VERSION "dbc-export 1 2026.26.6.5"

NS_ :

BS_:

BU_: APP APS BMS CC CMP CMPD CP DAS DI DIF DIR EPBL EPBR EVSE FC GTW HCML HCMR HVP ICR PCS PCS2 PLG PM PMF PMR PTC SCCM SCM SCS SDCR TAS UMC V2G VC VCBATT VCBATT0 VCBATT1 VCBATT2 VCFRONT VCFRONT1 VCFRONT2 VCLEFT VCRIGHT VCSEAT2L VCSEAT2R VCSEC

BO_ 914 BMS_packConfig: 8 BMS
 SG_ BMS_packConfigMultiplexer M : 0|8@1+ (1,0) [0|255] "" Vector__XXX
 SG_ BMS_reservedConfig_0 m0 : 8|6@1+ (1,0) [0|63] "" Vector__XXX
 SG_ BMS_moduleType m1 : 8|3@1+ (1,0) [0|7] "" Vector__XXX
 SG_ BMS_thermalPackType m1 : 11|4@1+ (1,0) [0|15] "" Vector__XXX
 SG_ BMS_packMass m1 : 16|8@1+ (1,300) [342|540] "kg" Vector__XXX
 SG_ BMS_platformMaxBusVoltage m1 : 24|10@1+ (1,300) [300|1300] "V" Vector__XXX
 SG_ BMS_standbySupplyContinuousPower m1 : 36|2@1+ (1,0) [0|3] "" Vector__XXX
 SG_ BMS_beginningOfLifePackEnergy m1 : 40|10@1+ (0.1,0) [0|102.2] "KWh" Vector__XXX

BO_ 1810 BMS_packTemperatureMeasurements: 8 BMS
 SG_ BMS_packTemperatureMultiplexer M : 0|8@1+ (1,0) [0|255] "" Vector__XXX
 SG_ BMS_packTemperatureCounter : 14|2@1+ (1,0) [0|3] "" Vector__XXX
 SG_ BMS_packTemperatureStatus1 m0 : 8|2@1+ (1,0) [0|3] "" Vector__XXX
 SG_ BMS_packTemperatureStatus2 m0 : 10|2@1+ (1,0) [0|3] "" Vector__XXX
 SG_ BMS_packTemperatureStatus3 m0 : 12|2@1+ (1,0) [0|3] "" Vector__XXX
 SG_ BMS_packTemperature1 m0 : 16|16@1- (0.01,0) [-327.68|327.67] "C" Vector__XXX
 SG_ BMS_packTemperature2 m0 : 32|16@1- (0.01,0) [-327.68|327.67] "C" Vector__XXX
 SG_ BMS_packTemperature3 m0 : 48|16@1- (0.01,0) [-327.68|327.67] "C" Vector__XXX
 SG_ BMS_packTemperatureStatus4 m1 : 8|2@1+ (1,0) [0|3] "" Vector__XXX
 SG_ BMS_packTemperatureStatus5 m1 : 10|2@1+ (1,0) [0|3] "" Vector__XXX
 SG_ BMS_packTemperatureStatus6 m1 : 12|2@1+ (1,0) [0|3] "" Vector__XXX
 SG_ BMS_packTemperature4 m1 : 16|16@1- (0.01,0) [-327.68|327.67] "C" Vector__XXX
 SG_ BMS_packTemperature5 m1 : 32|16@1- (0.01,0) [-327.68|327.67] "C" Vector__XXX
 SG_ BMS_packTemperature6 m1 : 48|16@1- (0.01,0) [-327.68|327.67] "C" Vector__XXX
 SG_ BMS_packTemperatureStatus7 m2 : 8|2@1+ (1,0) [0|3] "" Vector__XXX
 SG_ BMS_packTemperatureStatus8 m2 : 10|2@1+ (1,0) [0|3] "" Vector__XXX
 SG_ BMS_packTemperatureStatus9 m2 : 12|2@1+ (1,0) [0|3] "" Vector__XXX
 SG_ BMS_packTemperature7 m2 : 16|16@1- (0.01,0) [-327.68|327.67] "C" Vector__XXX
 SG_ BMS_packTemperature8 m2 : 32|16@1- (0.01,0) [-327.68|327.67] "C" Vector__XXX
 SG_ BMS_packTemperature9 m2 : 48|16@1- (0.01,0) [-327.68|327.67] "C" Vector__XXX
 SG_ BMS_packTemperatureStatus10 m3 : 8|2@1+ (1,0) [0|3] "" Vector__XXX
 SG_ BMS_packTemperatureStatus11 m3 : 10|2@1+ (1,0) [0|3] "" Vector__XXX
 SG_ BMS_packTemperatureStatus12 m3 : 12|2@1+ (1,0) [0|3] "" Vector__XXX
 SG_ BMS_packTemperature10 m3 : 16|16@1- (0.01,0) [-327.68|327.67] "C" Vector__XXX
 SG_ BMS_packTemperature11 m3 : 32|16@1- (0.01,0) [-327.68|327.67] "C" Vector__XXX
 SG_ BMS_packTemperature12 m3 : 48|16@1- (0.01,0) [-327.68|327.67] "C" Vector__XXX
 SG_ BMS_packTemperatureStatus13 m4 : 8|2@1+ (1,0) [0|3] "" Vector__XXX
 SG_ BMS_packTemperatureStatus14 m4 : 10|2@1+ (1,0) [0|3] "" Vector__XXX
 SG_ BMS_packTemperatureStatus15 m4 : 12|2@1+ (1,0) [0|3] "" Vector__XXX
 SG_ BMS_packTemperature13 m4 : 16|16@1- (0.01,0) [-327.68|327.67] "C" Vector__XXX
 SG_ BMS_packTemperature14 m4 : 32|16@1- (0.01,0) [-327.68|327.67] "C" Vector__XXX
 SG_ BMS_packTemperature15 m4 : 48|16@1- (0.01,0) [-327.68|327.67] "C" Vector__XXX
 SG_ BMS_packTemperatureStatus16 m5 : 8|2@1+ (1,0) [0|3] "" Vector__XXX
 SG_ BMS_packTemperatureStatus17 m5 : 10|2@1+ (1,0) [0|3] "" Vector__XXX
 SG_ BMS_packTemperatureStatus18 m5 : 12|2@1+ (1,0) [0|3] "" Vector__XXX
 SG_ BMS_packTemperature16 m5 : 16|16@1- (0.01,0) [-327.68|327.67] "C" Vector__XXX
 SG_ BMS_packTemperature17 m5 : 32|16@1- (0.01,0) [-327.68|327.67] "C" Vector__XXX
 SG_ BMS_packTemperature18 m5 : 48|16@1- (0.01,0) [-327.68|327.67] "C" Vector__XXX

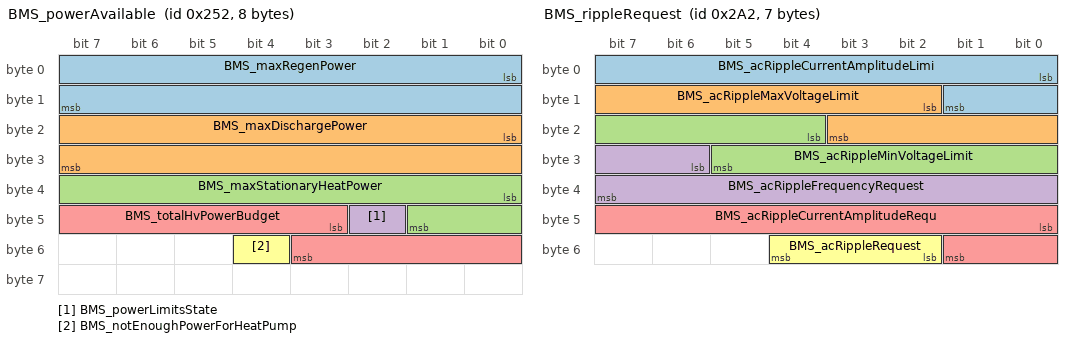
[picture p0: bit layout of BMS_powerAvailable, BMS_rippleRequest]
BO_ 594 BMS_powerAvailable: 8 BMS
 SG_ BMS_maxRegenPower : 0|16@1+ (0.01,0) [0|655.35] "kW" Vector__XXX
 SG_ BMS_maxDischargePower : 16|16@1+ (0.013,0) [0|850] "kW" Vector__XXX
 SG_ BMS_maxStationaryHeatPower : 32|10@1+ (0.01,0) [0|10.23] "kW" Vector__XXX
 SG_ BMS_powerLimitsState : 42|1@1+ (1,0) [0|1] "" Vector__XXX
 SG_ BMS_totalHvPowerBudget : 43|9@1+ (0.1,0) [0|51.1] "kW" Vector__XXX
 SG_ BMS_notEnoughPowerForHeatPump : 52|1@1+ (1,0) [0|1] "" Vector__XXX

BO_ 674 BMS_rippleRequest: 7 BMS
 SG_ BMS_acRippleCurrentAmplitudeLimi : 0|10@1+ (1,0) [0|1023] "A" Vector__XXX
 SG_ BMS_acRippleMaxVoltageLimit : 10|10@1+ (1,0) [0|1023] "V" Vector__XXX
 SG_ BMS_acRippleMinVoltageLimit : 20|10@1+ (1,0) [0|1023] "V" Vector__XXX
 SG_ BMS_acRippleFrequencyRequest : 30|10@1+ (1,0) [0|1022] "Hz" Vector__XXX
 SG_ BMS_acRippleCurrentAmplitudeRequ : 40|10@1+ (1,0) [0|1023] "A" Vector__XXX
 SG_ BMS_acRippleRequest : 50|3@1+ (1,0) [0|7] "" Vector__XXX

BO_ 1834 BMS_serialNumber: 8 BMS
 SG_ BMS_serialNumberMultiplexer M : 0|2@1+ (1,0) [0|2] "" Vector__XXX
 SG_ BMS_packSerialNumberByte01 m0 : 8|8@1+ (1,0) [0|255] "" Vector__XXX
 SG_ BMS_packSerialNumberByte02 m0 : 16|8@1+ (1,0) [0|255] "" Vector__XXX
 SG_ BMS_packSerialNumberByte03 m0 : 24|8@1+ (1,0) [0|255] "" Vector__XXX
 SG_ BMS_packSerialNumberByte04 m0 : 32|8@1+ (1,0) [0|255] "" Vector__XXX
 SG_ BMS_packSerialNumberByte05 m0 : 40|8@1+ (1,0) [0|255] "" Vector__XXX
 SG_ BMS_packSerialNumberByte06 m0 : 48|8@1+ (1,0) [0|255] "" Vector__XXX
 SG_ BMS_packSerialNumberByte07 m0 : 56|8@1+ (1,0) [0|255] "" Vector__XXX
 SG_ BMS_packSerialNumberByte08 m1 : 8|8@1+ (1,0) [0|255] "" Vector__XXX
 SG_ BMS_packSerialNumberByte09 m1 : 16|8@1+ (1,0) [0|255] "" Vector__XXX
 SG_ BMS_packSerialNumberByte10 m1 : 24|8@1+ (1,0) [0|255] "" Vector__XXX
 SG_ BMS_packSerialNumberByte11 m1 : 32|8@1+ (1,0) [0|255] "" Vector__XXX
 SG_ BMS_packSerialNumberByte12 m1 : 40|8@1+ (1,0) [0|255] "" Vector__XXX
 SG_ BMS_packSerialNumberByte13 m1 : 48|8@1+ (1,0) [0|255] "" Vector__XXX
 SG_ BMS_packSerialNumberByte14 m1 : 56|8@1+ (1,0) [0|255] "" Vector__XXX
 SG_ BMS_packSerialBirthDateBinned m2 : 8|32@1+ (1,0) [0|4294967295] "" Vector__XXX

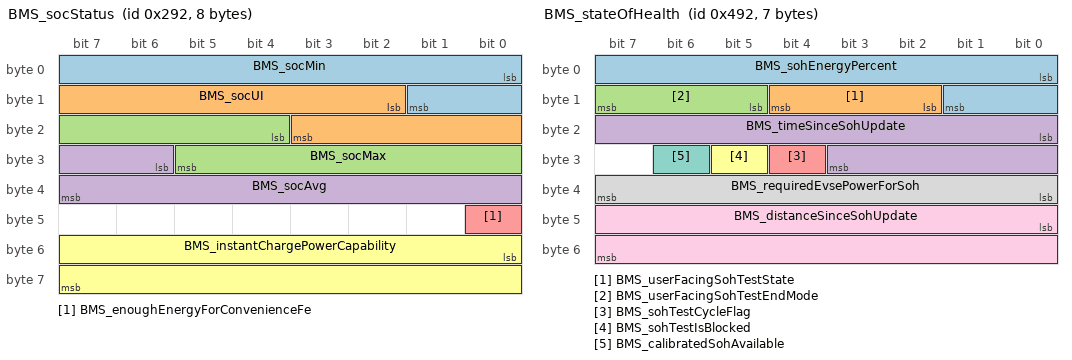
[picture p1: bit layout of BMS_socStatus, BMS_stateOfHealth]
BO_ 658 BMS_socStatus: 8 BMS
 SG_ BMS_socMin : 0|10@1+ (0.1,0) [0|102.2] "%" Vector__XXX
 SG_ BMS_socUI : 10|10@1+ (0.1,0) [0|100] "%" Vector__XXX
 SG_ BMS_socMax : 20|10@1+ (0.1,0) [0|102.2] "%" Vector__XXX
 SG_ BMS_socAvg : 30|10@1+ (0.1,0) [0|102.2] "%" Vector__XXX
 SG_ BMS_enoughEnergyForConvenienceFe : 40|1@1+ (1,0) [0|1] "" Vector__XXX
 SG_ BMS_instantChargePowerCapability : 48|16@1+ (0.05,0) [0|3276.7] "kW" Vector__XXX

BO_ 1170 BMS_stateOfHealth: 7 BMS
 SG_ BMS_sohEnergyPercent : 0|10@1+ (0.1,0) [0|100] "%" Vector__XXX
 SG_ BMS_userFacingSohTestState : 10|3@1+ (1,0) [0|7] "" Vector__XXX
 SG_ BMS_userFacingSohTestEndMode : 13|3@1+ (1,0) [0|7] "" Vector__XXX
 SG_ BMS_timeSinceSohUpdate : 16|12@1+ (1,0) [0|3650] "days" Vector__XXX
 SG_ BMS_sohTestCycleFlag : 28|1@1+ (1,0) [0|1] "" Vector__XXX
 SG_ BMS_sohTestIsBlocked : 29|1@1+ (1,0) [0|1] "" Vector__XXX
 SG_ BMS_calibratedSohAvailable : 30|1@1+ (1,0) [0|1] "" Vector__XXX
 SG_ BMS_requiredEvsePowerForSoh : 32|8@1+ (0.125,0) [0|31.75] "kW" Vector__XXX
 SG_ BMS_distanceSinceSohUpdate : 40|16@1+ (1,0) [0|65534] "km" Vector__XXX

BO_ 530 BMS_status: 8 BMS
 SG_ BMS_hvacPowerRequest : 0|1@1+ (1,0) [0|1] "" Vector__XXX
 SG_ BMS_notEnoughPowerForDrive : 1|1@1+ (1,0) [0|1] "" Vector__XXX
 SG_ BMS_notEnoughPowerForSupport : 2|1@1+ (1,0) [0|1] "" Vector__XXX
 SG_ BMS_preconditionAllowed : 3|1@1+ (1,0) [0|1] "" Vector__XXX
 SG_ BMS_updateAllowed : 4|1@1+ (1,0) [0|1] "" Vector__XXX
 SG_ BMS_cpMiaOnHvs : 5|1@1+ (1,0) [0|1] "" Vector__XXX
 SG_ BMS_pcsPwmEnabled : 6|1@1+ (1,0) [0|1] "" Vector__XXX
 SG_ BMS_contactorState : 8|3@1+ (1,0) [1|7] "" Vector__XXX
 SG_ BMS_userChargeStatus : 11|3@1+ (1,0) [0|7] "" Vector__XXX
 SG_ BMS_batteryInputPower : 14|16@1+ (0.05,0) [0|3276.7] "kW" Vector__XXX
 SG_ BMS_chargeRequest : 30|1@1+ (1,0) [0|1] "" Vector__XXX
 SG_ BMS_state : 32|4@1+ (1,0) [0|15] "" Vector__XXX
 SG_ BMS_diLimpRequest : 36|1@1+ (1,0) [0|1] "" Vector__XXX
 SG_ BMS_okToShipByAir : 37|1@1+ (1,0) [0|1] "" Vector__XXX
 SG_ BMS_okToShipByLand : 38|1@1+ (1,0) [0|1] "" Vector__XXX
 SG_ BMS_chgPowerAvailable : 39|12@1+ (0.125,0) [0|511.75] "kW" Vector__XXX
 SG_ BMS_acManagerState : 52|4@1+ (1,0) [0|15] "" Vector__XXX
 SG_ BMS_conditioningRequest : 56|1@1+ (1,0) [0|1] "" Vector__XXX
 SG_ BMS_smStateRequest : 57|4@1+ (1,0) [0|15] "" Vector__XXX
 SG_ BMS_hvState : 61|3@1+ (1,0) [0|7] "" Vector__XXX

BO_ 786 BMS_thermalStatus: 8 BMS
 SG_ BMS_thermalStatusMultiplexer M : 0|2@1+ (1,0) [0|3] "" Vector__XXX
 SG_ BMS_inletActiveCoolTargetT m0 : 2|9@1+ (0.25,-25) [-25|100] "DegC" Vector__XXX
 SG_ BMS_inletPassiveTargetT m0 : 11|9@1+ (0.25,-25) [-25|100] "DegC" Vector__XXX
 SG_ BMS_inletActiveHeatTargetT m0 : 20|9@1+ (0.25,-25) [-25|100] "DegC" Vector__XXX
 SG_ BMS_requestDischarge m0 : 29|1@1+ (1,0) [0|1] "" Vector__XXX
 SG_ BMS_activeHeatingWorthwhile m0 : 30|1@1+ (1,0) [0|1] "" Vector__XXX
 SG_ BMS_pcsNoFlowRequest m0 : 31|1@1+ (1,0) [0|1] "" Vector__XXX
 SG_ BMS_minPackTemperature m0 : 32|10@1+ (0.2,-40) [-40|164.6] "DegC" Vector__XXX
 SG_ BMS_noFlowRequest m0 : 42|1@1+ (1,0) [0|1] "" Vector__XXX
 SG_ BMS_maxPackTemperature m0 : 43|11@1+ (0.1,-40) [-40|164.7] "DegC" Vector__XXX
 SG_ BMS_flowRequest m0 : 56|8@1+ (0.25,0) [0|60] "LPM" Vector__XXX
 SG_ BMS_coldStagnationLimit m1 : 2|9@1+ (0.25,-25) [-25|100] "DegC" Vector__XXX
 SG_ BMS_hotStagnationLimit m1 : 11|9@1+ (0.25,-25) [-25|100] "DegC" Vector__XXX
 SG_ BMS_hotCellTempLimit m1 : 20|9@1+ (0.25,-25) [-25|100] "DegC" Vector__XXX
 SG_ BMS_i2tDeratingEnabled m1 : 29|1@1+ (1,0) [0|1] "" Vector__XXX
 SG_ BMS_activeCoolCellReferenceT m1 : 32|9@1+ (0.25,-25) [-25|100] "DegC" Vector__XXX
 SG_ BMS_activeHeatCellTargetT m1 : 41|9@1+ (0.25,-25) [-25|100] "DegC" Vector__XXX
 SG_ BMS_powerDissipation m1 : 50|10@1+ (0.02,0) [0|20] "kW" Vector__XXX

BO_ 1554 BMS_udsResponse: 8 BMS
 SG_ BMS_udsResponseData : 7|64@0+ (1,0) [0|1.84467440737e+19] "" Vector__XXX

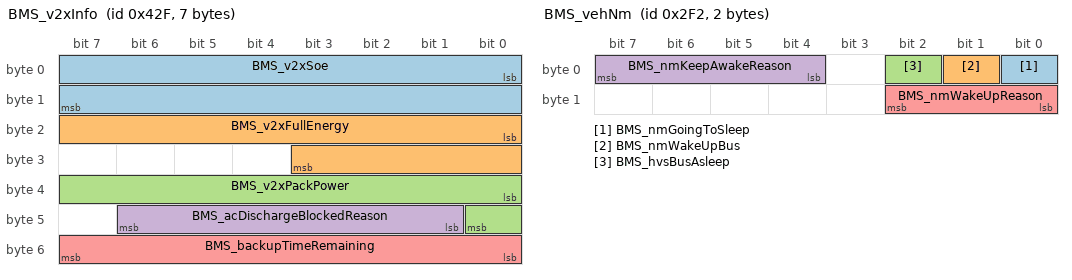
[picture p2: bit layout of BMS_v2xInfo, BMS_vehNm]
BO_ 1071 BMS_v2xInfo: 7 BMS
 SG_ BMS_v2xSoe : 0|16@1+ (0.002,0) [0|100] "%" Vector__XXX
 SG_ BMS_v2xFullEnergy : 16|12@1+ (0.05,0) [0|200] "kWh" Vector__XXX
 SG_ BMS_v2xPackPower : 32|9@1+ (0.1,-25) [-25|25] "kW" Vector__XXX
 SG_ BMS_acDischargeBlockedReason : 41|6@1+ (1,0) [0|63] "" Vector__XXX
 SG_ BMS_backupTimeRemaining : 48|8@1+ (1,0) [0|254] "Hours" Vector__XXX

BO_ 754 BMS_vehNm: 2 BMS
 SG_ BMS_nmGoingToSleep : 0|1@1+ (1,0) [0|1] "" Vector__XXX
 SG_ BMS_nmWakeUpBus : 1|1@1+ (1,0) [0|1] "" Vector__XXX
 SG_ BMS_hvsBusAsleep : 2|1@1+ (1,0) [0|1] "" Vector__XXX
 SG_ BMS_nmKeepAwakeReason : 4|4@1+ (1,0) [1|15] "" Vector__XXX
 SG_ BMS_nmWakeUpReason : 8|3@1+ (1,0) [0|7] "" Vector__XXX

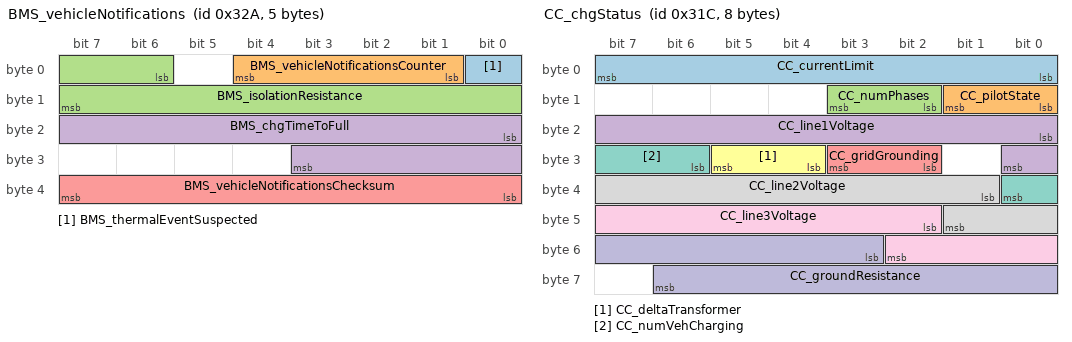
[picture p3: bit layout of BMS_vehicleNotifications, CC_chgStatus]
BO_ 810 BMS_vehicleNotifications: 5 BMS
 SG_ BMS_thermalEventSuspected : 0|1@1+ (1,0) [0|1] "" Vector__XXX
 SG_ BMS_vehicleNotificationsCounter : 1|4@1+ (1,0) [0|15] "" Vector__XXX
 SG_ BMS_isolationResistance : 6|10@1+ (10,0) [0|10000] "kOhm" Vector__XXX
 SG_ BMS_chgTimeToFull : 16|12@1+ (0.01666667,0) [0|68.23334698] "Hours" Vector__XXX
 SG_ BMS_vehicleNotificationsChecksum : 32|8@1+ (1,0) [0|255] "" Vector__XXX

BO_ 1116 CC_alertLog: 8 CC
 SG_ CC_alertID M : 0|15@1+ (1,0) [0|32767] "" Vector__XXX
 SG_ CC_alertType : 15|1@1+ (1,0) [0|1] "" Vector__XXX
 SG_ CC_a001_groundResistance m1 : 16|12@1+ (1000,0) [0|4094000] "Ohm" Vector__XXX
 SG_ CC_a003_gfciRmsCurrent m3 : 16|12@1+ (0.001,0) [0|4.095] "A" Vector__XXX
 SG_ CC_a003_gfciRmsCurrentAvg m3 : 28|12@1+ (0.001,0) [0|4.095] "A" Vector__XXX
 SG_ CC_a003_dcGfciCurrent m3 : 40|10@1- (0.001,0) [-0.512|0.511] "A" Vector__XXX
 SG_ CC_a003_gfciFaultReason m3 : 50|4@1+ (1,0) [1|15] "" Vector__XXX
 SG_ CC_a003_gfciFaultBucket m3 : 56|4@1+ (1,0) [0|15] "" Vector__XXX
 SG_ CC_a004_gfciErrorReason m4 : 16|8@1+ (1,0) [1|255] "" Vector__XXX
 SG_ CC_a004_gfciAsicErrorBitfield m4 : 24|8@1+ (1,0) [0|255] "" Vector__XXX
 SG_ CC_a004_gfciSelfTestDuty m4 : 32|16@1- (0.0001,50) [46.7232|53.2767] "A" Vector__XXX
 SG_ CC_a004_gfciSelfTestCurrent m4 : 48|16@1- (0.0001,0) [-3.2768|3.2767] "A" Vector__XXX
 SG_ CC_a006_line1Current m6 : 16|16@1+ (0.01,0) [0|655.35] "A" Vector__XXX
 SG_ CC_a006_line2Current m6 : 32|16@1+ (0.01,0) [0|655.35] "A" Vector__XXX
 SG_ CC_a006_line3Current m6 : 48|16@1+ (0.01,0) [0|655.35] "A" Vector__XXX
 SG_ CC_a007_inputVoltage m7 : 16|16@1+ (0.01,0) [0|655.35] "V" Vector__XXX
 SG_ CC_a007_inputLineVoltage m7 : 32|16@1+ (0.01,0) [0|655.35] "V" Vector__XXX
 SG_ CC_a007_inputNeutralVoltage m7 : 48|16@1+ (0.01,0) [0|655.35] "V" Vector__XXX
 SG_ CC_a008_inputVoltage m8 : 16|16@1+ (0.01,0) [0|655.35] "V" Vector__XXX
 SG_ CC_a008_inputLineVoltage m8 : 32|16@1+ (0.01,0) [0|655.35] "V" Vector__XXX
 SG_ CC_a008_inputNeutralVoltage m8 : 48|16@1+ (0.01,0) [0|655.35] "V" Vector__XXX
 SG_ CC_a010_line1Voltage m10 : 16|12@1+ (0.1,0) [0|409.5] "V" Vector__XXX
 SG_ CC_a010_line2Voltage m10 : 28|12@1+ (0.1,0) [0|409.5] "V" Vector__XXX
 SG_ CC_a010_line3Voltage m10 : 40|12@1+ (0.1,0) [0|409.5] "V" Vector__XXX
 SG_ CC_a010_line1StuckClosed m10 : 52|1@1+ (1,0) [0|1] "" Vector__XXX
 SG_ CC_a010_line2StuckClosed m10 : 53|1@1+ (1,0) [0|1] "" Vector__XXX
 SG_ CC_a010_line3StuckClosed m10 : 54|1@1+ (1,0) [0|1] "" Vector__XXX
 SG_ CC_a011_pcbaTemp m11 : 16|9@1- (1,88) [-168|343] "DegC" Vector__XXX
 SG_ CC_a012_inputThermopile m12 : 16|12@1+ (1.0e-06,0) [0|0.004095] "V" Vector__XXX
 SG_ CC_a012_inputThermopileDvdt m12 : 28|12@1+ (1.0e-06,0) [0|0.004095] "V/sec" Vector__XXX
 SG_ CC_a013_handleTemp m13 : 16|9@1- (1,88) [-168|343] "DegC" Vector__XXX
 SG_ CC_a014_failureCause m14 : 16|9@1+ (1,0) [0|511] "" Vector__XXX
 SG_ CC_a014_meterFaultAddress m14 : 25|16@1+ (1,0) [0|65535] "" Vector__XXX
 SG_ CC_a014_meterFaultData m14 : 41|16@1+ (1,0) [0|65535] "" Vector__XXX
 SG_ CC_a014_meterRetryCount m14 : 57|4@1+ (1,0) [0|15] "" Vector__XXX
 SG_ CC_a015_pilotHighVolage m15 : 16|16@1+ (0.001,0) [0|65.535] "V" Vector__XXX
 SG_ CC_a015_smState m15 : 32|8@1+ (1,0) [0|255] "" Vector__XXX
 SG_ CC_a027_handleTemperature m27 : 16|12@1- (0.1,0) [-204.8|204.7] "DegC" Vector__XXX
 SG_ CC_a027_handleTempFaultReason m27 : 28|4@1+ (1,0) [0|15] "" Vector__XXX
 SG_ CC_a032_meteringSpiCommsFailure m32 : 16|1@1+ (1,0) [0|1] "" Vector__XXX
 SG_ CC_a032_meteringConfigMismatch m32 : 17|1@1+ (1,0) [0|1] "" Vector__XXX
 SG_ CC_a033_nominalVoltage m33 : 16|9@1+ (0.01,0) [0|5.11] "V" Vector__XXX
 SG_ CC_a033_measuredVoltage m33 : 25|9@1+ (0.01,0) [0|5.11] "V" Vector__XXX
 SG_ CC_a036_line1Voltage m36 : 16|12@1+ (0.1,0) [0|409.5] "V" Vector__XXX
 SG_ CC_a036_line2Voltage m36 : 28|12@1+ (0.1,0) [0|409.5] "V" Vector__XXX
 SG_ CC_a036_line3Voltage m36 : 40|12@1+ (0.1,0) [0|409.5] "V" Vector__XXX
 SG_ CC_a036_line1StuckOpen m36 : 52|1@1+ (1,0) [0|1] "" Vector__XXX
 SG_ CC_a036_line2StuckOpen m36 : 53|1@1+ (1,0) [0|1] "" Vector__XXX
 SG_ CC_a036_line3StuckOpen m36 : 54|1@1+ (1,0) [0|1] "" Vector__XXX
 SG_ CC_a037_expiredWatchdogModuleId m37 : 16|8@1+ (1,0) [0|255] "" Vector__XXX
 SG_ CC_a037_expiredWatchdogTaskId m37 : 24|8@1+ (1,0) [0|255] "" Vector__XXX
 SG_ CC_a037_expiredWatchdogAppCRC m37 : 32|32@1+ (1,0) [0|4294967295] "" Vector__XXX
 SG_ CC_a038_moduleMiaModuleId m38 : 16|8@1+ (1,0) [0|255] "" Vector__XXX
 SG_ CC_a038_moduleMiaTaskId m38 : 24|8@1+ (1,0) [0|255] "" Vector__XXX
 SG_ CC_a038_moduleMiaAppCRC m38 : 32|32@1+ (1,0) [0|4294967295] "" Vector__XXX
 SG_ CC_a039_intModuleTemperature m39 : 16|9@1- (1,88) [-168|343] "DegC" Vector__XXX
 SG_ CC_a040_handleTemperature m40 : 16|9@1- (1,88) [-168|343] "DegC" Vector__XXX
 SG_ CC_a041_inputThermopile m41 : 16|16@1- (1.0e-06,0) [-0.032768|0.032767] "V" Vector__XXX
 SG_ CC_a041_inputThermopileDvdt m41 : 32|16@1- (1.0e-06,0) [-0.032768|0.032767] "V/sec" Vector__XXX
 SG_ CC_a042_pcbaTemperature m42 : 16|9@1- (1,88) [-168|343] "DegC" Vector__XXX
 SG_ CC_a044_relayCoilVoltage m44 : 16|8@1+ (0.14,0) [0|35.7] "V" Vector__XXX
 SG_ CC_a044_pcbaTemperature m44 : 24|9@1- (1,88) [-168|343] "DegC" Vector__XXX

BO_ 1132 CC_alertMatrix1: 8 CC
 SG_ CC_a001_gndMonIntrptLineSide : 0|1@1+ (1,0) [0|1] "" Vector__XXX
 SG_ CC_a002_gndMonIntrptLoadSide : 1|1@1+ (1,0) [0|1] "" Vector__XXX
 SG_ CC_a003_CCIDTripped : 2|1@1+ (1,0) [0|1] "" Vector__XXX
 SG_ CC_a004_CCIDSelfTestFault : 3|1@1+ (1,0) [0|1] "" Vector__XXX
 SG_ CC_a005_groundedNeutral : 4|1@1+ (1,0) [0|1] "" Vector__XXX
 SG_ CC_a006_inputOverCurrent : 5|1@1+ (1,0) [0|1] "" Vector__XXX
 SG_ CC_a007_inputOverVoltage : 6|1@1+ (1,0) [0|1] "" Vector__XXX
 SG_ CC_a008_inputUnderVoltage : 7|1@1+ (1,0) [0|1] "" Vector__XXX
 SG_ CC_a009_inputMiswired : 8|1@1+ (1,0) [0|1] "" Vector__XXX
 SG_ CC_a010_contactorWelded : 9|1@1+ (1,0) [0|1] "" Vector__XXX
 SG_ CC_a011_ambientOT : 10|1@1+ (1,0) [0|1] "" Vector__XXX
 SG_ CC_a012_wallPlugOT : 11|1@1+ (1,0) [0|1] "" Vector__XXX
 SG_ CC_a013_vehConnOT : 12|1@1+ (1,0) [0|1] "" Vector__XXX
 SG_ CC_a014_mcuSelfTestFault : 13|1@1+ (1,0) [0|1] "" Vector__XXX
 SG_ CC_a015_PilotAFault : 14|1@1+ (1,0) [0|1] "" Vector__XXX
 SG_ CC_a016_PilotBFault : 15|1@1+ (1,0) [0|1] "" Vector__XXX
 SG_ CC_a017_PilotCFault : 16|1@1+ (1,0) [0|1] "" Vector__XXX
 SG_ CC_a018_PilotDFault : 17|1@1+ (1,0) [0|1] "" Vector__XXX
 SG_ CC_a019_proxDisconnected : 18|1@1+ (1,0) [0|1] "" Vector__XXX
 SG_ CC_a020_3vRailIncorrect : 19|1@1+ (1,0) [0|1] "" Vector__XXX
 SG_ CC_a021_CB_noMaster : 20|1@1+ (1,0) [0|1] "" Vector__XXX
 SG_ CC_a022_CB_tooManyMasters : 21|1@1+ (1,0) [0|1] "" Vector__XXX
 SG_ CC_a023_CB_tooManySlaves : 22|1@1+ (1,0) [0|1] "" Vector__XXX
 SG_ CC_a024_CB_masterISetTooLow : 23|1@1+ (1,0) [0|1] "" Vector__XXX
 SG_ CC_a025_evseTemp : 24|1@1+ (1,0) [0|1] "" Vector__XXX
 SG_ CC_a026_wallPlugTemp : 25|1@1+ (1,0) [0|1] "" Vector__XXX
 SG_ CC_a027_vehicleHandleTemp : 26|1@1+ (1,0) [0|1] "" Vector__XXX
 SG_ CC_a028_CB_rotarySelect : 27|1@1+ (1,0) [0|1] "" Vector__XXX
 SG_ CC_a029_PilotFFault : 28|1@1+ (1,0) [0|1] "" Vector__XXX
 SG_ CC_a030_masterSlaveMismatch : 29|1@1+ (1,0) [0|1] "" Vector__XXX
 SG_ CC_a031_pllLockLost : 30|1@1+ (1,0) [0|1] "" Vector__XXX
 SG_ CC_a032_meteringFailure : 31|1@1+ (1,0) [0|1] "" Vector__XXX
 SG_ CC_a033_vRefOutOfRange : 32|1@1+ (1,0) [0|1] "" Vector__XXX
 SG_ CC_a034_bootAlert : 33|1@1+ (1,0) [0|1] "" Vector__XXX
 SG_ CC_a035_CCIDCalibration : 34|1@1+ (1,0) [0|1] "" Vector__XXX
 SG_ CC_a036_contactorStuckOpen : 35|1@1+ (1,0) [0|1] "" Vector__XXX
 SG_ CC_a037_internalModuleWatchdogEx : 36|1@1+ (1,0) [0|1] "" Vector__XXX
 SG_ CC_a038_internalModuleMia : 37|1@1+ (1,0) [0|1] "" Vector__XXX
 SG_ CC_a039_internalModuleOverTemp : 38|1@1+ (1,0) [0|1] "" Vector__XXX
 SG_ CC_a040_handleTempFoldback : 39|1@1+ (1,0) [0|1] "" Vector__XXX
 SG_ CC_a041_inputWiringFoldback : 40|1@1+ (1,0) [0|1] "" Vector__XXX
 SG_ CC_a042_pcbaTempFoldback : 41|1@1+ (1,0) [0|1] "" Vector__XXX
 SG_ CC_a043_configurationRequired : 42|1@1+ (1,0) [0|1] "" Vector__XXX
 SG_ CC_a044_relayCoilVoltageRational : 43|1@1+ (1,0) [0|1] "" Vector__XXX
 SG_ CC_a045_ACPowerLoss : 44|1@1+ (1,0) [0|1] "" Vector__XXX
 SG_ CC_a046_GFCIConfigInvalid : 45|1@1+ (1,0) [0|1] "" Vector__XXX
 SG_ CC_a047_MDMotorContFault : 46|1@1+ (1,0) [0|1] "" Vector__XXX
 SG_ CC_a048_ACMDAdapterFault : 47|1@1+ (1,0) [0|1] "" Vector__XXX
 SG_ CC_a049_rs485Fault : 48|1@1+ (1,0) [0|1] "" Vector__XXX
 SG_ CC_a050_eFuseFault : 49|1@1+ (1,0) [0|1] "" Vector__XXX
 SG_ CC_a051_chcCriticalFault : 50|1@1+ (1,0) [0|1] "" Vector__XXX
 SG_ CC_a052_vRefOutOfRangePWM : 51|1@1+ (1,0) [0|1] "" Vector__XXX
 SG_ CC_a057_chcVitalsRequestFailure : 56|1@1+ (1,0) [0|1] "" Vector__XXX
 SG_ CC_a060_persistenceFault : 59|1@1+ (1,0) [0|1] "" Vector__XXX
 SG_ CC_a061_unfinishedCommissioning : 60|1@1+ (1,0) [0|1] "" Vector__XXX

BO_ 796 CC_chgStatus: 8 CC
 SG_ CC_currentLimit : 0|8@1+ (0.5,0) [0|127] "A" Vector__XXX
 SG_ CC_pilotState : 8|2@1+ (1,0) [0|2] "" Vector__XXX
 SG_ CC_numPhases : 10|2@1+ (1,0) [1|3] "" Vector__XXX
 SG_ CC_line1Voltage : 16|9@1+ (1,0) [0|510] "V" Vector__XXX
 SG_ CC_gridGrounding : 26|2@1+ (1,0) [0|3] "" Vector__XXX
 SG_ CC_deltaTransformer : 28|2@1+ (1,0) [0|3] "" Vector__XXX
 SG_ CC_numVehCharging : 30|3@1+ (1,0) [0|7] "" Vector__XXX
 SG_ CC_line2Voltage : 33|9@1+ (1,0) [0|510] "V" Vector__XXX
 SG_ CC_line3Voltage : 42|9@1+ (1,0) [0|510] "V" Vector__XXX
 SG_ CC_groundResistance : 51|12@1+ (1,0) [0|4094] "kOhm" Vector__XXX

BO_ 797 CC_chgStatus2: 8 CC
 SG_ CC_chgStatus2Index M : 0|8@1+ (1,0) [0|255] "" Vector__XXX
 SG_ CC_buttonState m0 : 8|1@1+ (1,0) [0|1] "" Vector__XXX
 SG_ EVSE_v2xSupport m0 : 9|2@1+ (1,0) [0|3] "" Vector__XXX
 SG_ EVSE_v2xHandshakeStart m0 : 12|1@1+ (1,0) [0|1] "" Vector__XXX
 SG_ EVSE_v2xSessionType m0 : 13|2@1+ (1,0) [1|3] "" Vector__XXX

BO_ 812 CC_logData: 8 CC
 SG_ CC_logIndex M : 0|8@1+ (1,0) [0|255] "" Vector__XXX
 SG_ CC_activeConnectorID m0 : 8|8@1+ (1,0) [0|255] "" Vector__XXX
 SG_ CC_temperature1 m0 : 16|8@1- (1,88) [-40|215] "DegC" Vector__XXX
 SG_ CC_temperature2 m0 : 24|8@1- (1,88) [-40|215] "DegC" Vector__XXX
 SG_ CC_temperature3 m0 : 32|8@1- (1,88) [-40|215] "DegC" Vector__XXX
 SG_ CC_contactor1Closed m0 : 40|2@1+ (1,0) [0|3] "" Vector__XXX
 SG_ CC_contactor2Closed m0 : 42|2@1+ (1,0) [0|3] "" Vector__XXX
 SG_ CC_temperature4 m0 : 44|8@1- (1,88) [-40|215] "DegC" Vector__XXX
 SG_ CC_conn1Current m1 : 8|8@1+ (0.5,0) [0|127] "A" Vector__XXX
 SG_ CC_conn2Current m2 : 8|8@1+ (0.5,0) [0|127] "A" Vector__XXX
 SG_ CC_conn3Current m3 : 8|8@1+ (0.5,0) [0|127] "A" Vector__XXX
 SG_ CC_conn4Current m4 : 8|8@1+ (0.5,0) [0|127] "A" Vector__XXX
 SG_ CC_lifetimei2t m10 : 32|32@1+ (0.1,0) [0|429496729.5] "A2h" Vector__XXX
 SG_ CC_lifetimeCtrCycles m11 : 8|28@1+ (1,0) [0|268435455] "" Vector__XXX
 SG_ CC_lifetimeCtrCyclesLoaded m11 : 36|28@1+ (1,0) [0|268435455] "" Vector__XXX
 SG_ CC_lifetimeAlertCount m12 : 8|28@1+ (1,0) [0|268435455] "" Vector__XXX
 SG_ CC_lifetimeThermalFoldbacks m12 : 36|28@1+ (1,0) [0|268435455] "" Vector__XXX
 SG_ CC_lifetimeAvgStartupTemp m13 : 36|28@1- (0.1,0) [-13421772.8|13421772.7] "degC" Vector__XXX

BO_ 870 CMPD_info: 8 CMPD
 SG_ CMPD_infoIndex M : 0|8@1+ (1,0) [0|255] "" Vector__XXX
 SG_ CMPD_infoBuildType m10 : 8|8@1+ (1,0) [0|255] "" Vector__XXX
 SG_ CMPD_infoBuildConfigId m10 : 16|16@1+ (1,0) [0|65535] "" Vector__XXX
 SG_ CMPD_infoHardwareId m10 : 32|16@1+ (1,0) [0|65535] "" Vector__XXX
 SG_ CMPD_infoComponentId m10 : 48|16@1+ (1,0) [0|65535] "" Vector__XXX
 SG_ CMPD_infoPcbaId m11 : 16|8@1+ (1,0) [0|255] "" Vector__XXX
 SG_ CMPD_infoAssemblyId m11 : 24|8@1+ (1,0) [0|254] "" Vector__XXX
 SG_ CMPD_infoUsageId m11 : 32|16@1+ (1,0) [0|65535] "" Vector__XXX
 SG_ CMPD_infoSubUsageId m11 : 48|16@1+ (1,0) [0|65535] "" Vector__XXX

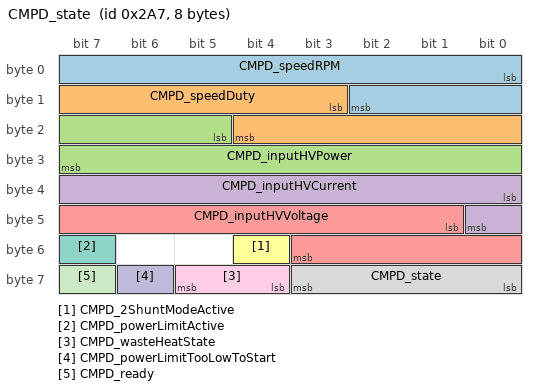
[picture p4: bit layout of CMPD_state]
BO_ 679 CMPD_state: 8 CMPD
 SG_ CMPD_speedRPM : 0|11@1+ (10,0) [0|20000] "RPM" Vector__XXX
 SG_ CMPD_speedDuty : 11|10@1+ (0.1,0) [0|100] "%" Vector__XXX
 SG_ CMPD_inputHVPower : 21|11@1+ (10,0) [0|20000] "W" Vector__XXX
 SG_ CMPD_inputHVCurrent : 32|9@1+ (0.1,0) [0|50] "A" Vector__XXX
 SG_ CMPD_inputHVVoltage : 41|11@1+ (0.5,0) [0|1000] "V" Vector__XXX
 SG_ CMPD_2ShuntModeActive : 52|1@1+ (1,0) [0|1] "" Vector__XXX
 SG_ CMPD_powerLimitActive : 55|1@1+ (1,0) [0|1] "" Vector__XXX
 SG_ CMPD_state : 56|4@1+ (1,0) [0|14] "" Vector__XXX
 SG_ CMPD_wasteHeatState : 60|2@1+ (1,0) [0|3] "" Vector__XXX
 SG_ CMPD_powerLimitTooLowToStart : 62|1@1+ (1,0) [0|1] "" Vector__XXX
 SG_ CMPD_ready : 63|1@1+ (1,0) [0|1] "" Vector__XXX

BO_ 1559 CMPD_udsResponse: 8 CMPD
 SG_ CMPD_udsResponseData : 7|64@0+ (1,0) [0|1.84467440737e+19] "" Vector__XXX

BO_ 867 CMP_info: 8 CMP
 SG_ CMP_infoIndex M : 0|8@1+ (1,0) [0|255] "" Vector__XXX
 SG_ CMP_infoBuildType m10 : 8|8@1+ (1,0) [0|255] "" Vector__XXX
 SG_ CMP_infoBuildConfigId m10 : 16|16@1+ (1,0) [0|65535] "" Vector__XXX
 SG_ CMP_infoHardwareId m10 : 32|16@1+ (1,0) [0|65535] "" Vector__XXX
 SG_ CMP_infoComponentId m10 : 48|16@1+ (1,0) [0|65535] "" Vector__XXX
 SG_ CMP_infoPcbaId m11 : 16|8@1+ (1,0) [0|255] "" Vector__XXX
 SG_ CMP_infoAssemblyId m11 : 24|8@1+ (1,0) [0|254] "" Vector__XXX
 SG_ CMP_infoUsageId m11 : 32|16@1+ (1,0) [0|65535] "" Vector__XXX
 SG_ CMP_infoSubUsageId m11 : 48|16@1+ (1,0) [0|65535] "" Vector__XXX
 SG_ CMP_infoPlatformType m13 : 8|8@1+ (1,0) [0|255] "" Vector__XXX
 SG_ CMP_infoAppCrc m13 : 32|32@1+ (1,0) [0|4294967295] "" Vector__XXX
 SG_ CMP_infoBootUdsProtoVersion m20 : 8|8@1+ (1,0) [0|255] "" Vector__XXX
 SG_ CMP_infoBootCrc m20 : 32|32@1+ (1,0) [0|4294967295] "" Vector__XXX

BO_ 1555 CMP_udsResponse: 8 CMP
 SG_ CMP_udsResponseData : 7|64@0+ (1,0) [0|1.84467440737e+19] "" Vector__XXX

BO_ 1767 CP_IsoTpPipeToPncd: 8 CP
 SG_ CP_isoTpToPncdData : 0|64@1+ (1,0) [0|1.84467440737e+19] "" Vector__XXX

BO_ 1294 CP_alertLog: 8 CP
 SG_ CP_alertID M : 0|15@1+ (1,0) [0|32767] "" Vector__XXX
 SG_ CP_alertType : 15|1@1+ (1,0) [0|1] "" Vector__XXX
 SG_ CP_a004_proximityV m4 : 16|16@1+ (0.0001,0) [0|6.5535] "V" Vector__XXX
 SG_ CP_a004_cc1Voltage m4 : 32|14@1+ (0.001,0) [0|16.383] "V" Vector__XXX
 SG_ CP_a004_cc2Voltage m4 : 48|14@1+ (0.001,0) [0|16.383] "V" Vector__XXX
 SG_ CP_a005_cc1Voltage m5 : 16|11@1+ (0.00649731326848,0) [0|13.3000002606] "V" Vector__XXX
 SG_ CP_a005_cc2Voltage m5 : 27|9@1+ (0.009784736,0) [0|5.000000096] "V" Vector__XXX
 SG_ CP_a005_gbdcState m5 : 36|4@1+ (1,0) [0|15] "" Vector__XXX
 SG_ CP_a005_packCurrent m5 : 40|12@1+ (0.0976801,0) [0|400.0000095] "A" Vector__XXX
 SG_ CP_a005_evseCurrent m5 : 52|10@1+ (0.391006857157,0) [0|400.000014872] "A" Vector__XXX
 SG_ CP_a005_superchargerConnected m5 : 62|1@1+ (1,0) [0|1] "" Vector__XXX
 SG_ CP_a005_latchEngaged m5 : 63|1@1+ (1,0) [0|1] "" Vector__XXX
 SG_ CP_a006_BMS_FC_limits_MIA m6 : 16|1@1+ (1,0) [0|1] "" Vector__XXX
 SG_ CP_a006_BMS_chargeStatus_MIA m6 : 17|1@1+ (1,0) [0|1] "" Vector__XXX
 SG_ CP_a006_BMS_dcChargeLimits_MIA m6 : 18|1@1+ (1,0) [0|1] "" Vector__XXX
 SG_ CP_a006_BMS_hvPackStatus_MIA m6 : 19|1@1+ (1,0) [0|1] "" Vector__XXX
 SG_ CP_a006_BMS_kwhCounter_MIA m6 : 20|1@1+ (1,0) [0|1] "" Vector__XXX
 SG_ CP_a006_BMS_socStatus_MIA m6 : 21|1@1+ (1,0) [0|1] "" Vector__XXX
 SG_ CP_a006_BMS_v2xInfo_MIA m6 : 22|1@1+ (1,0) [0|1] "" Vector__XXX
 SG_ CP_a006_BMS_bmbMinMax_MIA m6 : 23|1@1+ (1,0) [0|1] "" Vector__XXX
 SG_ CP_a006_BMS_evsePackInfo_MIA m6 : 24|1@1+ (1,0) [0|1] "" Vector__XXX
 SG_ CP_a006_BMS_cpFaultLineStatus_MI m6 : 25|1@1+ (1,0) [0|1] "" Vector__XXX
 SG_ CP_a006_BMS_eptoStatus_MIA m6 : 26|1@1+ (1,0) [0|1] "" Vector__XXX
 SG_ CP_a008_data1 m8 : 16|16@1+ (1,0) [0|65535] "" Vector__XXX
 SG_ CP_a008_data2 m8 : 32|16@1+ (1,0) [0|65535] "" Vector__XXX
 SG_ CP_a008_FlashWarning m8 : 48|1@1+ (1,0) [0|1] "" Vector__XXX
 SG_ CP_a008_RAMconst_Warning m8 : 49|1@1+ (1,0) [0|1] "" Vector__XXX
 SG_ CP_a008_RAMconst_Fault m8 : 50|1@1+ (1,0) [0|1] "" Vector__XXX
 SG_ CP_a008_AllMemory_warnings m8 : 51|1@1+ (1,0) [0|1] "" Vector__XXX
 SG_ CP_a008_StackAlert m8 : 52|1@1+ (1,0) [0|1] "" Vector__XXX
 SG_ CP_a008_stackUsed m8 : 56|7@1+ (1,0) [0|127] "%" Vector__XXX
 SG_ CP_a009_cover1OpenCounts m9 : 16|12@1+ (0.025,0) [0|102.375] "%" Vector__XXX
 SG_ CP_a009_cover2OpenCounts m9 : 28|12@1+ (0.025,0) [0|102.375] "%" Vector__XXX
 SG_ CP_a009_cover1State m9 : 40|3@1+ (1,0) [0|7] "" Vector__XXX
 SG_ CP_a009_cover2State m9 : 43|3@1+ (1,0) [0|7] "" Vector__XXX
 SG_ CP_a010_periodValid m10 : 16|1@1+ (1,0) [0|1] "" Vector__XXX
 SG_ CP_a010_widthValid m10 : 17|1@1+ (1,0) [0|1] "" Vector__XXX
 SG_ CP_a010_voltageValid m10 : 18|1@1+ (1,0) [0|1] "" Vector__XXX
 SG_ CP_a010_pilotHigh m10 : 19|12@1- (0.008,0) [-16.384|16.376] "V" Vector__XXX
 SG_ CP_a010_pilotLow m10 : 32|12@1- (0.008,0) [-16.384|16.376] "V" Vector__XXX
 SG_ CP_a010_evseAccept m10 : 44|1@1+ (1,0) [0|1] "" Vector__XXX
 SG_ CP_a010_pilotPWMdetected m10 : 45|1@1+ (1,0) [0|1] "" Vector__XXX
 SG_ CP_a011_eepromErrorType m11 : 16|3@1+ (1,0) [0|7] "" Vector__XXX
 SG_ CP_a015_apsVoltageOV m15 : 16|8@1+ (0.07128516,0) [0|18.1777158] "V" Vector__XXX
 SG_ CP_a016_apsVoltageUV m16 : 16|8@1+ (0.07128516,0) [0|18.1777158] "V" Vector__XXX
 SG_ CP_a017_5V_VoltageOV m17 : 16|8@1+ (0.02352539,0) [0|5.99897445] "V" Vector__XXX
 SG_ CP_a018_5V_VoltageUV m18 : 16|8@1+ (0.02352539,0) [0|5.99897445] "V" Vector__XXX
 SG_ CP_a023_stopChargeReason m23 : 16|4@1+ (1,0) [0|15] "" Vector__XXX
 SG_ CP_a023_failureReason m23 : 20|2@1+ (1,0) [0|3] "" Vector__XXX
 SG_ CP_a023_chargeAttempts m23 : 24|3@1+ (1,0) [0|7] "" Vector__XXX
 SG_ CP_a028_canEnable m28 : 16|1@1+ (1,0) [0|1] "" Vector__XXX
 SG_ CP_a028_hardlineEnable m28 : 17|1@1+ (1,0) [0|1] "" Vector__XXX
 SG_ CP_a029_CP_pilot m29 : 16|3@1+ (1,0) [0|6] "" Vector__XXX
 SG_ CP_a029_CP_proximity m29 : 19|2@1+ (1,0) [1|3] "" Vector__XXX
 SG_ CP_a029_CP_chargeDoorOpen m29 : 21|1@1+ (1,0) [0|1] "" Vector__XXX
 SG_ CP_a031_apsVoltage m31 : 16|8@1+ (0.07156863,0) [0|18.25000065] "V" Vector__XXX
 SG_ CP_a031_doorCountsFiltered m31 : 24|12@1+ (0.025,0) [0|102.375] "%" Vector__XXX
 SG_ CP_a031_inductiveSensorFiltered m31 : 36|18@1+ (82.77924,0) [0|21699998.3113] "Hz" Vector__XXX
 SG_ CP_a031_hallSensorFiltered m31 : 54|10@1+ (0.00488748773932,0) [0|4.99989995732] "V" Vector__XXX
 SG_ CP_a032_apsVoltage m32 : 16|8@1+ (0.07156863,0) [0|18.25000065] "V" Vector__XXX
 SG_ CP_a032_doorCountsFiltered m32 : 24|12@1+ (0.025,0) [0|102.375] "%" Vector__XXX
 SG_ CP_a032_inductiveSensorFiltered m32 : 36|18@1+ (82.77924,0) [0|21699998.3113] "Hz" Vector__XXX
 SG_ CP_a032_hallSensorFiltered m32 : 54|10@1+ (0.00488748773932,0) [0|4.99989995732] "V" Vector__XXX
 SG_ CP_a035_latchState m35 : 16|2@1+ (1,0) [1|3] "" Vector__XXX
 SG_ CP_a035_stateLeverMovedFrom m35 : 18|2@1+ (1,0) [0|3] "" Vector__XXX
 SG_ CP_a035_latchOffset m35 : 24|16@1- (0.003051851,0) [-100.003053568|100.000001717] "%" Vector__XXX
 SG_ CP_a035_inletID m35 : 40|3@1+ (1,0) [0|7] "" Vector__XXX
 SG_ CP_a036_latchCountsFiltered m36 : 16|16@1+ (0.00152590218931,0) [0|99.9999999764] "%" Vector__XXX
 SG_ CP_a036_latchState m36 : 32|2@1+ (1,0) [1|3] "" Vector__XXX
 SG_ CP_a036_CHG_InsertEnable m36 : 34|1@1+ (1,0) [0|1] "" Vector__XXX
 SG_ CP_a036_CP_latchEnableCmd m36 : 35|1@1+ (1,0) [0|1] "" Vector__XXX
 SG_ CP_a036_CP_apsVoltage m36 : 36|12@1+ (0.0170940179378,0) [0|70.0000034553] "V" Vector__XXX
 SG_ CP_a036_inletID m36 : 48|3@1+ (1,0) [0|7] "" Vector__XXX
 SG_ CP_a037_latchCountsFiltered m37 : 16|16@1+ (0.00152590218931,0) [0|99.9999999764] "%" Vector__XXX
 SG_ CP_a037_latchState m37 : 32|2@1+ (1,0) [1|3] "" Vector__XXX
 SG_ CP_a037_CHG_InsertEnable m37 : 34|1@1+ (1,0) [0|1] "" Vector__XXX
 SG_ CP_a037_CP_latchEnableCmd m37 : 35|1@1+ (1,0) [0|1] "" Vector__XXX
 SG_ CP_a037_CP_apsVoltage m37 : 36|12@1+ (0.0170940179378,0) [0|70.0000034553] "V" Vector__XXX
 SG_ CP_a037_inletID m37 : 48|3@1+ (1,0) [0|7] "" Vector__XXX
 SG_ CP_a037_latchSwitchState m37 : 51|1@1+ (1,0) [0|1] "" Vector__XXX
 SG_ CP_a038_latchCountsFiltered m38 : 16|16@1+ (0.00152590218931,0) [0|99.9999999764] "%" Vector__XXX
 SG_ CP_a038_latchState m38 : 32|2@1+ (1,0) [1|3] "" Vector__XXX
 SG_ CP_a038_CHG_InsertEnable m38 : 34|1@1+ (1,0) [0|1] "" Vector__XXX
 SG_ CP_a038_CP_latchEnableCmd m38 : 35|1@1+ (1,0) [0|1] "" Vector__XXX
 SG_ CP_a038_CP_apsVoltage m38 : 40|8@1+ (0.07156863,0) [0|18.25000065] "V" Vector__XXX
 SG_ CP_a038_inletID m38 : 48|3@1+ (1,0) [0|7] "" Vector__XXX
 SG_ CP_a041_doorCounts m41 : 16|16@1+ (0.002,0) [0|131.07] "%" Vector__XXX
 SG_ CP_a041_inductiveSensorFiltered m41 : 32|18@1+ (82.77924,0) [0|21699998.3113] "Hz" Vector__XXX
 SG_ CP_a041_hallSensorFiltered m41 : 50|10@1+ (0.00488748773932,0) [0|4.99989995732] "V" Vector__XXX
 SG_ CP_a042_doorCounts m42 : 16|16@1+ (0.002,0) [0|131.07] "%" Vector__XXX
 SG_ CP_a042_inductiveSensorFiltered m42 : 32|18@1+ (82.77924,0) [0|21699998.3113] "Hz" Vector__XXX
 SG_ CP_a042_hallSensorFiltered m42 : 50|10@1+ (0.00488748773932,0) [0|4.99989995732] "V" Vector__XXX
 SG_ CP_a043_driftFlag m43 : 16|1@1+ (1,0) [0|1] "" Vector__XXX
 SG_ CP_a043_wrongDirectionFlag m43 : 17|1@1+ (1,0) [0|1] "" Vector__XXX
 SG_ CP_a043_outOfRangeFlag m43 : 18|1@1+ (1,0) [0|1] "" Vector__XXX
 SG_ CP_a043_doorPotFiltered m43 : 19|12@1+ (0.025,0) [0|102.375] "%" Vector__XXX
 SG_ CP_a043_doorVelocity m43 : 32|12@1- (0.5,0) [-1024|1023.5] "%/s" Vector__XXX
 SG_ CP_a043_idleDoorPot m43 : 44|12@1+ (0.025,0) [0|102.375] "%" Vector__XXX
 SG_ CP_a044_HVP_cpControl_MIA m44 : 16|1@1+ (1,0) [0|1] "" Vector__XXX
 SG_ CP_a045_VCSEC_authentication_MIA m45 : 16|1@1+ (1,0) [0|1] "" Vector__XXX
 SG_ CP_a045_VCSEC_requests_MIA m45 : 17|1@1+ (1,0) [0|1] "" Vector__XXX
 SG_ CP_a046_FC_status_flag m46 : 16|1@1+ (1,0) [0|1] "" Vector__XXX
 SG_ CP_a046_FC_limits_flag m46 : 17|1@1+ (1,0) [0|1] "" Vector__XXX
 SG_ CP_a046_FC_maxLimits_flag m46 : 18|1@1+ (1,0) [0|1] "" Vector__XXX
 SG_ CP_a046_FC_statusHighPower_flag m46 : 19|1@1+ (1,0) [0|1] "" Vector__XXX
 SG_ CP_a046_FC_limitsHighPower_flag m46 : 20|1@1+ (1,0) [0|1] "" Vector__XXX
 SG_ CP_a046_FC_maxLimitsHighPower m46 : 21|1@1+ (1,0) [0|1] "" Vector__XXX
 SG_ CP_a046_CC_chgStatus_flag m46 : 22|1@1+ (1,0) [0|1] "" Vector__XXX
 SG_ CP_a047_okToUseHighPower_MIA m47 : 16|1@1+ (1,0) [0|1] "" Vector__XXX
 SG_ CP_a047_LVPowerState_MIA m47 : 17|1@1+ (1,0) [0|1] "" Vector__XXX
 SG_ CP_a047_sensors_MIA m47 : 18|1@1+ (1,0) [0|1] "" Vector__XXX
 SG_ CP_a047_vehNm_MIA m47 : 19|1@1+ (1,0) [0|1] "" Vector__XXX
 SG_ CP_a049_proximity m49 : 16|2@1+ (1,0) [1|3] "" Vector__XXX
 SG_ CP_a050_latch1NotConnected m50 : 16|1@1+ (1,0) [0|1] "" Vector__XXX
 SG_ CP_a050_latch2NotConnected m50 : 17|1@1+ (1,0) [0|1] "" Vector__XXX
 SG_ CP_a050_maxLatchCurrentSeen m50 : 18|8@1+ (0.0007843137,0) [0|0.1999999935] "A" Vector__XXX
 SG_ CP_a050_minLatchCurrentBelowThre m50 : 26|6@1+ (0.0007936508,0) [0|0.0500000004] "A" Vector__XXX
 SG_ CP_a050_binaryCurrentProfile m50 : 32|30@1+ (1,0) [0|1073741823] "" Vector__XXX
 SG_ CP_a050_consecutiveAlertCount m50 : 62|2@1+ (1,0) [0|3] "" Vector__XXX
 SG_ CP_a051_doorCountsFiltered m51 : 16|12@1+ (0.025,0) [0|102.375] "%" Vector__XXX
 SG_ CP_a054_latchCountsFiltered m54 : 16|16@1+ (0.00152590218931,0) [0|99.9999999764] "%" Vector__XXX
 SG_ CP_a054_latchState m54 : 32|2@1+ (1,0) [1|3] "" Vector__XXX
 SG_ CP_a054_CHG_InsertEnable m54 : 34|1@1+ (1,0) [0|1] "" Vector__XXX
 SG_ CP_a054_CP_latchEnableCmd m54 : 35|1@1+ (1,0) [0|1] "" Vector__XXX
 SG_ CP_a054_CP_apsVoltage m54 : 36|12@1+ (0.0170940179378,0) [0|70.0000034553] "V" Vector__XXX
 SG_ CP_a054_CP_proximity m54 : 48|2@1+ (1,0) [1|3] "" Vector__XXX
 SG_ CP_a054_inletID m54 : 50|3@1+ (1,0) [0|7] "" Vector__XXX
 SG_ CP_a056_latchState m56 : 16|2@1+ (1,0) [1|3] "" Vector__XXX
 SG_ CP_a056_CHG_InsertEnable m56 : 18|1@1+ (1,0) [0|1] "" Vector__XXX
 SG_ CP_a056_CP_latchEnableCmd m56 : 19|1@1+ (1,0) [0|1] "" Vector__XXX
 SG_ CP_a056_CP_proximity m56 : 20|2@1+ (1,0) [1|3] "" Vector__XXX
 SG_ CP_a056_packCurrent m56 : 24|16@1- (0.1,0) [-3276.8|3276.7] "A" Vector__XXX
 SG_ CP_a058_CP_pilot m58 : 16|3@1+ (1,0) [0|6] "" Vector__XXX
 SG_ CP_a058_CC_pilot m58 : 19|2@1+ (1,0) [0|2] "" Vector__XXX
 SG_ CP_a058_FC_status m58 : 24|4@1+ (1,0) [1|15] "" Vector__XXX
 SG_ CP_a058_latchState m58 : 28|2@1+ (1,0) [1|3] "" Vector__XXX
 SG_ CP_a058_CP_proximity m58 : 30|2@1+ (1,0) [1|3] "" Vector__XXX
 SG_ CP_a058_acNumRetries m58 : 32|1@1+ (1,0) [0|1] "" Vector__XXX
 SG_ CP_a058_acRetryTimeoutS m58 : 33|15@1+ (1,0) [0|32767] "" Vector__XXX
 SG_ CP_a060_PCS_chgStatus_MIA m60 : 16|1@1+ (1,0) [0|1] "" Vector__XXX
 SG_ CP_a060_PCS_chgLineStatus_MIA m60 : 17|1@1+ (1,0) [0|1] "" Vector__XXX
 SG_ CP_a060_PCS2_v2xInfo_MIA m60 : 18|1@1+ (1,0) [0|1] "" Vector__XXX
 SG_ CP_a060_PCS2_v2xInfo2_MIA m60 : 19|1@1+ (1,0) [0|1] "" Vector__XXX
 SG_ CP_a061_controlState m61 : 16|4@1+ (1,0) [0|15] "" Vector__XXX
 SG_ CP_a061_lastControlState m61 : 20|4@1+ (1,0) [0|15] "" Vector__XXX
 SG_ CP_a061_chipState m61 : 24|3@1+ (1,0) [0|7] "" Vector__XXX
 SG_ CP_a061_timeMsInControlState m61 : 32|16@1+ (1,0) [0|65535] "" Vector__XXX
 SG_ CP_a062_FC_status m62 : 16|4@1+ (1,0) [1|15] "" Vector__XXX
 SG_ CP_a062_FC_type m62 : 20|3@1+ (1,0) [0|6] "" Vector__XXX
 SG_ CP_a063_FC_status m63 : 16|4@1+ (1,0) [1|15] "" Vector__XXX
 SG_ CP_a063_FC_type m63 : 20|3@1+ (1,0) [0|6] "" Vector__XXX
 SG_ CP_a066_pilotHigh m66 : 16|12@1- (0.008,0) [-16.384|16.376] "V" Vector__XXX
 SG_ CP_a066_pilotLow m66 : 28|12@1- (0.008,0) [-16.384|16.376] "V" Vector__XXX
 SG_ CP_a066_proximity m66 : 40|2@1+ (1,0) [1|3] "" Vector__XXX
 SG_ CP_a067_cc1Voltage m67 : 16|14@1+ (0.001,0) [0|16.383] "V" Vector__XXX
 SG_ CP_a067_cc2Voltage m67 : 32|14@1+ (0.001,0) [0|16.383] "V" Vector__XXX
 SG_ CP_a068_doorCountsFiltered m68 : 16|12@1+ (0.025,0) [0|102.375] "%" Vector__XXX
 SG_ CP_a068_doorClosed m68 : 28|1@1+ (1,0) [0|1] "" Vector__XXX
 SG_ CP_a068_inductiveSensorFiltered m68 : 29|18@1+ (82.77924,0) [0|21699998.3113] "Hz" Vector__XXX
 SG_ CP_a068_hallSensorFiltered m68 : 48|10@1+ (0.00488748773932,0) [0|4.99989995732] "V" Vector__XXX
 SG_ CP_a068_doorPresent m68 : 58|1@1+ (1,0) [0|1] "" Vector__XXX
 SG_ CP_a069_inductiveSensor_raw m69 : 16|28@1+ (1,0) [0|268435455] "" Vector__XXX
 SG_ CP_a069_inductiveErrorAmplitude m69 : 44|1@1+ (1,0) [0|1] "" Vector__XXX
 SG_ CP_a069_inductiveErrorWatchdog m69 : 45|1@1+ (1,0) [0|1] "" Vector__XXX
 SG_ CP_a069_inductiveErrorOverRange m69 : 46|1@1+ (1,0) [0|1] "" Vector__XXX
 SG_ CP_a069_inductiveErrorUnderRange m69 : 47|1@1+ (1,0) [0|1] "" Vector__XXX
 SG_ CP_a071_expectedMessage m71 : 16|5@1+ (1,0) [0|31] "" Vector__XXX
 SG_ CP_a072_currentMessage m72 : 16|5@1+ (1,0) [0|31] "" Vector__XXX
 SG_ CP_a072_readyToChargeExpired m72 : 21|1@1+ (1,0) [0|1] "" Vector__XXX
 SG_ CP_a072_commsSetupExpired m72 : 22|1@1+ (1,0) [0|1] "" Vector__XXX
 SG_ CP_a072_cableCheckExpired m72 : 23|1@1+ (1,0) [0|1] "" Vector__XXX
 SG_ CP_a072_preChargeExpired m72 : 24|1@1+ (1,0) [0|1] "" Vector__XXX
 SG_ CP_a074_slacState m74 : 16|4@1+ (1,0) [0|15] "" Vector__XXX
 SG_ CP_a074_slacErrorCode m74 : 20|4@1+ (1,0) [0|15] "" Vector__XXX
 SG_ CP_a074_sdpNoDiscoveryResponse m74 : 24|1@1+ (1,0) [0|1] "" Vector__XXX
 SG_ CP_a074_evseMeasuredAtten m74 : 32|8@1+ (1,0) [0|255] "" Vector__XXX
 SG_ CP_a075_evccState m75 : 16|3@1+ (1,0) [0|7] "" Vector__XXX
 SG_ CP_a075_currentMessage m75 : 19|5@1+ (1,0) [0|31] "" Vector__XXX
 SG_ CP_a075_exiUnpackFailed m75 : 24|1@1+ (1,0) [0|1] "" Vector__XXX
 SG_ CP_a075_failedResponseCode m75 : 25|1@1+ (1,0) [0|1] "" Vector__XXX
 SG_ CP_a075_evseMeasuredAtten m75 : 32|8@1+ (1,0) [0|255] "" Vector__XXX
 SG_ CP_a075_evseEmergencyChgEnd m75 : 40|1@1+ (1,0) [0|1] "" Vector__XXX
 SG_ CP_a075_initFailureType m75 : 41|2@1+ (1,0) [0|3] "" Vector__XXX
 SG_ CP_a075_evccSocketErrTx m75 : 43|5@1+ (1,0) [0|31] "" Vector__XXX
 SG_ CP_a075_evccSocketErrRx m75 : 48|5@1+ (1,0) [0|31] "" Vector__XXX
 SG_ CP_a075_commsFailReason m75 : 56|4@1+ (1,0) [0|15] "" Vector__XXX
 SG_ CP_a077_mac1Invalid m77 : 16|1@1+ (1,0) [0|1] "" Vector__XXX
 SG_ CP_a077_mac2Invalid m77 : 17|1@1+ (1,0) [0|1] "" Vector__XXX
 SG_ CP_a077_macsMatching m77 : 18|1@1+ (1,0) [0|1] "" Vector__XXX
 SG_ CP_a078_VC_tempAmbientFiltered m78 : 16|8@1+ (0.5,-40) [-39.5|87.5] "degC" Vector__XXX
 SG_ CP_a078_pinTemperature1 m78 : 24|8@1+ (0.8039216,-55) [-55|149.1960864] "C" Vector__XXX
 SG_ CP_a078_pinTemperature2 m78 : 32|8@1+ (0.8039216,-55) [-55|149.1960864] "C" Vector__XXX
 SG_ CP_a078_pinTemperature3 m78 : 40|8@1+ (0.8039216,-55) [-55|149.1960864] "C" Vector__XXX
 SG_ CP_a079_VC_tempAmbientFiltered m79 : 16|8@1+ (0.5,-40) [-39.5|87.5] "degC" Vector__XXX
 SG_ CP_a079_pinTemperature1 m79 : 24|8@1+ (0.8039216,-55) [-55|149.1960864] "C" Vector__XXX
 SG_ CP_a079_pinTemperature2 m79 : 32|8@1+ (0.8039216,-55) [-55|149.1960864] "C" Vector__XXX
 SG_ CP_a079_pinTemperature3 m79 : 40|8@1+ (0.8039216,-55) [-55|149.1960864] "C" Vector__XXX
 SG_ CP_a084_proximityV m84 : 16|16@1+ (0.0001,0) [0|6.5535] "V" Vector__XXX
 SG_ CP_a084_cc1Voltage m84 : 32|14@1+ (0.001,0) [0|16.383] "V" Vector__XXX
 SG_ CP_a084_cc2Voltage m84 : 48|14@1+ (0.001,0) [0|16.383] "V" Vector__XXX
 SG_ CP_a085_absoluteTempFault m85 : 16|1@1+ (1,0) [0|1] "" Vector__XXX
 SG_ CP_a085_dcPinTemp m85 : 24|8@1+ (0.8039216,-55) [-55|150.000008] "C" Vector__XXX
 SG_ CP_a086_dcPinTemp m86 : 16|8@1+ (0.8039216,-55) [-55|150.000008] "C" Vector__XXX
 SG_ CP_a089_gtwPlcSupportType m89 : 16|2@1+ (1,0) [0|3] "" Vector__XXX
 SG_ CP_a089_plcModemPopulated m89 : 18|1@1+ (1,0) [0|1] "" Vector__XXX
 SG_ CP_a090_evseIsoStatus m90 : 16|3@1+ (1,0) [0|7] "" Vector__XXX
 SG_ CP_a090_ccsDcState m90 : 19|4@1+ (1,0) [0|15] "" Vector__XXX
 SG_ CP_a091_fcType m91 : 16|3@1+ (1,0) [0|6] "" Vector__XXX
 SG_ CP_a093_appLoadingNumRetries m93 : 16|3@1+ (1,0) [0|7] "" Vector__XXX
 SG_ CP_a093_interruptCauseRegError m93 : 19|1@1+ (1,0) [0|1] "" Vector__XXX
 SG_ CP_a095_packCurrent m95 : 16|13@1- (1,0) [-4096|4095] "A" Vector__XXX
 SG_ CP_a095_dcOutputCurrent m95 : 32|13@1- (1,0) [-4096|4095] "A" Vector__XXX
 SG_ CP_a095_ambientTemp m95 : 48|8@1+ (0.8039216,-55) [-55|150.000008] "C" Vector__XXX
 SG_ CP_a095_fcType m95 : 56|3@1+ (1,0) [0|6] "" Vector__XXX
 SG_ CP_a095_fcBrand m95 : 59|1@1+ (1,0) [0|1] "" Vector__XXX
 SG_ CP_a099_proximity m99 : 16|2@1+ (1,0) [1|3] "" Vector__XXX
 SG_ CP_a099_pilot m99 : 18|3@1+ (1,0) [0|6] "" Vector__XXX
 SG_ CP_a103_proximityV m103 : 16|16@1+ (0.0001,0) [0|6.5535] "V" Vector__XXX
 SG_ CP_a109_thermistorId m109 : 16|3@1+ (1,0) [0|7] "" Vector__XXX
 SG_ CP_a109_thermistorTemp m109 : 24|8@1+ (0.8039216,-55) [-55|150.000008] "C" Vector__XXX
 SG_ CP_a110_thermistorId m110 : 16|3@1+ (1,0) [0|7] "" Vector__XXX
 SG_ CP_a110_thermistorTemp m110 : 24|8@1+ (0.8039216,-55) [-55|150.000008] "C" Vector__XXX
 SG_ CP_a110_thermalVelocity m110 : 32|10@1- (0.15748,0) [-80.62976|80.3148] "C/min" Vector__XXX
 SG_ CP_a111_heaterTemperature m111 : 16|8@1+ (0.8039216,-55) [-55|149.1960864] "C" Vector__XXX
 SG_ CP_a111_VC_tempAmbientFiltered m111 : 24|8@1+ (0.5,-40) [-39.5|87.5] "degC" Vector__XXX
 SG_ CP_a112_heaterTemperature m112 : 16|8@1+ (0.8039216,-55) [-55|149.1960864] "C" Vector__XXX
 SG_ CP_a113_heaterTemperature m113 : 16|8@1+ (0.8039216,-55) [-55|149.1960864] "C" Vector__XXX
 SG_ CP_a113_heaterCurrent m113 : 24|12@1+ (0.0025,0) [0|10.2375] "A" Vector__XXX
 SG_ CP_a116_hvCoverDetected m116 : 16|1@1+ (1,0) [0|1] "" Vector__XXX
 SG_ CP_a116_heaterDetected m116 : 17|1@1+ (1,0) [0|1] "" Vector__XXX
 SG_ CP_a116_temperatureSensorMismatc m116 : 18|1@1+ (1,0) [0|1] "" Vector__XXX
 SG_ CP_a116_thermistorsOpenCircuit m116 : 19|1@1+ (1,0) [0|1] "" Vector__XXX
 SG_ CP_a117_heaterTemperature m117 : 16|8@1+ (0.8039216,-55) [-55|149.1960864] "C" Vector__XXX
 SG_ CP_a117_averageError m117 : 24|8@1+ (0.8039216,-55) [-55|149.1960864] "C" Vector__XXX
 SG_ CP_a120_oldProximtyV m120 : 16|10@1+ (0.00488758552819,0) [0|4.99999999534] "V" Vector__XXX
 SG_ CP_a120_newProximtyV m120 : 26|10@1+ (0.00488758552819,0) [0|4.99999999534] "V" Vector__XXX
 SG_ CP_a120_chargeVoltage m120 : 36|8@1+ (5,0) [0|1275] "V" Vector__XXX
 SG_ CP_a120_chargeCurrent m120 : 44|8@1+ (5,0) [0|1275] "A" Vector__XXX
 SG_ CP_a120_dcPinTemp m120 : 52|8@1+ (0.8039216,-55) [-55|149.1960864] "C" Vector__XXX
 SG_ CP_a120_cableType m120 : 60|3@1+ (1,0) [0|7] "" Vector__XXX
 SG_ CP_a121_CP_status_MIA m121 : 16|1@1+ (1,0) [0|1] "" Vector__XXX
 SG_ CP_a124_ivledState m124 : 16|2@1+ (1,0) [0|3] "" Vector__XXX
 SG_ CP_a124_ivledVoltage m124 : 24|8@1+ (0.01968504,0) [0|5.0196852] "V" Vector__XXX
 SG_ CP_a125_okToUseHighPower m125 : 16|1@1+ (1,0) [0|1] "" Vector__XXX
 SG_ CP_a127_HVLINK_cpControl_MIA m127 : 16|1@1+ (1,0) [0|1] "" Vector__XXX
 SG_ CP_a129_bldcDriverState m129 : 16|2@1+ (1,0) [0|3] "" Vector__XXX
 SG_ CP_a130_retryCount m130 : 16|8@1+ (1,0) [0|255] "" Vector__XXX
 SG_ CP_a131_powerTransferProtocol m131 : 16|3@1+ (1,0) [0|7] "" Vector__XXX
 SG_ CP_a135_sdpErr m135 : 16|3@1+ (1,0) [0|7] "" Vector__XXX
 SG_ CP_a135_pilotState m135 : 19|3@1+ (1,0) [0|6] "" Vector__XXX
 SG_ CP_a135_evseMeasuredAtten m135 : 24|8@1+ (1,0) [0|255] "" Vector__XXX
 SG_ CP_a138_FC_type m138 : 16|3@1+ (1,0) [0|6] "" Vector__XXX
 SG_ CP_a138_latchState m138 : 19|2@1+ (1,0) [1|3] "" Vector__XXX
 SG_ CP_a138_CP_proximity m138 : 21|2@1+ (1,0) [1|3] "" Vector__XXX
 SG_ CP_a139_latchState m139 : 16|2@1+ (1,0) [1|3] "" Vector__XXX
 SG_ CP_a139_CP_proximity m139 : 18|2@1+ (1,0) [1|3] "" Vector__XXX
 SG_ CP_a140_latchState m140 : 16|2@1+ (1,0) [1|3] "" Vector__XXX
 SG_ CP_a140_CP_proximity m140 : 18|2@1+ (1,0) [1|3] "" Vector__XXX
 SG_ CP_a141_latchState m141 : 16|2@1+ (1,0) [1|3] "" Vector__XXX
 SG_ CP_a141_CP_proximity m141 : 18|2@1+ (1,0) [1|3] "" Vector__XXX
 SG_ CP_a142_cc1Voltage m142 : 16|14@1+ (0.001,0) [0|16.383] "V" Vector__XXX
 SG_ CP_a142_cc2Voltage m142 : 32|14@1+ (0.001,0) [0|16.383] "V" Vector__XXX
 SG_ CP_a143_versionDetected m143 : 16|3@1+ (1,0) [0|7] "" Vector__XXX
 SG_ CP_a146_v2gMessage m146 : 16|5@1+ (1,0) [0|31] "" Vector__XXX
 SG_ CP_a151_pilotHighMin m151 : 16|12@1+ (0.00354090356268,0) [0|14.5000000892] "V" Vector__XXX
 SG_ CP_a151_pilotHighMax m151 : 28|12@1+ (0.00354090356268,0) [0|14.5000000892] "V" Vector__XXX
 SG_ CP_a151_pilotLowMin m151 : 40|12@1- (0.0105031756684,-5.745237) [-27.2557407689|15.7547635932] "V" Vector__XXX
 SG_ CP_a151_pilotLowMax m151 : 52|12@1- (0.0105031756684,-5.745237) [-27.2557407689|15.7547635932] "V" Vector__XXX
 SG_ CP_a152_swcanHighMismatchCount m152 : 16|5@1+ (1,0) [0|31] "" Vector__XXX
 SG_ CP_a152_swcanLowMismatchCount m152 : 21|5@1+ (1,0) [0|31] "" Vector__XXX
 SG_ CP_a152_maxPilotSwcanHigh m152 : 26|9@1+ (0.0283757336438,0) [0|14.499999892] "V" Vector__XXX
 SG_ CP_a152_minPilotSwcanHigh m152 : 35|9@1+ (0.0283757336438,0) [0|14.499999892] "V" Vector__XXX
 SG_ CP_a152_maxPilotSwcanLow m152 : 44|9@1+ (0.0283757336438,0) [0|14.499999892] "V" Vector__XXX
 SG_ CP_a152_minPilotSwcanLow m152 : 53|9@1+ (0.0283757336438,0) [0|14.499999892] "V" Vector__XXX
 SG_ CP_a153_acPinTempVelocity m153 : 16|10@1- (0.15748,0) [-80.62976|80.3148] "C/min" Vector__XXX
 SG_ CP_a153_acPinTemp1 m153 : 26|8@1+ (0.8039216,-55) [-55|149.1960864] "C" Vector__XXX
 SG_ CP_a153_acPinTemp2 m153 : 34|8@1+ (0.8039216,-55) [-55|149.1960864] "C" Vector__XXX
 SG_ CP_a153_ambientTemp m153 : 42|8@1+ (0.8039216,-55) [-55|150.000008] "C" Vector__XXX
 SG_ CP_a153_pcsLineChargeCurrent m153 : 50|9@1+ (0.1,0) [0|51.1] "A" Vector__XXX
 SG_ CP_a154_acPinTempVelocity m154 : 16|10@1- (0.15748,0) [-80.62976|80.3148] "C/min" Vector__XXX
 SG_ CP_a154_acPinTemp1 m154 : 26|8@1+ (0.8039216,-55) [-55|149.1960864] "C" Vector__XXX
 SG_ CP_a154_acPinTemp2 m154 : 34|8@1+ (0.8039216,-55) [-55|149.1960864] "C" Vector__XXX
 SG_ CP_a154_ambientTemp m154 : 42|8@1+ (0.8039216,-55) [-55|150.000008] "C" Vector__XXX
 SG_ CP_a154_pcsLineChargeCurrent m154 : 50|9@1+ (0.1,0) [0|51.1] "A" Vector__XXX
 SG_ CP_a155_hallSensorVoltage m155 : 16|10@1+ (0.00488758552819,0) [0|4.99999999534] "V" Vector__XXX
 SG_ CP_a161_pilotHighMin m161 : 16|12@1+ (0.00354090356268,0) [0|14.5000000892] "V" Vector__XXX
 SG_ CP_a161_pilotHighMax m161 : 28|12@1+ (0.00354090356268,0) [0|14.5000000892] "V" Vector__XXX
 SG_ CP_a161_pilotLowMin m161 : 40|12@1- (0.0105031756684,-5.745237) [-27.2557407689|15.7547635932] "V" Vector__XXX
 SG_ CP_a161_pilotLowMax m161 : 52|12@1- (0.0105031756684,-5.745237) [-27.2557407689|15.7547635932] "V" Vector__XXX
 SG_ CP_a162_swcanHighMismatchCount m162 : 16|5@1+ (1,0) [0|31] "" Vector__XXX
 SG_ CP_a162_swcanLowMismatchCount m162 : 21|5@1+ (1,0) [0|31] "" Vector__XXX
 SG_ CP_a162_maxPilotSwcanHigh m162 : 26|9@1+ (0.0283757336438,0) [0|14.499999892] "V" Vector__XXX
 SG_ CP_a162_minPilotSwcanHigh m162 : 35|9@1+ (0.0283757336438,0) [0|14.499999892] "V" Vector__XXX
 SG_ CP_a162_maxPilotSwcanLow m162 : 44|9@1+ (0.0283757336438,0) [0|14.499999892] "V" Vector__XXX
 SG_ CP_a162_minPilotSwcanLow m162 : 53|9@1+ (0.0283757336438,0) [0|14.499999892] "V" Vector__XXX
 SG_ CP_a163_cover1OpenCounts m163 : 16|12@1+ (0.025,0) [0|102.375] "%" Vector__XXX
 SG_ CP_a163_cover2OpenCounts m163 : 28|12@1+ (0.025,0) [0|102.375] "%" Vector__XXX
 SG_ CP_a163_cover1State m163 : 40|3@1+ (1,0) [0|7] "" Vector__XXX
 SG_ CP_a163_cover2State m163 : 43|3@1+ (1,0) [0|7] "" Vector__XXX
 SG_ CP_a164_VC_tempAmbientFiltered m164 : 16|8@1+ (0.5,-40) [-39.5|87.5] "degC" Vector__XXX
 SG_ CP_a164_minInternalPinTemp m164 : 24|8@1+ (0.8039216,-55) [-55|149.1960864] "C" Vector__XXX
 SG_ CP_a173_cover1OpenCounts m173 : 16|12@1+ (0.025,0) [0|102.375] "%" Vector__XXX
 SG_ CP_a173_cover2OpenCounts m173 : 28|12@1+ (0.025,0) [0|102.375] "%" Vector__XXX
 SG_ CP_a173_cover1State m173 : 40|3@1+ (1,0) [0|7] "" Vector__XXX
 SG_ CP_a173_cover2State m173 : 43|3@1+ (1,0) [0|7] "" Vector__XXX
 SG_ CP_a189_resistiveDividerVoltage m189 : 16|10@1+ (0.00488758552819,0) [0|4.99999999534] "V" Vector__XXX
 SG_ CP_a201_uhfDoorRequestCounts m201 : 16|5@1+ (1,0) [0|31] "" Vector__XXX
 SG_ CP_a205_doorPotFiltered m205 : 16|12@1+ (0.025,0) [0|102.375] "%" Vector__XXX
 SG_ CP_a205_doorPositionEstimationSu m205 : 28|1@1+ (1,0) [0|1] "" Vector__XXX
 SG_ CP_a205_bldcMotorState m205 : 29|2@1+ (1,0) [0|3] "" Vector__XXX
 SG_ CP_a205_bldcTachIsInvalid m205 : 31|1@1+ (1,0) [0|1] "" Vector__XXX
 SG_ CP_a205_presenceVoltage m205 : 32|10@1+ (0.00488758552819,0) [0|4.99999999534] "V" Vector__XXX
 SG_ CP_a206_peToChassisVoltage m206 : 16|12@1- (0.00322423060425,0) [-6.6032242775|6.6000000469] "V" Vector__XXX
 SG_ CP_a210_PCSR_chgStatus_MIA m210 : 16|1@1+ (1,0) [0|1] "" Vector__XXX
 SG_ CP_a210_PCS2R_v2xInfo_MIA m210 : 17|1@1+ (1,0) [0|1] "" Vector__XXX
 SG_ CP_a210_PCS2R_v2xInfo2_MIA m210 : 18|1@1+ (1,0) [0|1] "" Vector__XXX
 SG_ CP_a211_PCSL_chgStatus_MIA m211 : 16|1@1+ (1,0) [0|1] "" Vector__XXX
 SG_ CP_a211_PCS2L_v2xInfo_MIA m211 : 17|1@1+ (1,0) [0|1] "" Vector__XXX
 SG_ CP_a211_PCS2L_v2xInfo2_MIA m211 : 18|1@1+ (1,0) [0|1] "" Vector__XXX
 SG_ CP_a220_ethPhyDriverFailure m220 : 16|1@1+ (1,0) [0|1] "" Vector__XXX
 SG_ CP_a220_sdpFailure m220 : 17|1@1+ (1,0) [0|1] "" Vector__XXX
 SG_ CP_a220_evccServiceFailure m220 : 18|1@1+ (1,0) [0|1] "" Vector__XXX
 SG_ CP_a220_teslaV2gServiceFailure m220 : 19|1@1+ (1,0) [0|1] "" Vector__XXX

BO_TX_BU_ 914 : BMS;
BO_TX_BU_ 1810 : BMS;
BO_TX_BU_ 594 : BMS;
BO_TX_BU_ 674 : BMS;
BO_TX_BU_ 1834 : BMS;
BO_TX_BU_ 658 : BMS;
BO_TX_BU_ 1170 : BMS;
BO_TX_BU_ 530 : BMS;
BO_TX_BU_ 786 : BMS;
BO_TX_BU_ 1554 : BMS;
BO_TX_BU_ 1071 : BMS;
BO_TX_BU_ 754 : BMS;
BO_TX_BU_ 810 : BMS;
BO_TX_BU_ 1116 : CC;
BO_TX_BU_ 1132 : CC;
BO_TX_BU_ 796 : CC;
BO_TX_BU_ 797 : CC;
BO_TX_BU_ 812 : CC;
BO_TX_BU_ 870 : CMPD;
BO_TX_BU_ 679 : CMPD;
BO_TX_BU_ 1559 : CMPD;
BO_TX_BU_ 867 : CMP;
BO_TX_BU_ 1555 : CMP;
BO_TX_BU_ 1767 : CP;
BO_TX_BU_ 1294 : CP;
CM_ BO_ 914 "High-voltage battery management system message: pack config; frame length from the layout, not yet observed on a vehicle bus";
CM_ SG_ 914 BMS_packConfigMultiplexer "High-voltage battery management system: pack config multiplexer";
CM_ SG_ 914 BMS_reservedConfig_0 "High-voltage battery management system: reserved config 0";
CM_ SG_ 914 BMS_moduleType "High-voltage battery management system: module type";
CM_ SG_ 914 BMS_thermalPackType "High-voltage battery management system: thermal pack type";
CM_ SG_ 914 BMS_packMass "High-voltage battery management system: pack mass";
CM_ SG_ 914 BMS_platformMaxBusVoltage "High-voltage battery management system: platform max bus voltage";
CM_ SG_ 914 BMS_standbySupplyContinuousPower "High-voltage battery management system: standby supply continuous power limit";
CM_ SG_ 914 BMS_beginningOfLifePackEnergy "High-voltage battery management system: beginning of life pack energy; raw 1023 = signal not available (SNA)";
CM_ BO_ 1810 "High-voltage battery management system message: pack temperature measurements; frame length from the layout, not yet observed on a vehicle bus";
CM_ SG_ 1810 BMS_packTemperatureMultiplexer "High-voltage battery management system: pack temperature multiplexer";
CM_ SG_ 1810 BMS_packTemperatureCounter "High-voltage battery management system: pack temperature counter";
CM_ SG_ 1810 BMS_packTemperatureStatus1 "High-voltage battery management system: pack temperature status1";
CM_ SG_ 1810 BMS_packTemperatureStatus2 "High-voltage battery management system: pack temperature status2";
CM_ SG_ 1810 BMS_packTemperatureStatus3 "High-voltage battery management system: pack temperature status3";
CM_ SG_ 1810 BMS_packTemperature1 "Measured temperature of location within the pack";
CM_ SG_ 1810 BMS_packTemperature2 "Measured temperature of location within the pack";
CM_ SG_ 1810 BMS_packTemperature3 "Measured temperature of location within the pack";
CM_ SG_ 1810 BMS_packTemperatureStatus4 "High-voltage battery management system: pack temperature status4";
CM_ SG_ 1810 BMS_packTemperatureStatus5 "High-voltage battery management system: pack temperature status5";
CM_ SG_ 1810 BMS_packTemperatureStatus6 "High-voltage battery management system: pack temperature status6";
CM_ SG_ 1810 BMS_packTemperature4 "Measured temperature of location within the pack";
CM_ SG_ 1810 BMS_packTemperature5 "Measured temperature of location within the pack";
CM_ SG_ 1810 BMS_packTemperature6 "Measured temperature of location within the pack";
CM_ SG_ 1810 BMS_packTemperatureStatus7 "High-voltage battery management system: pack temperature status7";
CM_ SG_ 1810 BMS_packTemperatureStatus8 "High-voltage battery management system: pack temperature status8";
CM_ SG_ 1810 BMS_packTemperatureStatus9 "High-voltage battery management system: pack temperature status9";
CM_ SG_ 1810 BMS_packTemperature7 "Measured temperature of location within the pack";
CM_ SG_ 1810 BMS_packTemperature8 "Measured temperature of location within the pack";
CM_ SG_ 1810 BMS_packTemperature9 "Measured temperature of location within the pack";
CM_ SG_ 1810 BMS_packTemperatureStatus10 "High-voltage battery management system: pack temperature status10";
CM_ SG_ 1810 BMS_packTemperatureStatus11 "High-voltage battery management system: pack temperature status11";
CM_ SG_ 1810 BMS_packTemperatureStatus12 "High-voltage battery management system: pack temperature status12";
CM_ SG_ 1810 BMS_packTemperature10 "Measured temperature of location within the pack";
CM_ SG_ 1810 BMS_packTemperature11 "Measured temperature of location within the pack";
CM_ SG_ 1810 BMS_packTemperature12 "Measured temperature of location within the pack";
CM_ SG_ 1810 BMS_packTemperatureStatus13 "High-voltage battery management system: pack temperature status13";
CM_ SG_ 1810 BMS_packTemperatureStatus14 "High-voltage battery management system: pack temperature status14";
CM_ SG_ 1810 BMS_packTemperatureStatus15 "High-voltage battery management system: pack temperature status15";
CM_ SG_ 1810 BMS_packTemperature13 "Measured temperature of location within the pack";
CM_ SG_ 1810 BMS_packTemperature14 "Measured temperature of location within the pack";
CM_ SG_ 1810 BMS_packTemperature15 "Measured temperature of location within the pack";
CM_ SG_ 1810 BMS_packTemperatureStatus16 "High-voltage battery management system: pack temperature status16";
CM_ SG_ 1810 BMS_packTemperatureStatus17 "High-voltage battery management system: pack temperature status17";
CM_ SG_ 1810 BMS_packTemperatureStatus18 "High-voltage battery management system: pack temperature status18";
CM_ SG_ 1810 BMS_packTemperature16 "Measured temperature of location within the pack";
CM_ SG_ 1810 BMS_packTemperature17 "Measured temperature of location within the pack";
CM_ SG_ 1810 BMS_packTemperature18 "Measured temperature of location within the pack";
CM_ BO_ 594 "High-voltage battery management system message: power available; frame length from the layout, not yet observed on a vehicle bus";
CM_ SG_ 594 BMS_maxRegenPower "Calculated max regen power";
CM_ SG_ 594 BMS_maxDischargePower "Calculated max discharge power possible based on max discharge current and sum of loaded voltages";
CM_ SG_ 594 BMS_maxStationaryHeatPower "Maximum heating power the DI can produce when in stationary heating mode";
CM_ SG_ 594 BMS_powerLimitsState "High-voltage battery management system: power limits state";
CM_ SG_ 594 BMS_totalHvPowerBudget "Maximum total power that the High Voltage (HV) battery and Electric Vehicle Supply Equipment (EVSE) (if present) can safely produce";
CM_ SG_ 594 BMS_notEnoughPowerForHeatPump "Flag indicating the min pack power is lower than specified threshold to support heating with the heat pump";
CM_ BO_ 674 "High-voltage battery management system message: ripple request; frame length from the layout, not yet observed on a vehicle bus";
CM_ SG_ 674 BMS_acRippleCurrentAmplitudeLimi "Transmits the Battery Management System (BMS) AC ripple current amplitude limit to the Electric Vehicle Supply Equipment (EVSE).";
CM_ SG_ 674 BMS_acRippleMaxVoltageLimit "Reports the maximum voltage limit when the Electric Vehicle Supply Equipment (EVSE) is performing the AC ripple.";
CM_ SG_ 674 BMS_acRippleMinVoltageLimit "Reports the minimum voltage limit when the Electric Vehicle Supply Equipment (EVSE) is performing the AC ripple.";
CM_ SG_ 674 BMS_acRippleFrequencyRequest "Transmits the Battery Management System (BMS) AC ripple frequency request to the Electric Vehicle Supply Equipment (EVSE); raw 1023 = signal not available (SNA)";
CM_ SG_ 674 BMS_acRippleCurrentAmplitudeRequ "Transmits the Battery Management System (BMS) AC ripple current amplitude request to the Electric Vehicle Supply Equipment (EVSE).";
CM_ SG_ 674 BMS_acRippleRequest "High-voltage battery management system: ac ripple request";
CM_ BO_ 1834 "High-voltage battery management system message: serial number; frame length from the layout, not yet observed on a vehicle bus";
CM_ SG_ 1834 BMS_serialNumberMultiplexer "High-voltage battery management system: serial number multiplexer";
CM_ SG_ 1834 BMS_packSerialNumberByte01 "Pack serial number, character 1 (ASCII)";
CM_ SG_ 1834 BMS_packSerialNumberByte02 "Pack serial number, character 2 (ASCII)";
CM_ SG_ 1834 BMS_packSerialNumberByte03 "Pack serial number, character 3 (ASCII)";
CM_ SG_ 1834 BMS_packSerialNumberByte04 "Pack serial number, character 4 (ASCII)";
CM_ SG_ 1834 BMS_packSerialNumberByte05 "Pack serial number, character 5 (ASCII)";
CM_ SG_ 1834 BMS_packSerialNumberByte06 "Pack serial number, character 6 (ASCII)";
CM_ SG_ 1834 BMS_packSerialNumberByte07 "Pack serial number, character 7 (ASCII)";
CM_ SG_ 1834 BMS_packSerialNumberByte08 "Pack serial number, character 8 (ASCII)";
CM_ SG_ 1834 BMS_packSerialNumberByte09 "Pack serial number, character 9 (ASCII)";
CM_ SG_ 1834 BMS_packSerialNumberByte10 "Pack serial number, character 10 (ASCII)";
CM_ SG_ 1834 BMS_packSerialNumberByte11 "Pack serial number, character 11 (ASCII)";
CM_ SG_ 1834 BMS_packSerialNumberByte12 "Pack serial number, character 12 (ASCII)";
CM_ SG_ 1834 BMS_packSerialNumberByte13 "Pack serial number, character 13 (ASCII)";
CM_ SG_ 1834 BMS_packSerialNumberByte14 "Pack serial number, character 14 (ASCII)";
CM_ SG_ 1834 BMS_packSerialBirthDateBinned "High-voltage battery management system: pack serial birth date binned";
CM_ BO_ 658 "High-voltage battery management system message: soc status; frame length from the layout, not yet observed on a vehicle bus";
CM_ SG_ 658 BMS_socMin "BMS State Of Charge (SOC). This is the minimum brick SOC.";
CM_ SG_ 658 BMS_socUI "BMS State Of Energy (SOE) for the UI. This is ideal discharge energy from present state / ideal discharge energy from full.";
CM_ SG_ 658 BMS_socMax "BMS State Of Charge (SOC). This is the maximum brick SOC.";
CM_ SG_ 658 BMS_socAvg "BMS State Of Charge (SOC). This is the average of all the brick SOCs";
CM_ SG_ 658 BMS_enoughEnergyForConvenienceFe "Flag to indicate if there is enough energy for user facing features that are function of the UI discharge limit";
CM_ SG_ 658 BMS_instantChargePowerCapability "Indicates the instantaneous charge power capability of the high voltage battery; raw 65535 = signal not available (SNA)";
CM_ BO_ 1170 "High-voltage battery management system message: state of health; frame length from the layout, not yet observed on a vehicle bus";
CM_ SG_ 1170 BMS_sohEnergyPercent "Estimate of battery SOH Energy % based on the most accurate capacity estimates the BMS has available; raw 1023 = signal not available (SNA)";
CM_ SG_ 1170 BMS_userFacingSohTestState "High-voltage battery management system: user facing soh test state";
CM_ SG_ 1170 BMS_userFacingSohTestEndMode "High-voltage battery management system: user facing soh test end mode";
CM_ SG_ 1170 BMS_timeSinceSohUpdate "Days since last successful SOH test; raw 4095 = signal not available (SNA)";
CM_ SG_ 1170 BMS_sohTestCycleFlag "Flag that is True from the start of an SOH test until it ends and all relevant signals have been logged";
CM_ SG_ 1170 BMS_sohTestIsBlocked "High-voltage battery management system: soh test is blocked";
CM_ SG_ 1170 BMS_calibratedSohAvailable "SOH Energy is based on valid results from the SOH capacity test";
CM_ SG_ 1170 BMS_requiredEvsePowerForSoh "High-voltage battery management system: required evse power for soh; raw 255 = signal not available (SNA)";
CM_ SG_ 1170 BMS_distanceSinceSohUpdate "Distance since the last State of Health update in km; raw 65535 = signal not available (SNA)";
CM_ BO_ 530 "High-voltage battery management system message: status; frame length from the layout, not yet observed on a vehicle bus";
CM_ SG_ 530 BMS_hvacPowerRequest "High-voltage battery management system: hvac power request";
CM_ SG_ 530 BMS_notEnoughPowerForDrive "Flag indicating the min pack power is lower than specified threshold to support drive";
CM_ SG_ 530 BMS_notEnoughPowerForSupport "Flag indicating if the system can support a new request for 12V battery support";
CM_ SG_ 530 BMS_preconditionAllowed "High-voltage battery management system: precondition allowed";
CM_ SG_ 530 BMS_updateAllowed "High-voltage battery management system: update allowed";
CM_ SG_ 530 BMS_cpMiaOnHvs "Flag indicating that BMS is no longer receiving comms from CP on HVS bus";
CM_ SG_ 530 BMS_pcsPwmEnabled "Reports the state of the PCS_PWM_ENABLE input on the HVBMS, which is derived from the P1-12-DCDC-ENABLE input, which comes from VCFRONT";
CM_ SG_ 530 BMS_contactorState "BMS Contactor Status; raw 0 = signal not available (SNA)";
CM_ SG_ 530 BMS_userChargeStatus "BMS charge status for UI display. Renamed from BMS_uiChargeStatus";
CM_ SG_ 530 BMS_batteryInputPower "High-voltage battery management system: battery input power; raw 65535 = signal not available (SNA)";
CM_ SG_ 530 BMS_chargeRequest "Indicates charge is available and charge is desired";
CM_ SG_ 530 BMS_state "BMS operating state; raw 9 = signal not available (SNA)";
CM_ SG_ 530 BMS_diLimpRequest "BMS request to DI to enter limp mode";
CM_ SG_ 530 BMS_okToShipByAir "High-voltage battery management system: ok to ship by air";
CM_ SG_ 530 BMS_okToShipByLand "High-voltage battery management system: ok to ship by land";
CM_ SG_ 530 BMS_chgPowerAvailable "BMS available charge power; raw 4095 = signal not available (SNA)";
CM_ SG_ 530 BMS_acManagerState "High-voltage battery management system: ac manager state";
CM_ SG_ 530 BMS_conditioningRequest "BMS request to enable conditioning so it can attempt FEIM recovery";
CM_ SG_ 530 BMS_smStateRequest "BMS high level state request; raw 9 = signal not available (SNA)";
CM_ SG_ 530 BMS_hvState "BMS high voltage state";
CM_ BO_ 786 "High-voltage battery management system message: thermal status; frame length from the layout, not yet observed on a vehicle bus";
CM_ SG_ 786 BMS_thermalStatusMultiplexer "High-voltage battery management system: thermal status multiplexer";
CM_ SG_ 786 BMS_inletActiveCoolTargetT "Calculated active cooling temperature target at the inlet";
CM_ SG_ 786 BMS_inletPassiveTargetT "Calculated passive temperature target at the inlet";
CM_ SG_ 786 BMS_inletActiveHeatTargetT "Calculated active heating temperature target at the inlet";
CM_ SG_ 786 BMS_requestDischarge "Flag identifying when the Battery Management System (BMS) is requesting the battery pack to be discharged";
CM_ SG_ 786 BMS_activeHeatingWorthwhile "Determination by the Battery Management System (BMS) if active heating is worthwhile";
CM_ SG_ 786 BMS_pcsNoFlowRequest "High-voltage battery management system: pcs no flow request";
CM_ SG_ 786 BMS_minPackTemperature "Minimum pack temperature for consumption by external entities";
CM_ SG_ 786 BMS_noFlowRequest "High-voltage battery management system: no flow request";
CM_ SG_ 786 BMS_maxPackTemperature "Maximum pack temperature for consumption by external entities";
CM_ SG_ 786 BMS_flowRequest "Requested coolant flow rate in liters per minute (LPM) from the Battery Management System (BMS) to the thermal module";
CM_ SG_ 786 BMS_coldStagnationLimit "Minimum temperature at which the pack is allowed to be used as a heat-energy source";
CM_ SG_ 786 BMS_hotStagnationLimit "Maximum temperature at which we allow the pack to be used for heat-energy storage";
CM_ SG_ 786 BMS_hotCellTempLimit "Maximum temperature at which the pack will allow limp mode levels of current";
CM_ SG_ 786 BMS_i2tDeratingEnabled "High-voltage battery management system: i2t derating enabled";
CM_ SG_ 786 BMS_activeCoolCellReferenceT "Desired cell temperature reference which composes the temperature trajectory portion of the active cooling target temperature controls";
CM_ SG_ 786 BMS_activeHeatCellTargetT "Desired cell temperature which feeds as an input to the active heating target temperature, before any additional controls calculations";
CM_ SG_ 786 BMS_powerDissipation "High-voltage battery management system: power dissipation";
CM_ BO_ 1554 "High-voltage battery management system message: uds response; frame length from the layout, not yet observed on a vehicle bus";
CM_ SG_ 1554 BMS_udsResponseData "High-voltage battery management system: uds response data";
CM_ BO_ 1071 "High-voltage battery management system message: v2x info; frame length from the layout, not yet observed on a vehicle bus";
CM_ SG_ 1071 BMS_v2xSoe "High-voltage battery management system: v2x soe; raw 65535 = signal not available (SNA)";
CM_ SG_ 1071 BMS_v2xFullEnergy "High-voltage battery management system: v2x full energy; raw 4095 = signal not available (SNA)";
CM_ SG_ 1071 BMS_v2xPackPower "High-voltage battery management system: v2x pack power; raw 511 = signal not available (SNA)";
CM_ SG_ 1071 BMS_acDischargeBlockedReason "The enumerated reason why the ECU is blocking AC discharge";
CM_ SG_ 1071 BMS_backupTimeRemaining "High-voltage battery management system: backup time remaining; raw 255 = signal not available (SNA)";
CM_ BO_ 754 "High-voltage battery management system message: veh nm; frame length from the layout, not yet observed on a vehicle bus";
CM_ SG_ 754 BMS_nmGoingToSleep "High-voltage battery management system: nm going to sleep";
CM_ SG_ 754 BMS_nmWakeUpBus "High-voltage battery management system: nm wake up bus";
CM_ SG_ 754 BMS_hvsBusAsleep "HVS bus reported as off";
CM_ SG_ 754 BMS_nmKeepAwakeReason "BMS' determined reason to keep CAN awake; raw 0 = signal not available (SNA)";
CM_ SG_ 754 BMS_nmWakeUpReason "BMS' determined reason to wake up CAN";
CM_ BO_ 810 "High-voltage battery management system message: vehicle notifications; frame length from the layout, not yet observed on a vehicle bus";
CM_ SG_ 810 BMS_thermalEventSuspected "Indicates the Battery Management System (BMS) has detected conditions that reflect a possible battery thermal event";
CM_ SG_ 810 BMS_vehicleNotificationsCounter "High-voltage battery management system: vehicle notifications counter";
CM_ SG_ 810 BMS_isolationResistance "Resistance between HV bus and chassis; raw 1023 = signal not available (SNA)";
CM_ SG_ 810 BMS_chgTimeToFull "Estimated time remaining until charge termination percent will be reached; raw 4095 = signal not available (SNA)";
CM_ SG_ 810 BMS_vehicleNotificationsChecksum "High-voltage battery management system: vehicle notifications checksum";
CM_ BO_ 1116 "Charge cable controller message: alert log; frame length from the layout, not yet observed on a vehicle bus";
CM_ SG_ 1116 CC_alertID "Charge cable controller: alert ID";
CM_ SG_ 1116 CC_alertType "Charge cable controller: alert type";
CM_ SG_ 1116 CC_a001_groundResistance "Charge cable controller: a001 ground resistance; raw 4095 = signal not available (SNA)";
CM_ SG_ 1116 CC_a003_gfciRmsCurrent "Charge cable controller: a003 gfci rms current";
CM_ SG_ 1116 CC_a003_gfciRmsCurrentAvg "Charge cable controller: a003 gfci rms current avg";
CM_ SG_ 1116 CC_a003_dcGfciCurrent "Charge cable controller: a003 dc gfci current";
CM_ SG_ 1116 CC_a003_gfciFaultReason "Charge cable controller: a003 gfci fault reason; raw 0 = signal not available (SNA)";
CM_ SG_ 1116 CC_a003_gfciFaultBucket "Charge cable controller: a003 gfci fault bucket";
CM_ SG_ 1116 CC_a004_gfciErrorReason "Charge cable controller: a004 gfci error reason; raw 0 = signal not available (SNA)";
CM_ SG_ 1116 CC_a004_gfciAsicErrorBitfield "Charge cable controller: a004 gfci asic error bitfield";
CM_ SG_ 1116 CC_a004_gfciSelfTestDuty "Charge cable controller: a004 gfci self test duty";
CM_ SG_ 1116 CC_a004_gfciSelfTestCurrent "Charge cable controller: a004 gfci self test current";
CM_ SG_ 1116 CC_a006_line1Current "Charge cable controller: a006 line1 current";
CM_ SG_ 1116 CC_a006_line2Current "Charge cable controller: a006 line2 current";
CM_ SG_ 1116 CC_a006_line3Current "Charge cable controller: a006 line3 current";
CM_ SG_ 1116 CC_a007_inputVoltage "Charge cable controller: a007 input voltage";
CM_ SG_ 1116 CC_a007_inputLineVoltage "Charge cable controller: a007 input line voltage";
CM_ SG_ 1116 CC_a007_inputNeutralVoltage "Charge cable controller: a007 input neutral voltage";
CM_ SG_ 1116 CC_a008_inputVoltage "Charge cable controller: a008 input voltage";
CM_ SG_ 1116 CC_a008_inputLineVoltage "Charge cable controller: a008 input line voltage";
CM_ SG_ 1116 CC_a008_inputNeutralVoltage "Charge cable controller: a008 input neutral voltage";
CM_ SG_ 1116 CC_a010_line1Voltage "Charge cable controller: a010 line1 voltage";
CM_ SG_ 1116 CC_a010_line2Voltage "Charge cable controller: a010 line2 voltage";
CM_ SG_ 1116 CC_a010_line3Voltage "Charge cable controller: a010 line3 voltage";
CM_ SG_ 1116 CC_a010_line1StuckClosed "Charge cable controller: a010 line1 stuck closed";
CM_ SG_ 1116 CC_a010_line2StuckClosed "Charge cable controller: a010 line2 stuck closed";
CM_ SG_ 1116 CC_a010_line3StuckClosed "Charge cable controller: a010 line3 stuck closed";
CM_ SG_ 1116 CC_a011_pcbaTemp "Charge cable controller: a011 pcba temp";
CM_ SG_ 1116 CC_a012_inputThermopile "Charge cable controller: a012 input thermopile";
CM_ SG_ 1116 CC_a012_inputThermopileDvdt "Charge cable controller: a012 input thermopile dvdt";
CM_ SG_ 1116 CC_a013_handleTemp "Charge cable controller: a013 handle temp";
CM_ SG_ 1116 CC_a014_failureCause "Charge cable controller: a014 failure cause";
CM_ SG_ 1116 CC_a014_meterFaultAddress "Charge cable controller: a014 meter fault address";
CM_ SG_ 1116 CC_a014_meterFaultData "Charge cable controller: a014 meter fault data";
CM_ SG_ 1116 CC_a014_meterRetryCount "Charge cable controller: a014 meter retry count";
CM_ SG_ 1116 CC_a015_pilotHighVolage "Charge cable controller: a015 pilot high volage";
CM_ SG_ 1116 CC_a015_smState "Charge cable controller: a015 sm state";
CM_ SG_ 1116 CC_a027_handleTemperature "Charge cable controller: a027 handle temperature";
CM_ SG_ 1116 CC_a027_handleTempFaultReason "Charge cable controller: a027 handle temp fault reason";
CM_ SG_ 1116 CC_a032_meteringSpiCommsFailure "Charge cable controller: a032 metering spi comms failure";
CM_ SG_ 1116 CC_a032_meteringConfigMismatch "Charge cable controller: a032 metering config mismatch";
CM_ SG_ 1116 CC_a033_nominalVoltage "Charge cable controller: a033 nominal voltage";
CM_ SG_ 1116 CC_a033_measuredVoltage "Charge cable controller: a033 measured voltage";
CM_ SG_ 1116 CC_a036_line1Voltage "Charge cable controller: a036 line1 voltage";
CM_ SG_ 1116 CC_a036_line2Voltage "Charge cable controller: a036 line2 voltage";
CM_ SG_ 1116 CC_a036_line3Voltage "Charge cable controller: a036 line3 voltage";
CM_ SG_ 1116 CC_a036_line1StuckOpen "Charge cable controller: a036 line1 stuck open";
CM_ SG_ 1116 CC_a036_line2StuckOpen "Charge cable controller: a036 line2 stuck open";
CM_ SG_ 1116 CC_a036_line3StuckOpen "Charge cable controller: a036 line3 stuck open";
CM_ SG_ 1116 CC_a037_expiredWatchdogModuleId "Charge cable controller: a037 expired watchdog module id";
CM_ SG_ 1116 CC_a037_expiredWatchdogTaskId "Charge cable controller: a037 expired watchdog task id";
CM_ SG_ 1116 CC_a037_expiredWatchdogAppCRC "Charge cable controller: a037 expired watchdog app CRC";
CM_ SG_ 1116 CC_a038_moduleMiaModuleId "Charge cable controller: a038 module mia module id";
CM_ SG_ 1116 CC_a038_moduleMiaTaskId "Charge cable controller: a038 module mia task id";
CM_ SG_ 1116 CC_a038_moduleMiaAppCRC "Charge cable controller: a038 module mia app CRC";
CM_ SG_ 1116 CC_a039_intModuleTemperature "Charge cable controller: a039 int module temperature";
CM_ SG_ 1116 CC_a040_handleTemperature "Charge cable controller: a040 handle temperature";
CM_ SG_ 1116 CC_a041_inputThermopile "Charge cable controller: a041 input thermopile";
CM_ SG_ 1116 CC_a041_inputThermopileDvdt "Charge cable controller: a041 input thermopile dvdt";
CM_ SG_ 1116 CC_a042_pcbaTemperature "Charge cable controller: a042 pcba temperature";
CM_ SG_ 1116 CC_a044_relayCoilVoltage "Charge cable controller: a044 relay coil voltage";
CM_ SG_ 1116 CC_a044_pcbaTemperature "Charge cable controller: a044 pcba temperature";
CM_ BO_ 1132 "Charge cable controller message: alert matrix1; frame length from the layout, not yet observed on a vehicle bus";
CM_ SG_ 1132 CC_a001_gndMonIntrptLineSide "Charge cable controller: a001 gnd mon intrpt line side";
CM_ SG_ 1132 CC_a002_gndMonIntrptLoadSide "Charge cable controller: a002 gnd mon intrpt load side";
CM_ SG_ 1132 CC_a003_CCIDTripped "Charge cable controller: a003 CCID tripped";
CM_ SG_ 1132 CC_a004_CCIDSelfTestFault "Charge cable controller: a004 CCID self test fault";
CM_ SG_ 1132 CC_a005_groundedNeutral "Charge cable controller: a005 grounded neutral";
CM_ SG_ 1132 CC_a006_inputOverCurrent "Charge cable controller: a006 input over current";
CM_ SG_ 1132 CC_a007_inputOverVoltage "Charge cable controller: a007 input over voltage";
CM_ SG_ 1132 CC_a008_inputUnderVoltage "Charge cable controller: a008 input under voltage";
CM_ SG_ 1132 CC_a009_inputMiswired "Charge cable controller: a009 input miswired";
CM_ SG_ 1132 CC_a010_contactorWelded "Charge cable controller: a010 contactor welded";
CM_ SG_ 1132 CC_a011_ambientOT "Charge cable controller: a011 ambient OT";
CM_ SG_ 1132 CC_a012_wallPlugOT "Charge cable controller: a012 wall plug OT";
CM_ SG_ 1132 CC_a013_vehConnOT "Charge cable controller: a013 veh conn OT";
CM_ SG_ 1132 CC_a014_mcuSelfTestFault "Charge cable controller: a014 mcu self test fault";
CM_ SG_ 1132 CC_a015_PilotAFault "Charge cable controller: a015 pilot a fault";
CM_ SG_ 1132 CC_a016_PilotBFault "Charge cable controller: a016 pilot b fault";
CM_ SG_ 1132 CC_a017_PilotCFault "Charge cable controller: a017 pilot c fault";
CM_ SG_ 1132 CC_a018_PilotDFault "Charge cable controller: a018 pilot d fault";
CM_ SG_ 1132 CC_a019_proxDisconnected "Charge cable controller: a019 prox disconnected";
CM_ SG_ 1132 CC_a020_3vRailIncorrect "Charge cable controller: a020 3v rail incorrect";
CM_ SG_ 1132 CC_a021_CB_noMaster "Charge cable controller: a021 CB no master";
CM_ SG_ 1132 CC_a022_CB_tooManyMasters "Charge cable controller: a022 CB too many masters";
CM_ SG_ 1132 CC_a023_CB_tooManySlaves "Charge cable controller: a023 CB too many slaves";
CM_ SG_ 1132 CC_a024_CB_masterISetTooLow "Charge cable controller: a024 CB master i set too low";
CM_ SG_ 1132 CC_a025_evseTemp "Charge cable controller: a025 evse temp";
CM_ SG_ 1132 CC_a026_wallPlugTemp "Charge cable controller: a026 wall plug temp";
CM_ SG_ 1132 CC_a027_vehicleHandleTemp "Charge cable controller: a027 vehicle handle temp";
CM_ SG_ 1132 CC_a028_CB_rotarySelect "Charge cable controller: a028 CB rotary select";
CM_ SG_ 1132 CC_a029_PilotFFault "Charge cable controller: a029 pilot f fault";
CM_ SG_ 1132 CC_a030_masterSlaveMismatch "Charge cable controller: a030 master slave mismatch";
CM_ SG_ 1132 CC_a031_pllLockLost "Charge cable controller: a031 pll lock lost";
CM_ SG_ 1132 CC_a032_meteringFailure "Charge cable controller: a032 metering failure";
CM_ SG_ 1132 CC_a033_vRefOutOfRange "Charge cable controller: a033 v ref out of range";
CM_ SG_ 1132 CC_a034_bootAlert "Charge cable controller: a034 boot alert";
CM_ SG_ 1132 CC_a035_CCIDCalibration "Charge cable controller: a035 CCID calibration";
CM_ SG_ 1132 CC_a036_contactorStuckOpen "Charge cable controller: a036 contactor stuck open";
CM_ SG_ 1132 CC_a037_internalModuleWatchdogEx "Charge cable controller: a037 internal module watchdog expired";
CM_ SG_ 1132 CC_a038_internalModuleMia "Charge cable controller: a038 internal module mia";
CM_ SG_ 1132 CC_a039_internalModuleOverTemp "Charge cable controller: a039 internal module over temp";
CM_ SG_ 1132 CC_a040_handleTempFoldback "Charge cable controller: a040 handle temp foldback";
CM_ SG_ 1132 CC_a041_inputWiringFoldback "Charge cable controller: a041 input wiring foldback";
CM_ SG_ 1132 CC_a042_pcbaTempFoldback "Charge cable controller: a042 pcba temp foldback";
CM_ SG_ 1132 CC_a043_configurationRequired "Charge cable controller: a043 configuration required";
CM_ SG_ 1132 CC_a044_relayCoilVoltageRational "Charge cable controller: a044 relay coil voltage rationality";
CM_ SG_ 1132 CC_a045_ACPowerLoss "Charge cable controller: a045 AC power loss";
CM_ SG_ 1132 CC_a046_GFCIConfigInvalid "Charge cable controller: a046 GFCI config invalid";
CM_ SG_ 1132 CC_a047_MDMotorContFault "Charge cable controller: a047 MD motor cont fault";
CM_ SG_ 1132 CC_a048_ACMDAdapterFault "Charge cable controller: a048 ACMD adapter fault";
CM_ SG_ 1132 CC_a049_rs485Fault "Charge cable controller: a049 rs485 fault";
CM_ SG_ 1132 CC_a050_eFuseFault "Charge cable controller: a050 e fuse fault";
CM_ SG_ 1132 CC_a051_chcCriticalFault "Charge cable controller: a051 chc critical fault";
CM_ SG_ 1132 CC_a052_vRefOutOfRangePWM "Charge cable controller: a052 v ref out of range PWM";
CM_ SG_ 1132 CC_a057_chcVitalsRequestFailure "Charge cable controller: a057 chc vitals request failure";
CM_ SG_ 1132 CC_a060_persistenceFault "Charge cable controller: a060 persistence fault";
CM_ SG_ 1132 CC_a061_unfinishedCommissioning "Charge cable controller: a061 unfinished commissioning";
CM_ BO_ 796 "Charge cable controller message: chg status; frame length from the layout, not yet observed on a vehicle bus";
CM_ SG_ 796 CC_currentLimit "Maximum allowable AC current the wall connector is willing to provide; raw 255 = signal not available (SNA)";
CM_ SG_ 796 CC_pilotState "State of pilot signal reported by the wall connector; raw 3 = signal not available (SNA)";
CM_ SG_ 796 CC_numPhases "Number of AC phases expected by wall connector; raw 0 = signal not available (SNA)";
CM_ SG_ 796 CC_line1Voltage "RMS voltage on L1 terminal of wall connector; raw 511 = signal not available (SNA)";
CM_ SG_ 796 CC_gridGrounding "Grouding scheme expected by the wall connector; raw 2 = signal not available (SNA)";
CM_ SG_ 796 CC_deltaTransformer "Grid configuration expected by the wall connector";
CM_ SG_ 796 CC_numVehCharging "Number of vehicles charging in wall connector load sharing group";
CM_ SG_ 796 CC_line2Voltage "RMS voltage on L2 terminal of wall connector; raw 511 = signal not available (SNA)";
CM_ SG_ 796 CC_line3Voltage "RMS voltage on L3 terminal of wall connector; raw 511 = signal not available (SNA)";
CM_ SG_ 796 CC_groundResistance "Charge cable controller: ground resistance; raw 4095 = signal not available (SNA)";
CM_ BO_ 797 "Charge cable controller message: chg status2; frame length from the layout, not yet observed on a vehicle bus";
CM_ SG_ 797 CC_chgStatus2Index "Charge cable controller: chg status2 index";
CM_ SG_ 797 CC_buttonState "Charge cable controller: button state";
CM_ SG_ 797 EVSE_v2xSupport "Charge cable controller: v2x support";
CM_ SG_ 797 EVSE_v2xHandshakeStart "Charge cable controller: v2x handshake start";
CM_ SG_ 797 EVSE_v2xSessionType "Charge cable controller: v2x session type; raw 0 = signal not available (SNA)";
CM_ BO_ 812 "Charge cable controller message: log data; frame length from the layout, not yet observed on a vehicle bus";
CM_ SG_ 812 CC_logIndex "Charge cable controller: log index";
CM_ SG_ 812 CC_activeConnectorID "Site identifier of active charge connector";
CM_ SG_ 812 CC_temperature1 "Charge cable vehicle connector temperature";
CM_ SG_ 812 CC_temperature2 "Charge cable vehicle connector temperature";
CM_ SG_ 812 CC_temperature3 "Charge cable vehicle connector temperature";
CM_ SG_ 812 CC_contactor1Closed "State of contactor 1 in wall connector";
CM_ SG_ 812 CC_contactor2Closed "State of contactor 1 in wall connector";
CM_ SG_ 812 CC_temperature4 "Charge cable vehicle connector temperature";
CM_ SG_ 812 CC_conn1Current "AC current on connector 1 in wall charger load sharing group; raw 255 = signal not available (SNA)";
CM_ SG_ 812 CC_conn2Current "AC current on connector 2 in wall charger load sharing group; raw 255 = signal not available (SNA)";
CM_ SG_ 812 CC_conn3Current "AC current on connector 3 in wall charger load sharing group; raw 255 = signal not available (SNA)";
CM_ SG_ 812 CC_conn4Current "AC current on connector 4 in wall charger load sharing group; raw 255 = signal not available (SNA)";
CM_ SG_ 812 CC_lifetimei2t "Charge cable controller: lifetimei2t";
CM_ SG_ 812 CC_lifetimeCtrCycles "Charge cable controller: lifetime ctr cycles";
CM_ SG_ 812 CC_lifetimeCtrCyclesLoaded "Charge cable controller: lifetime ctr cycles loaded";
CM_ SG_ 812 CC_lifetimeAlertCount "Charge cable controller: lifetime alert count";
CM_ SG_ 812 CC_lifetimeThermalFoldbacks "Charge cable controller: lifetime thermal foldbacks";
CM_ SG_ 812 CC_lifetimeAvgStartupTemp "Charge cable controller: lifetime avg startup temp";
CM_ BO_ 870 "CMPD ECU message: info; frame length from the layout, not yet observed on a vehicle bus";
CM_ SG_ 870 CMPD_infoIndex "CMPD ECU: info index";
CM_ SG_ 870 CMPD_infoBuildType "CMPD ECU: info build type";
CM_ SG_ 870 CMPD_infoBuildConfigId "CMPD ECU: info build config id";
CM_ SG_ 870 CMPD_infoHardwareId "CMPD ECU: info hardware id";
CM_ SG_ 870 CMPD_infoComponentId "CMPD ECU: info component id";
CM_ SG_ 870 CMPD_infoPcbaId "CMPD ECU: info pcba id";
CM_ SG_ 870 CMPD_infoAssemblyId "CMPD ECU: info assembly id; raw 255 = signal not available (SNA)";
CM_ SG_ 870 CMPD_infoUsageId "CMPD ECU: info usage id";
CM_ SG_ 870 CMPD_infoSubUsageId "CMPD ECU: info sub usage id";
CM_ BO_ 679 "CMPD ECU message: state; frame length from the layout, not yet observed on a vehicle bus";
CM_ SG_ 679 CMPD_speedRPM "Reports compressor speed.";
CM_ SG_ 679 CMPD_speedDuty "Reports compressor speed duty cycle percentage.";
CM_ SG_ 679 CMPD_inputHVPower "Measures compressor input high voltage (HV) power consumption.";
CM_ SG_ 679 CMPD_inputHVCurrent "Measures compressor input high voltage (HV) current draw.";
CM_ SG_ 679 CMPD_inputHVVoltage "Measures compressor input high voltage (HV) level.";
CM_ SG_ 679 CMPD_2ShuntModeActive "Indicates the compressor motor control is running using only two current shunt resistors instead of three.";
CM_ SG_ 679 CMPD_powerLimitActive "Indicates the compressor power limit is active.";
CM_ SG_ 679 CMPD_state "Reports compressor operational state; raw 15 = signal not available (SNA)";
CM_ SG_ 679 CMPD_wasteHeatState "Reports compressor waste heat recovery state.";
CM_ SG_ 679 CMPD_powerLimitTooLowToStart "Indicates the compressor power limit is too low to start the compressor.";
CM_ SG_ 679 CMPD_ready "Indicates the compressor is ready to start.";
CM_ BO_ 1559 "CMPD ECU message: uds response; frame length from the layout, not yet observed on a vehicle bus";
CM_ SG_ 1559 CMPD_udsResponseData "CMPD ECU: uds response data";
CM_ BO_ 867 "A/C compressor message: info; frame length from the layout, not yet observed on a vehicle bus";
CM_ SG_ 867 CMP_infoIndex "A/C compressor: info index";
CM_ SG_ 867 CMP_infoBuildType "A/C compressor: info build type";
CM_ SG_ 867 CMP_infoBuildConfigId "A/C compressor: info build config id";
CM_ SG_ 867 CMP_infoHardwareId "A/C compressor: info hardware id";
CM_ SG_ 867 CMP_infoComponentId "A/C compressor: info component id";
CM_ SG_ 867 CMP_infoPcbaId "A/C compressor: info pcba id";
CM_ SG_ 867 CMP_infoAssemblyId "A/C compressor: info assembly id; raw 255 = signal not available (SNA)";
CM_ SG_ 867 CMP_infoUsageId "A/C compressor: info usage id";
CM_ SG_ 867 CMP_infoSubUsageId "A/C compressor: info sub usage id";
CM_ SG_ 867 CMP_infoPlatformType "A/C compressor: info platform type";
CM_ SG_ 867 CMP_infoAppCrc "A/C compressor: info app crc";
CM_ SG_ 867 CMP_infoBootUdsProtoVersion "A/C compressor: info boot uds proto version";
CM_ SG_ 867 CMP_infoBootCrc "A/C compressor: info boot crc";
CM_ BO_ 1555 "A/C compressor message: uds response; frame length from the layout, not yet observed on a vehicle bus";
CM_ SG_ 1555 CMP_udsResponseData "A/C compressor: uds response data";
CM_ BO_ 1767 "Charge port controller message: iso tp pipe to pncd; frame length from the layout, not yet observed on a vehicle bus";
CM_ SG_ 1767 CP_isoTpToPncdData "Charge port controller: iso tp to pncd data";
CM_ BO_ 1294 "Charge port controller message: alert log; frame length from the layout, not yet observed on a vehicle bus";
CM_ SG_ 1294 CP_alertID "Charge port controller: alert ID";
CM_ SG_ 1294 CP_alertType "Charge port controller: alert type";
CM_ SG_ 1294 CP_a004_proximityV "Charge port controller: a004 proximity v";
CM_ SG_ 1294 CP_a004_cc1Voltage "Charge port controller: a004 cc1 voltage";
CM_ SG_ 1294 CP_a004_cc2Voltage "Charge port controller: a004 cc2 voltage";
CM_ SG_ 1294 CP_a005_cc1Voltage "Charge port controller: a005 cc1 voltage";
CM_ SG_ 1294 CP_a005_cc2Voltage "Charge port controller: a005 cc2 voltage";
CM_ SG_ 1294 CP_a005_gbdcState "Charge port controller: a005 gbdc state";
CM_ SG_ 1294 CP_a005_packCurrent "Charge port controller: a005 pack current";
CM_ SG_ 1294 CP_a005_evseCurrent "Charge port controller: a005 evse current";
CM_ SG_ 1294 CP_a005_superchargerConnected "Charge port controller: a005 supercharger connected";
CM_ SG_ 1294 CP_a005_latchEngaged "Charge port controller: a005 latch engaged";
CM_ SG_ 1294 CP_a006_BMS_FC_limits_MIA "Charge port controller: a006 BMS FC limits MIA";
CM_ SG_ 1294 CP_a006_BMS_chargeStatus_MIA "Charge port controller: a006 BMS charge status MIA";
CM_ SG_ 1294 CP_a006_BMS_dcChargeLimits_MIA "Charge port controller: a006 BMS dc charge limits MIA";
CM_ SG_ 1294 CP_a006_BMS_hvPackStatus_MIA "Charge port controller: a006 BMS hv pack status MIA";
CM_ SG_ 1294 CP_a006_BMS_kwhCounter_MIA "Charge port controller: a006 BMS kwh counter MIA";
CM_ SG_ 1294 CP_a006_BMS_socStatus_MIA "Charge port controller: a006 BMS soc status MIA";
CM_ SG_ 1294 CP_a006_BMS_v2xInfo_MIA "Charge port controller: a006 BMS v2x info MIA";
CM_ SG_ 1294 CP_a006_BMS_bmbMinMax_MIA "Charge port controller: a006 BMS bmb min max MIA";
CM_ SG_ 1294 CP_a006_BMS_evsePackInfo_MIA "Charge port controller: a006 BMS evse pack info MIA";
CM_ SG_ 1294 CP_a006_BMS_cpFaultLineStatus_MI "Charge port controller: a006 BMS cp fault line status MIA";
CM_ SG_ 1294 CP_a006_BMS_eptoStatus_MIA "Charge port controller: a006 BMS epto status MIA";
CM_ SG_ 1294 CP_a008_data1 "Charge port controller: a008 data1";
CM_ SG_ 1294 CP_a008_data2 "Charge port controller: a008 data2";
CM_ SG_ 1294 CP_a008_FlashWarning "Charge port controller: a008 flash warning";
CM_ SG_ 1294 CP_a008_RAMconst_Warning "Charge port controller: a008 RA mconst warning";
CM_ SG_ 1294 CP_a008_RAMconst_Fault "Charge port controller: a008 RA mconst fault";
CM_ SG_ 1294 CP_a008_AllMemory_warnings "Charge port controller: a008 all memory warnings";
CM_ SG_ 1294 CP_a008_StackAlert "Charge port controller: a008 stack alert";
CM_ SG_ 1294 CP_a008_stackUsed "Charge port controller: a008 stack used";
CM_ SG_ 1294 CP_a009_cover1OpenCounts "Charge port controller: a009 cover1 open counts";
CM_ SG_ 1294 CP_a009_cover2OpenCounts "Charge port controller: a009 cover2 open counts";
CM_ SG_ 1294 CP_a009_cover1State "Charge port controller: a009 cover1 state; raw 4 = signal not available (SNA)";
CM_ SG_ 1294 CP_a009_cover2State "Charge port controller: a009 cover2 state; raw 4 = signal not available (SNA)";
CM_ SG_ 1294 CP_a010_periodValid "Charge port controller: a010 period valid";
CM_ SG_ 1294 CP_a010_widthValid "Charge port controller: a010 width valid";
CM_ SG_ 1294 CP_a010_voltageValid "Charge port controller: a010 voltage valid";
CM_ SG_ 1294 CP_a010_pilotHigh "Charge port controller: a010 pilot high";
CM_ SG_ 1294 CP_a010_pilotLow "Charge port controller: a010 pilot low";
CM_ SG_ 1294 CP_a010_evseAccept "Charge port controller: a010 evse accept";
CM_ SG_ 1294 CP_a010_pilotPWMdetected "Charge port controller: a010 pilot PW mdetected";
CM_ SG_ 1294 CP_a011_eepromErrorType "Charge port controller: a011 eeprom error type";
CM_ SG_ 1294 CP_a015_apsVoltageOV "Charge port controller: a015 aps voltage OV";
CM_ SG_ 1294 CP_a016_apsVoltageUV "Charge port controller: a016 aps voltage UV";
CM_ SG_ 1294 CP_a017_5V_VoltageOV "Charge port controller: a017 5 v voltage OV";
CM_ SG_ 1294 CP_a018_5V_VoltageUV "Charge port controller: a018 5 v voltage UV";
CM_ SG_ 1294 CP_a023_stopChargeReason "Charge port controller: a023 stop charge reason";
CM_ SG_ 1294 CP_a023_failureReason "Charge port controller: a023 failure reason";
CM_ SG_ 1294 CP_a023_chargeAttempts "Charge port controller: a023 charge attempts";
CM_ SG_ 1294 CP_a028_canEnable "Charge port controller: a028 can enable";
CM_ SG_ 1294 CP_a028_hardlineEnable "Charge port controller: a028 hardline enable";
CM_ SG_ 1294 CP_a029_CP_pilot "Charge port controller: a029 CP pilot; raw 7 = signal not available (SNA)";
CM_ SG_ 1294 CP_a029_CP_proximity "Charge port controller: a029 CP proximity; raw 0 = signal not available (SNA)";
CM_ SG_ 1294 CP_a029_CP_chargeDoorOpen "Charge port controller: a029 CP charge door open";
CM_ SG_ 1294 CP_a031_apsVoltage "Charge port controller: a031 aps voltage";
CM_ SG_ 1294 CP_a031_doorCountsFiltered "Charge port controller: a031 door counts filtered";
CM_ SG_ 1294 CP_a031_inductiveSensorFiltered "Charge port controller: a031 inductive sensor filtered";
CM_ SG_ 1294 CP_a031_hallSensorFiltered "Charge port controller: a031 hall sensor filtered";
CM_ SG_ 1294 CP_a032_apsVoltage "Charge port controller: a032 aps voltage";
CM_ SG_ 1294 CP_a032_doorCountsFiltered "Charge port controller: a032 door counts filtered";
CM_ SG_ 1294 CP_a032_inductiveSensorFiltered "Charge port controller: a032 inductive sensor filtered";
CM_ SG_ 1294 CP_a032_hallSensorFiltered "Charge port controller: a032 hall sensor filtered";
CM_ SG_ 1294 CP_a035_latchState "Charge port controller: a035 latch state; raw 0 = signal not available (SNA)";
CM_ SG_ 1294 CP_a035_stateLeverMovedFrom "Charge port controller: a035 state lever moved from";
CM_ SG_ 1294 CP_a035_latchOffset "Charge port controller: a035 latch offset";
CM_ SG_ 1294 CP_a035_inletID "Charge port controller: a035 inlet ID";
CM_ SG_ 1294 CP_a036_latchCountsFiltered "Charge port controller: a036 latch counts filtered";
CM_ SG_ 1294 CP_a036_latchState "Charge port controller: a036 latch state; raw 0 = signal not available (SNA)";
CM_ SG_ 1294 CP_a036_CHG_InsertEnable "Charge port controller: a036 CHG insert enable";
CM_ SG_ 1294 CP_a036_CP_latchEnableCmd "Charge port controller: a036 CP latch enable cmd";
CM_ SG_ 1294 CP_a036_CP_apsVoltage "Charge port controller: a036 CP aps voltage";
CM_ SG_ 1294 CP_a036_inletID "Charge port controller: a036 inlet ID";
CM_ SG_ 1294 CP_a037_latchCountsFiltered "Charge port controller: a037 latch counts filtered";
CM_ SG_ 1294 CP_a037_latchState "Charge port controller: a037 latch state; raw 0 = signal not available (SNA)";
CM_ SG_ 1294 CP_a037_CHG_InsertEnable "Charge port controller: a037 CHG insert enable";
CM_ SG_ 1294 CP_a037_CP_latchEnableCmd "Charge port controller: a037 CP latch enable cmd";
CM_ SG_ 1294 CP_a037_CP_apsVoltage "Charge port controller: a037 CP aps voltage";
CM_ SG_ 1294 CP_a037_inletID "Charge port controller: a037 inlet ID";
CM_ SG_ 1294 CP_a037_latchSwitchState "Charge port controller: a037 latch switch state";
CM_ SG_ 1294 CP_a038_latchCountsFiltered "Charge port controller: a038 latch counts filtered";
CM_ SG_ 1294 CP_a038_latchState "Charge port controller: a038 latch state; raw 0 = signal not available (SNA)";
CM_ SG_ 1294 CP_a038_CHG_InsertEnable "Charge port controller: a038 CHG insert enable";
CM_ SG_ 1294 CP_a038_CP_latchEnableCmd "Charge port controller: a038 CP latch enable cmd";
CM_ SG_ 1294 CP_a038_CP_apsVoltage "Charge port controller: a038 CP aps voltage";
CM_ SG_ 1294 CP_a038_inletID "Charge port controller: a038 inlet ID";
CM_ SG_ 1294 CP_a041_doorCounts "Charge port controller: a041 door counts";
CM_ SG_ 1294 CP_a041_inductiveSensorFiltered "Charge port controller: a041 inductive sensor filtered";
CM_ SG_ 1294 CP_a041_hallSensorFiltered "Charge port controller: a041 hall sensor filtered";
CM_ SG_ 1294 CP_a042_doorCounts "Charge port controller: a042 door counts";
CM_ SG_ 1294 CP_a042_inductiveSensorFiltered "Charge port controller: a042 inductive sensor filtered";
CM_ SG_ 1294 CP_a042_hallSensorFiltered "Charge port controller: a042 hall sensor filtered";
CM_ SG_ 1294 CP_a043_driftFlag "Charge port controller: a043 drift flag";
CM_ SG_ 1294 CP_a043_wrongDirectionFlag "Charge port controller: a043 wrong direction flag";
CM_ SG_ 1294 CP_a043_outOfRangeFlag "Charge port controller: a043 out of range flag";
CM_ SG_ 1294 CP_a043_doorPotFiltered "Charge port controller: a043 door pot filtered";
CM_ SG_ 1294 CP_a043_doorVelocity "Charge port controller: a043 door velocity";
CM_ SG_ 1294 CP_a043_idleDoorPot "Charge port controller: a043 idle door pot";
CM_ SG_ 1294 CP_a044_HVP_cpControl_MIA "Charge port controller: a044 HVP cp control MIA";
CM_ SG_ 1294 CP_a045_VCSEC_authentication_MIA "Charge port controller: a045 VCSEC authentication MIA";
CM_ SG_ 1294 CP_a045_VCSEC_requests_MIA "Charge port controller: a045 VCSEC requests MIA";
CM_ SG_ 1294 CP_a046_FC_status_flag "Charge port controller: a046 FC status flag";
CM_ SG_ 1294 CP_a046_FC_limits_flag "Charge port controller: a046 FC limits flag";
CM_ SG_ 1294 CP_a046_FC_maxLimits_flag "Charge port controller: a046 FC max limits flag";
CM_ SG_ 1294 CP_a046_FC_statusHighPower_flag "Charge port controller: a046 FC status high power flag";
CM_ SG_ 1294 CP_a046_FC_limitsHighPower_flag "Charge port controller: a046 FC limits high power flag";
CM_ SG_ 1294 CP_a046_FC_maxLimitsHighPower "Charge port controller: a046 FC max limits high power";
CM_ SG_ 1294 CP_a046_CC_chgStatus_flag "Charge port controller: a046 CC chg status flag";
CM_ SG_ 1294 CP_a047_okToUseHighPower_MIA "Charge port controller: a047 ok to use high power MIA";
CM_ SG_ 1294 CP_a047_LVPowerState_MIA "Charge port controller: a047 LV power state MIA";
CM_ SG_ 1294 CP_a047_sensors_MIA "Charge port controller: a047 sensors MIA";
CM_ SG_ 1294 CP_a047_vehNm_MIA "Charge port controller: a047 veh nm MIA";
CM_ SG_ 1294 CP_a049_proximity "Charge port controller: a049 proximity; raw 0 = signal not available (SNA)";
CM_ SG_ 1294 CP_a050_latch1NotConnected "Charge port controller: a050 latch1 not connected";
CM_ SG_ 1294 CP_a050_latch2NotConnected "Charge port controller: a050 latch2 not connected";
CM_ SG_ 1294 CP_a050_maxLatchCurrentSeen "Charge port controller: a050 max latch current seen";
CM_ SG_ 1294 CP_a050_minLatchCurrentBelowThre "Charge port controller: a050 min latch current below threshold";
CM_ SG_ 1294 CP_a050_binaryCurrentProfile "Charge port controller: a050 binary current profile";
CM_ SG_ 1294 CP_a050_consecutiveAlertCount "Charge port controller: a050 consecutive alert count";
CM_ SG_ 1294 CP_a051_doorCountsFiltered "Charge port controller: a051 door counts filtered";
CM_ SG_ 1294 CP_a054_latchCountsFiltered "Charge port controller: a054 latch counts filtered";
CM_ SG_ 1294 CP_a054_latchState "Charge port controller: a054 latch state; raw 0 = signal not available (SNA)";
CM_ SG_ 1294 CP_a054_CHG_InsertEnable "Charge port controller: a054 CHG insert enable";
CM_ SG_ 1294 CP_a054_CP_latchEnableCmd "Charge port controller: a054 CP latch enable cmd";
CM_ SG_ 1294 CP_a054_CP_apsVoltage "Charge port controller: a054 CP aps voltage";
CM_ SG_ 1294 CP_a054_CP_proximity "Charge port controller: a054 CP proximity; raw 0 = signal not available (SNA)";
CM_ SG_ 1294 CP_a054_inletID "Charge port controller: a054 inlet ID";
CM_ SG_ 1294 CP_a056_latchState "Charge port controller: a056 latch state; raw 0 = signal not available (SNA)";
CM_ SG_ 1294 CP_a056_CHG_InsertEnable "Charge port controller: a056 CHG insert enable";
CM_ SG_ 1294 CP_a056_CP_latchEnableCmd "Charge port controller: a056 CP latch enable cmd";
CM_ SG_ 1294 CP_a056_CP_proximity "Charge port controller: a056 CP proximity; raw 0 = signal not available (SNA)";
CM_ SG_ 1294 CP_a056_packCurrent "Charge port controller: a056 pack current";
CM_ SG_ 1294 CP_a058_CP_pilot "Charge port controller: a058 CP pilot; raw 7 = signal not available (SNA)";
CM_ SG_ 1294 CP_a058_CC_pilot "Charge port controller: a058 CC pilot; raw 3 = signal not available (SNA)";
CM_ SG_ 1294 CP_a058_FC_status "Charge port controller: a058 FC status; raw 0 = signal not available (SNA)";
CM_ SG_ 1294 CP_a058_latchState "Charge port controller: a058 latch state; raw 0 = signal not available (SNA)";
CM_ SG_ 1294 CP_a058_CP_proximity "Charge port controller: a058 CP proximity; raw 0 = signal not available (SNA)";
CM_ SG_ 1294 CP_a058_acNumRetries "Charge port controller: a058 ac num retries";
CM_ SG_ 1294 CP_a058_acRetryTimeoutS "Charge port controller: a058 ac retry timeout s";
CM_ SG_ 1294 CP_a060_PCS_chgStatus_MIA "Charge port controller: a060 PCS chg status MIA";
CM_ SG_ 1294 CP_a060_PCS_chgLineStatus_MIA "Charge port controller: a060 PCS chg line status MIA";
CM_ SG_ 1294 CP_a060_PCS2_v2xInfo_MIA "Charge port controller: a060 PCS2 v2x info MIA";
CM_ SG_ 1294 CP_a060_PCS2_v2xInfo2_MIA "Charge port controller: a060 PCS2 v2x info2 MIA";
CM_ SG_ 1294 CP_a061_controlState "Charge port controller: a061 control state";
CM_ SG_ 1294 CP_a061_lastControlState "Charge port controller: a061 last control state";
CM_ SG_ 1294 CP_a061_chipState "Charge port controller: a061 chip state";
CM_ SG_ 1294 CP_a061_timeMsInControlState "Charge port controller: a061 time ms in control state";
CM_ SG_ 1294 CP_a062_FC_status "Charge port controller: a062 FC status; raw 0 = signal not available (SNA)";
CM_ SG_ 1294 CP_a062_FC_type "Charge port controller: a062 FC type; raw 7 = signal not available (SNA)";
CM_ SG_ 1294 CP_a063_FC_status "Charge port controller: a063 FC status; raw 0 = signal not available (SNA)";
CM_ SG_ 1294 CP_a063_FC_type "Charge port controller: a063 FC type; raw 7 = signal not available (SNA)";
CM_ SG_ 1294 CP_a066_pilotHigh "Charge port controller: a066 pilot high";
CM_ SG_ 1294 CP_a066_pilotLow "Charge port controller: a066 pilot low";
CM_ SG_ 1294 CP_a066_proximity "Charge port controller: a066 proximity; raw 0 = signal not available (SNA)";
CM_ SG_ 1294 CP_a067_cc1Voltage "Charge port controller: a067 cc1 voltage";
CM_ SG_ 1294 CP_a067_cc2Voltage "Charge port controller: a067 cc2 voltage";
CM_ SG_ 1294 CP_a068_doorCountsFiltered "Charge port controller: a068 door counts filtered";
CM_ SG_ 1294 CP_a068_doorClosed "Charge port controller: a068 door closed";
CM_ SG_ 1294 CP_a068_inductiveSensorFiltered "Charge port controller: a068 inductive sensor filtered";
CM_ SG_ 1294 CP_a068_hallSensorFiltered "Charge port controller: a068 hall sensor filtered";
CM_ SG_ 1294 CP_a068_doorPresent "Charge port controller: a068 door present";
CM_ SG_ 1294 CP_a069_inductiveSensor_raw "Charge port controller: a069 inductive sensor raw";
CM_ SG_ 1294 CP_a069_inductiveErrorAmplitude "Charge port controller: a069 inductive error amplitude";
CM_ SG_ 1294 CP_a069_inductiveErrorWatchdog "Charge port controller: a069 inductive error watchdog";
CM_ SG_ 1294 CP_a069_inductiveErrorOverRange "Charge port controller: a069 inductive error over range";
CM_ SG_ 1294 CP_a069_inductiveErrorUnderRange "Charge port controller: a069 inductive error under range";
CM_ SG_ 1294 CP_a071_expectedMessage "Charge port controller: a071 expected message";
CM_ SG_ 1294 CP_a072_currentMessage "Charge port controller: a072 current message";
CM_ SG_ 1294 CP_a072_readyToChargeExpired "Charge port controller: a072 ready to charge expired";
CM_ SG_ 1294 CP_a072_commsSetupExpired "Charge port controller: a072 comms setup expired";
CM_ SG_ 1294 CP_a072_cableCheckExpired "Charge port controller: a072 cable check expired";
CM_ SG_ 1294 CP_a072_preChargeExpired "Charge port controller: a072 pre charge expired";
CM_ SG_ 1294 CP_a074_slacState "Charge port controller: a074 slac state";
CM_ SG_ 1294 CP_a074_slacErrorCode "Charge port controller: a074 slac error code";
CM_ SG_ 1294 CP_a074_sdpNoDiscoveryResponse "Charge port controller: a074 sdp no discovery response";
CM_ SG_ 1294 CP_a074_evseMeasuredAtten "Charge port controller: a074 evse measured atten";
CM_ SG_ 1294 CP_a075_evccState "Charge port controller: a075 evcc state";
CM_ SG_ 1294 CP_a075_currentMessage "Charge port controller: a075 current message";
CM_ SG_ 1294 CP_a075_exiUnpackFailed "Charge port controller: a075 exi unpack failed";
CM_ SG_ 1294 CP_a075_failedResponseCode "Charge port controller: a075 failed response code";
CM_ SG_ 1294 CP_a075_evseMeasuredAtten "Charge port controller: a075 evse measured atten";
CM_ SG_ 1294 CP_a075_evseEmergencyChgEnd "Charge port controller: a075 evse emergency chg end";
CM_ SG_ 1294 CP_a075_initFailureType "Charge port controller: a075 init failure type";
CM_ SG_ 1294 CP_a075_evccSocketErrTx "Charge port controller: a075 evcc socket err tx";
CM_ SG_ 1294 CP_a075_evccSocketErrRx "Charge port controller: a075 evcc socket err rx";
CM_ SG_ 1294 CP_a075_commsFailReason "Charge port controller: a075 comms fail reason";
CM_ SG_ 1294 CP_a077_mac1Invalid "Charge port controller: a077 mac1 invalid";
CM_ SG_ 1294 CP_a077_mac2Invalid "Charge port controller: a077 mac2 invalid";
CM_ SG_ 1294 CP_a077_macsMatching "Charge port controller: a077 macs matching";
CM_ SG_ 1294 CP_a078_VC_tempAmbientFiltered "Charge port controller: a078 VC temp ambient filtered; raw 0 = signal not available (SNA)";
CM_ SG_ 1294 CP_a078_pinTemperature1 "Charge port controller: a078 pin temperature1; raw 255 = signal not available (SNA)";
CM_ SG_ 1294 CP_a078_pinTemperature2 "Charge port controller: a078 pin temperature2; raw 255 = signal not available (SNA)";
CM_ SG_ 1294 CP_a078_pinTemperature3 "Charge port controller: a078 pin temperature3; raw 255 = signal not available (SNA)";
CM_ SG_ 1294 CP_a079_VC_tempAmbientFiltered "Charge port controller: a079 VC temp ambient filtered; raw 0 = signal not available (SNA)";
CM_ SG_ 1294 CP_a079_pinTemperature1 "Charge port controller: a079 pin temperature1; raw 255 = signal not available (SNA)";
CM_ SG_ 1294 CP_a079_pinTemperature2 "Charge port controller: a079 pin temperature2; raw 255 = signal not available (SNA)";
CM_ SG_ 1294 CP_a079_pinTemperature3 "Charge port controller: a079 pin temperature3; raw 255 = signal not available (SNA)";
CM_ SG_ 1294 CP_a084_proximityV "Charge port controller: a084 proximity v";
CM_ SG_ 1294 CP_a084_cc1Voltage "Charge port controller: a084 cc1 voltage";
CM_ SG_ 1294 CP_a084_cc2Voltage "Charge port controller: a084 cc2 voltage";
CM_ SG_ 1294 CP_a085_absoluteTempFault "Charge port controller: a085 absolute temp fault";
CM_ SG_ 1294 CP_a085_dcPinTemp "Charge port controller: a085 dc pin temp";
CM_ SG_ 1294 CP_a086_dcPinTemp "Charge port controller: a086 dc pin temp";
CM_ SG_ 1294 CP_a089_gtwPlcSupportType "Charge port controller: a089 gtw plc support type";
CM_ SG_ 1294 CP_a089_plcModemPopulated "Charge port controller: a089 plc modem populated";
CM_ SG_ 1294 CP_a090_evseIsoStatus "Charge port controller: a090 evse iso status";
CM_ SG_ 1294 CP_a090_ccsDcState "Charge port controller: a090 ccs dc state";
CM_ SG_ 1294 CP_a091_fcType "Charge port controller: a091 fc type; raw 7 = signal not available (SNA)";
CM_ SG_ 1294 CP_a093_appLoadingNumRetries "Charge port controller: a093 app loading num retries";
CM_ SG_ 1294 CP_a093_interruptCauseRegError "Charge port controller: a093 interrupt cause reg error";
CM_ SG_ 1294 CP_a095_packCurrent "Charge port controller: a095 pack current";
CM_ SG_ 1294 CP_a095_dcOutputCurrent "Charge port controller: a095 dc output current";
CM_ SG_ 1294 CP_a095_ambientTemp "Charge port controller: a095 ambient temp";
CM_ SG_ 1294 CP_a095_fcType "Charge port controller: a095 fc type; raw 7 = signal not available (SNA)";
CM_ SG_ 1294 CP_a095_fcBrand "Charge port controller: a095 fc brand; raw 0 = signal not available (SNA)";
CM_ SG_ 1294 CP_a099_proximity "Charge port controller: a099 proximity; raw 0 = signal not available (SNA)";
CM_ SG_ 1294 CP_a099_pilot "Charge port controller: a099 pilot; raw 7 = signal not available (SNA)";
CM_ SG_ 1294 CP_a103_proximityV "Charge port controller: a103 proximity v";
CM_ SG_ 1294 CP_a109_thermistorId "Charge port controller: a109 thermistor id";
CM_ SG_ 1294 CP_a109_thermistorTemp "Charge port controller: a109 thermistor temp";
CM_ SG_ 1294 CP_a110_thermistorId "Charge port controller: a110 thermistor id";
CM_ SG_ 1294 CP_a110_thermistorTemp "Charge port controller: a110 thermistor temp";
CM_ SG_ 1294 CP_a110_thermalVelocity "Charge port controller: a110 thermal velocity; raw 511 = signal not available (SNA)";
CM_ SG_ 1294 CP_a111_heaterTemperature "Charge port controller: a111 heater temperature; raw 255 = signal not available (SNA)";
CM_ SG_ 1294 CP_a111_VC_tempAmbientFiltered "Charge port controller: a111 VC temp ambient filtered; raw 0 = signal not available (SNA)";
CM_ SG_ 1294 CP_a112_heaterTemperature "Charge port controller: a112 heater temperature; raw 255 = signal not available (SNA)";
CM_ SG_ 1294 CP_a113_heaterTemperature "Charge port controller: a113 heater temperature; raw 255 = signal not available (SNA)";
CM_ SG_ 1294 CP_a113_heaterCurrent "Charge port controller: a113 heater current";
CM_ SG_ 1294 CP_a116_hvCoverDetected "Charge port controller: a116 hv cover detected";
CM_ SG_ 1294 CP_a116_heaterDetected "Charge port controller: a116 heater detected";
CM_ SG_ 1294 CP_a116_temperatureSensorMismatc "Charge port controller: a116 temperature sensor mismatch";
CM_ SG_ 1294 CP_a116_thermistorsOpenCircuit "Charge port controller: a116 thermistors open circuit";
CM_ SG_ 1294 CP_a117_heaterTemperature "Charge port controller: a117 heater temperature; raw 255 = signal not available (SNA)";
CM_ SG_ 1294 CP_a117_averageError "Charge port controller: a117 average error; raw 255 = signal not available (SNA)";
CM_ SG_ 1294 CP_a120_oldProximtyV "Charge port controller: a120 old proximty v";
CM_ SG_ 1294 CP_a120_newProximtyV "Charge port controller: a120 new proximty v";
CM_ SG_ 1294 CP_a120_chargeVoltage "Charge port controller: a120 charge voltage";
CM_ SG_ 1294 CP_a120_chargeCurrent "Charge port controller: a120 charge current";
CM_ SG_ 1294 CP_a120_dcPinTemp "Charge port controller: a120 dc pin temp; raw 255 = signal not available (SNA)";
CM_ SG_ 1294 CP_a120_cableType "Charge port controller: a120 cable type; raw 5 = signal not available (SNA)";
CM_ SG_ 1294 CP_a121_CP_status_MIA "Charge port controller: a121 CP status MIA";
CM_ SG_ 1294 CP_a124_ivledState "Charge port controller: a124 ivled state";
CM_ SG_ 1294 CP_a124_ivledVoltage "Charge port controller: a124 ivled voltage";
CM_ SG_ 1294 CP_a125_okToUseHighPower "Charge port controller: a125 ok to use high power";
CM_ SG_ 1294 CP_a127_HVLINK_cpControl_MIA "Charge port controller: a127 HVLINK cp control MIA";
CM_ SG_ 1294 CP_a129_bldcDriverState "Charge port controller: a129 bldc driver state";
CM_ SG_ 1294 CP_a130_retryCount "Charge port controller: a130 retry count";
CM_ SG_ 1294 CP_a131_powerTransferProtocol "Charge port controller: a131 power transfer protocol";
CM_ SG_ 1294 CP_a135_sdpErr "Charge port controller: a135 sdp err";
CM_ SG_ 1294 CP_a135_pilotState "Charge port controller: a135 pilot state; raw 7 = signal not available (SNA)";
CM_ SG_ 1294 CP_a135_evseMeasuredAtten "Charge port controller: a135 evse measured atten";
CM_ SG_ 1294 CP_a138_FC_type "Charge port controller: a138 FC type; raw 7 = signal not available (SNA)";
CM_ SG_ 1294 CP_a138_latchState "Charge port controller: a138 latch state; raw 0 = signal not available (SNA)";
CM_ SG_ 1294 CP_a138_CP_proximity "Charge port controller: a138 CP proximity; raw 0 = signal not available (SNA)";
CM_ SG_ 1294 CP_a139_latchState "Charge port controller: a139 latch state; raw 0 = signal not available (SNA)";
CM_ SG_ 1294 CP_a139_CP_proximity "Charge port controller: a139 CP proximity; raw 0 = signal not available (SNA)";
CM_ SG_ 1294 CP_a140_latchState "Charge port controller: a140 latch state; raw 0 = signal not available (SNA)";
CM_ SG_ 1294 CP_a140_CP_proximity "Charge port controller: a140 CP proximity; raw 0 = signal not available (SNA)";
CM_ SG_ 1294 CP_a141_latchState "Charge port controller: a141 latch state; raw 0 = signal not available (SNA)";
CM_ SG_ 1294 CP_a141_CP_proximity "Charge port controller: a141 CP proximity; raw 0 = signal not available (SNA)";
CM_ SG_ 1294 CP_a142_cc1Voltage "Charge port controller: a142 cc1 voltage";
CM_ SG_ 1294 CP_a142_cc2Voltage "Charge port controller: a142 cc2 voltage";
CM_ SG_ 1294 CP_a143_versionDetected "Charge port controller: a143 version detected";
CM_ SG_ 1294 CP_a146_v2gMessage "Charge port controller: a146 v2g message";
CM_ SG_ 1294 CP_a151_pilotHighMin "Charge port controller: a151 pilot high min";
CM_ SG_ 1294 CP_a151_pilotHighMax "Charge port controller: a151 pilot high max";
CM_ SG_ 1294 CP_a151_pilotLowMin "Charge port controller: a151 pilot low min";
CM_ SG_ 1294 CP_a151_pilotLowMax "Charge port controller: a151 pilot low max";
CM_ SG_ 1294 CP_a152_swcanHighMismatchCount "Charge port controller: a152 swcan high mismatch count";
CM_ SG_ 1294 CP_a152_swcanLowMismatchCount "Charge port controller: a152 swcan low mismatch count";
CM_ SG_ 1294 CP_a152_maxPilotSwcanHigh "Charge port controller: a152 max pilot swcan high";
CM_ SG_ 1294 CP_a152_minPilotSwcanHigh "Charge port controller: a152 min pilot swcan high";
CM_ SG_ 1294 CP_a152_maxPilotSwcanLow "Charge port controller: a152 max pilot swcan low";
CM_ SG_ 1294 CP_a152_minPilotSwcanLow "Charge port controller: a152 min pilot swcan low";
CM_ SG_ 1294 CP_a153_acPinTempVelocity "Charge port controller: a153 ac pin temp velocity; raw 511 = signal not available (SNA)";
CM_ SG_ 1294 CP_a153_acPinTemp1 "Charge port controller: a153 ac pin temp1; raw 255 = signal not available (SNA)";
CM_ SG_ 1294 CP_a153_acPinTemp2 "Charge port controller: a153 ac pin temp2; raw 255 = signal not available (SNA)";
CM_ SG_ 1294 CP_a153_ambientTemp "Charge port controller: a153 ambient temp";
CM_ SG_ 1294 CP_a153_pcsLineChargeCurrent "Charge port controller: a153 pcs line charge current";
CM_ SG_ 1294 CP_a154_acPinTempVelocity "Charge port controller: a154 ac pin temp velocity; raw 511 = signal not available (SNA)";
CM_ SG_ 1294 CP_a154_acPinTemp1 "Charge port controller: a154 ac pin temp1; raw 255 = signal not available (SNA)";
CM_ SG_ 1294 CP_a154_acPinTemp2 "Charge port controller: a154 ac pin temp2; raw 255 = signal not available (SNA)";
CM_ SG_ 1294 CP_a154_ambientTemp "Charge port controller: a154 ambient temp";
CM_ SG_ 1294 CP_a154_pcsLineChargeCurrent "Charge port controller: a154 pcs line charge current";
CM_ SG_ 1294 CP_a155_hallSensorVoltage "Charge port controller: a155 hall sensor voltage";
CM_ SG_ 1294 CP_a161_pilotHighMin "Charge port controller: a161 pilot high min";
CM_ SG_ 1294 CP_a161_pilotHighMax "Charge port controller: a161 pilot high max";
CM_ SG_ 1294 CP_a161_pilotLowMin "Charge port controller: a161 pilot low min";
CM_ SG_ 1294 CP_a161_pilotLowMax "Charge port controller: a161 pilot low max";
CM_ SG_ 1294 CP_a162_swcanHighMismatchCount "Charge port controller: a162 swcan high mismatch count";
CM_ SG_ 1294 CP_a162_swcanLowMismatchCount "Charge port controller: a162 swcan low mismatch count";
CM_ SG_ 1294 CP_a162_maxPilotSwcanHigh "Charge port controller: a162 max pilot swcan high";
CM_ SG_ 1294 CP_a162_minPilotSwcanHigh "Charge port controller: a162 min pilot swcan high";
CM_ SG_ 1294 CP_a162_maxPilotSwcanLow "Charge port controller: a162 max pilot swcan low";
CM_ SG_ 1294 CP_a162_minPilotSwcanLow "Charge port controller: a162 min pilot swcan low";
CM_ SG_ 1294 CP_a163_cover1OpenCounts "Charge port controller: a163 cover1 open counts";
CM_ SG_ 1294 CP_a163_cover2OpenCounts "Charge port controller: a163 cover2 open counts";
CM_ SG_ 1294 CP_a163_cover1State "Charge port controller: a163 cover1 state; raw 4 = signal not available (SNA)";
CM_ SG_ 1294 CP_a163_cover2State "Charge port controller: a163 cover2 state; raw 4 = signal not available (SNA)";
CM_ SG_ 1294 CP_a164_VC_tempAmbientFiltered "Charge port controller: a164 VC temp ambient filtered; raw 0 = signal not available (SNA)";
CM_ SG_ 1294 CP_a164_minInternalPinTemp "Charge port controller: a164 min internal pin temp; raw 255 = signal not available (SNA)";
CM_ SG_ 1294 CP_a173_cover1OpenCounts "Charge port controller: a173 cover1 open counts";
CM_ SG_ 1294 CP_a173_cover2OpenCounts "Charge port controller: a173 cover2 open counts";
CM_ SG_ 1294 CP_a173_cover1State "Charge port controller: a173 cover1 state; raw 4 = signal not available (SNA)";
CM_ SG_ 1294 CP_a173_cover2State "Charge port controller: a173 cover2 state; raw 4 = signal not available (SNA)";
CM_ SG_ 1294 CP_a189_resistiveDividerVoltage "Charge port controller: a189 resistive divider voltage";
CM_ SG_ 1294 CP_a201_uhfDoorRequestCounts "Charge port controller: a201 uhf door request counts";
CM_ SG_ 1294 CP_a205_doorPotFiltered "Charge port controller: a205 door pot filtered";
CM_ SG_ 1294 CP_a205_doorPositionEstimationSu "Charge port controller: a205 door position estimation supported";
CM_ SG_ 1294 CP_a205_bldcMotorState "Charge port controller: a205 bldc motor state";
CM_ SG_ 1294 CP_a205_bldcTachIsInvalid "Charge port controller: a205 bldc tach is invalid";
CM_ SG_ 1294 CP_a205_presenceVoltage "Charge port controller: a205 presence voltage";
CM_ SG_ 1294 CP_a206_peToChassisVoltage "Charge port controller: a206 pe to chassis voltage";
CM_ SG_ 1294 CP_a210_PCSR_chgStatus_MIA "Charge port controller: a210 PCSR chg status MIA";
CM_ SG_ 1294 CP_a210_PCS2R_v2xInfo_MIA "Charge port controller: a210 PCS2 r v2x info MIA";
CM_ SG_ 1294 CP_a210_PCS2R_v2xInfo2_MIA "Charge port controller: a210 PCS2 r v2x info2 MIA";
CM_ SG_ 1294 CP_a211_PCSL_chgStatus_MIA "Charge port controller: a211 PCSL chg status MIA";
CM_ SG_ 1294 CP_a211_PCS2L_v2xInfo_MIA "Charge port controller: a211 PCS2 l v2x info MIA";
CM_ SG_ 1294 CP_a211_PCS2L_v2xInfo2_MIA "Charge port controller: a211 PCS2 l v2x info2 MIA";
CM_ SG_ 1294 CP_a220_ethPhyDriverFailure "Charge port controller: a220 eth phy driver failure";
CM_ SG_ 1294 CP_a220_sdpFailure "Charge port controller: a220 sdp failure";
CM_ SG_ 1294 CP_a220_evccServiceFailure "Charge port controller: a220 evcc service failure";
CM_ SG_ 1294 CP_a220_teslaV2gServiceFailure "Charge port controller: a220 tesla v2g service failure";
BA_DEF_ BO_ "GenMsgCycleTime" INT 0 3600000;
BA_DEF_ BO_ "GenMsgSendType" ENUM "Cyclic","NotUsed","NotUsed","NotUsed","NotUsed","NotUsed","NotUsed","IfActive","NoMsgSendType","NotUsed";
BA_DEF_ BO_ "VFrameFormat" ENUM "StandardCAN","ExtendedCAN","reserved","J1939PG","reserved","reserved","reserved","reserved","reserved","reserved","reserved","reserved","reserved","reserved","StandardCAN_FD","ExtendedCAN_FD";
BA_DEF_ BO_ "CANFD_BRS" ENUM "0","1";
BA_DEF_ SG_ "GenSigSNA" STRING;
BA_DEF_ SG_ "SystemSignalLongSymbol" STRING;
BA_DEF_ SG_ "Confidence" ENUM "validated","plausible","layout-only","contradicted";
BA_DEF_DEF_ "GenMsgCycleTime" 0;
BA_DEF_DEF_ "GenMsgSendType" "NoMsgSendType";
BA_DEF_DEF_ "VFrameFormat" "StandardCAN";
BA_DEF_DEF_ "CANFD_BRS" "1";
BA_DEF_DEF_ "GenSigSNA" "";
BA_DEF_DEF_ "SystemSignalLongSymbol" "";
BA_DEF_DEF_ "Confidence" "layout-only";
BA_ "GenMsgCycleTime" BO_ 914 1000;
BA_ "GenMsgSendType" BO_ 914 0;
BA_ "GenMsgCycleTime" BO_ 1810 1000;
BA_ "GenMsgSendType" BO_ 1810 0;
BA_ "GenMsgCycleTime" BO_ 594 100;
BA_ "GenMsgSendType" BO_ 594 0;
BA_ "GenMsgCycleTime" BO_ 674 1000;
BA_ "GenMsgSendType" BO_ 674 0;
BA_ "GenMsgCycleTime" BO_ 658 100;
BA_ "GenMsgSendType" BO_ 658 0;
BA_ "GenMsgCycleTime" BO_ 1170 1000;
BA_ "GenMsgSendType" BO_ 1170 0;
BA_ "GenMsgCycleTime" BO_ 530 100;
BA_ "GenMsgSendType" BO_ 530 0;
BA_ "GenMsgCycleTime" BO_ 786 1000;
BA_ "GenMsgSendType" BO_ 786 0;
BA_ "GenMsgCycleTime" BO_ 1071 1000;
BA_ "GenMsgSendType" BO_ 1071 0;
BA_ "GenMsgCycleTime" BO_ 754 100;
BA_ "GenMsgSendType" BO_ 754 0;
BA_ "GenMsgCycleTime" BO_ 810 5000;
BA_ "GenMsgSendType" BO_ 810 0;
BA_ "GenMsgCycleTime" BO_ 1132 1000;
BA_ "GenMsgSendType" BO_ 1132 0;
BA_ "GenMsgCycleTime" BO_ 796 100;
BA_ "GenMsgSendType" BO_ 796 0;
BA_ "GenMsgCycleTime" BO_ 797 100;
BA_ "GenMsgSendType" BO_ 797 0;
BA_ "GenMsgCycleTime" BO_ 812 1000;
BA_ "GenMsgSendType" BO_ 812 0;
BA_ "GenMsgCycleTime" BO_ 870 1000;
BA_ "GenMsgSendType" BO_ 870 0;
BA_ "GenMsgCycleTime" BO_ 679 100;
BA_ "GenMsgSendType" BO_ 679 0;
BA_ "GenMsgCycleTime" BO_ 867 1000;
BA_ "GenMsgSendType" BO_ 867 0;
BA_ "Confidence" SG_ 914 BMS_packConfigMultiplexer 1;
BA_ "Confidence" SG_ 914 BMS_reservedConfig_0 0;
BA_ "Confidence" SG_ 914 BMS_moduleType 0;
BA_ "Confidence" SG_ 914 BMS_thermalPackType 0;
BA_ "Confidence" SG_ 914 BMS_packMass 0;
BA_ "Confidence" SG_ 914 BMS_platformMaxBusVoltage 0;
BA_ "Confidence" SG_ 914 BMS_standbySupplyContinuousPower 0;
BA_ "SystemSignalLongSymbol" SG_ 914 BMS_standbySupplyContinuousPower "BMS_standbySupplyContinuousPowerLimit";
BA_ "Confidence" SG_ 914 BMS_beginningOfLifePackEnergy 0;
BA_ "GenSigSNA" SG_ 914 BMS_beginningOfLifePackEnergy "1023";
BA_ "Confidence" SG_ 1810 BMS_packTemperatureMultiplexer 1;
BA_ "Confidence" SG_ 1810 BMS_packTemperatureCounter 0;
BA_ "Confidence" SG_ 1810 BMS_packTemperatureStatus1 0;
BA_ "Confidence" SG_ 1810 BMS_packTemperatureStatus2 0;
BA_ "Confidence" SG_ 1810 BMS_packTemperatureStatus3 0;
BA_ "Confidence" SG_ 1810 BMS_packTemperature1 0;
BA_ "Confidence" SG_ 1810 BMS_packTemperature2 0;
BA_ "Confidence" SG_ 1810 BMS_packTemperature3 0;
BA_ "Confidence" SG_ 1810 BMS_packTemperatureStatus4 0;
BA_ "Confidence" SG_ 1810 BMS_packTemperatureStatus5 0;
BA_ "Confidence" SG_ 1810 BMS_packTemperatureStatus6 0;
BA_ "Confidence" SG_ 1810 BMS_packTemperature4 0;
BA_ "Confidence" SG_ 1810 BMS_packTemperature5 0;
BA_ "Confidence" SG_ 1810 BMS_packTemperature6 0;
BA_ "Confidence" SG_ 1810 BMS_packTemperatureStatus7 0;
BA_ "Confidence" SG_ 1810 BMS_packTemperatureStatus8 0;
BA_ "Confidence" SG_ 1810 BMS_packTemperatureStatus9 0;
BA_ "Confidence" SG_ 1810 BMS_packTemperature7 0;
BA_ "Confidence" SG_ 1810 BMS_packTemperature8 0;
BA_ "Confidence" SG_ 1810 BMS_packTemperature9 0;
BA_ "Confidence" SG_ 1810 BMS_packTemperatureStatus10 0;
BA_ "Confidence" SG_ 1810 BMS_packTemperatureStatus11 0;
BA_ "Confidence" SG_ 1810 BMS_packTemperatureStatus12 0;
BA_ "Confidence" SG_ 1810 BMS_packTemperature10 0;
BA_ "Confidence" SG_ 1810 BMS_packTemperature11 0;
BA_ "Confidence" SG_ 1810 BMS_packTemperature12 0;
BA_ "Confidence" SG_ 1810 BMS_packTemperatureStatus13 0;
BA_ "Confidence" SG_ 1810 BMS_packTemperatureStatus14 0;
BA_ "Confidence" SG_ 1810 BMS_packTemperatureStatus15 0;
BA_ "Confidence" SG_ 1810 BMS_packTemperature13 0;
BA_ "Confidence" SG_ 1810 BMS_packTemperature14 0;
BA_ "Confidence" SG_ 1810 BMS_packTemperature15 0;
BA_ "Confidence" SG_ 1810 BMS_packTemperatureStatus16 0;
BA_ "Confidence" SG_ 1810 BMS_packTemperatureStatus17 0;
BA_ "Confidence" SG_ 1810 BMS_packTemperatureStatus18 0;
BA_ "Confidence" SG_ 1810 BMS_packTemperature16 0;
BA_ "Confidence" SG_ 1810 BMS_packTemperature17 0;
BA_ "Confidence" SG_ 1810 BMS_packTemperature18 0;
BA_ "Confidence" SG_ 594 BMS_maxRegenPower 0;
BA_ "Confidence" SG_ 594 BMS_maxDischargePower 0;
BA_ "Confidence" SG_ 594 BMS_maxStationaryHeatPower 0;
BA_ "Confidence" SG_ 594 BMS_powerLimitsState 0;
BA_ "Confidence" SG_ 594 BMS_totalHvPowerBudget 0;
BA_ "Confidence" SG_ 594 BMS_notEnoughPowerForHeatPump 0;
BA_ "Confidence" SG_ 674 BMS_acRippleCurrentAmplitudeLimi 0;
BA_ "SystemSignalLongSymbol" SG_ 674 BMS_acRippleCurrentAmplitudeLimi "BMS_acRippleCurrentAmplitudeLimit";
BA_ "Confidence" SG_ 674 BMS_acRippleMaxVoltageLimit 0;
BA_ "Confidence" SG_ 674 BMS_acRippleMinVoltageLimit 0;
BA_ "Confidence" SG_ 674 BMS_acRippleFrequencyRequest 0;
BA_ "GenSigSNA" SG_ 674 BMS_acRippleFrequencyRequest "1023";
BA_ "Confidence" SG_ 674 BMS_acRippleCurrentAmplitudeRequ 0;
BA_ "SystemSignalLongSymbol" SG_ 674 BMS_acRippleCurrentAmplitudeRequ "BMS_acRippleCurrentAmplitudeRequest";
BA_ "Confidence" SG_ 674 BMS_acRippleRequest 0;
BA_ "Confidence" SG_ 1834 BMS_serialNumberMultiplexer 1;
BA_ "Confidence" SG_ 1834 BMS_packSerialNumberByte01 0;
BA_ "Confidence" SG_ 1834 BMS_packSerialNumberByte02 0;
BA_ "Confidence" SG_ 1834 BMS_packSerialNumberByte03 0;
BA_ "Confidence" SG_ 1834 BMS_packSerialNumberByte04 0;
BA_ "Confidence" SG_ 1834 BMS_packSerialNumberByte05 0;
BA_ "Confidence" SG_ 1834 BMS_packSerialNumberByte06 0;
BA_ "Confidence" SG_ 1834 BMS_packSerialNumberByte07 0;
BA_ "Confidence" SG_ 1834 BMS_packSerialNumberByte08 0;
BA_ "Confidence" SG_ 1834 BMS_packSerialNumberByte09 0;
BA_ "Confidence" SG_ 1834 BMS_packSerialNumberByte10 0;
BA_ "Confidence" SG_ 1834 BMS_packSerialNumberByte11 0;
BA_ "Confidence" SG_ 1834 BMS_packSerialNumberByte12 0;
BA_ "Confidence" SG_ 1834 BMS_packSerialNumberByte13 0;
BA_ "Confidence" SG_ 1834 BMS_packSerialNumberByte14 0;
BA_ "Confidence" SG_ 1834 BMS_packSerialBirthDateBinned 1;
BA_ "Confidence" SG_ 658 BMS_socMin 0;
BA_ "Confidence" SG_ 658 BMS_socUI 0;
BA_ "Confidence" SG_ 658 BMS_socMax 0;
BA_ "Confidence" SG_ 658 BMS_socAvg 0;
BA_ "Confidence" SG_ 658 BMS_enoughEnergyForConvenienceFe 0;
BA_ "SystemSignalLongSymbol" SG_ 658 BMS_enoughEnergyForConvenienceFe "BMS_enoughEnergyForConvenienceFeatures";
BA_ "Confidence" SG_ 658 BMS_instantChargePowerCapability 0;
BA_ "GenSigSNA" SG_ 658 BMS_instantChargePowerCapability "65535";
BA_ "Confidence" SG_ 1170 BMS_sohEnergyPercent 0;
BA_ "GenSigSNA" SG_ 1170 BMS_sohEnergyPercent "1023";
BA_ "Confidence" SG_ 1170 BMS_userFacingSohTestState 0;
BA_ "Confidence" SG_ 1170 BMS_userFacingSohTestEndMode 0;
BA_ "Confidence" SG_ 1170 BMS_timeSinceSohUpdate 0;
BA_ "GenSigSNA" SG_ 1170 BMS_timeSinceSohUpdate "4095";
BA_ "Confidence" SG_ 1170 BMS_sohTestCycleFlag 0;
BA_ "Confidence" SG_ 1170 BMS_sohTestIsBlocked 0;
BA_ "Confidence" SG_ 1170 BMS_calibratedSohAvailable 0;
BA_ "Confidence" SG_ 1170 BMS_requiredEvsePowerForSoh 0;
BA_ "GenSigSNA" SG_ 1170 BMS_requiredEvsePowerForSoh "255";
BA_ "Confidence" SG_ 1170 BMS_distanceSinceSohUpdate 0;
BA_ "GenSigSNA" SG_ 1170 BMS_distanceSinceSohUpdate "65535";
BA_ "Confidence" SG_ 530 BMS_hvacPowerRequest 0;
BA_ "Confidence" SG_ 530 BMS_notEnoughPowerForDrive 0;
BA_ "Confidence" SG_ 530 BMS_notEnoughPowerForSupport 0;
BA_ "Confidence" SG_ 530 BMS_preconditionAllowed 0;
BA_ "Confidence" SG_ 530 BMS_updateAllowed 0;
BA_ "Confidence" SG_ 530 BMS_cpMiaOnHvs 0;
BA_ "Confidence" SG_ 530 BMS_pcsPwmEnabled 0;
BA_ "Confidence" SG_ 530 BMS_contactorState 0;
BA_ "GenSigSNA" SG_ 530 BMS_contactorState "0";
BA_ "Confidence" SG_ 530 BMS_userChargeStatus 0;
BA_ "Confidence" SG_ 530 BMS_batteryInputPower 0;
BA_ "GenSigSNA" SG_ 530 BMS_batteryInputPower "65535";
BA_ "Confidence" SG_ 530 BMS_chargeRequest 0;
BA_ "Confidence" SG_ 530 BMS_state 0;
BA_ "GenSigSNA" SG_ 530 BMS_state "9";
BA_ "Confidence" SG_ 530 BMS_diLimpRequest 0;
BA_ "Confidence" SG_ 530 BMS_okToShipByAir 0;
BA_ "Confidence" SG_ 530 BMS_okToShipByLand 0;
BA_ "Confidence" SG_ 530 BMS_chgPowerAvailable 0;
BA_ "GenSigSNA" SG_ 530 BMS_chgPowerAvailable "4095";
BA_ "Confidence" SG_ 530 BMS_acManagerState 0;
BA_ "Confidence" SG_ 530 BMS_conditioningRequest 0;
BA_ "Confidence" SG_ 530 BMS_smStateRequest 0;
BA_ "GenSigSNA" SG_ 530 BMS_smStateRequest "9";
BA_ "Confidence" SG_ 530 BMS_hvState 0;
BA_ "Confidence" SG_ 786 BMS_thermalStatusMultiplexer 1;
BA_ "Confidence" SG_ 786 BMS_inletActiveCoolTargetT 0;
BA_ "Confidence" SG_ 786 BMS_inletPassiveTargetT 0;
BA_ "Confidence" SG_ 786 BMS_inletActiveHeatTargetT 0;
BA_ "Confidence" SG_ 786 BMS_requestDischarge 0;
BA_ "Confidence" SG_ 786 BMS_activeHeatingWorthwhile 0;
BA_ "Confidence" SG_ 786 BMS_pcsNoFlowRequest 0;
BA_ "Confidence" SG_ 786 BMS_minPackTemperature 0;
BA_ "Confidence" SG_ 786 BMS_noFlowRequest 0;
BA_ "Confidence" SG_ 786 BMS_maxPackTemperature 0;
BA_ "Confidence" SG_ 786 BMS_flowRequest 0;
BA_ "Confidence" SG_ 786 BMS_coldStagnationLimit 0;
BA_ "Confidence" SG_ 786 BMS_hotStagnationLimit 0;
BA_ "Confidence" SG_ 786 BMS_hotCellTempLimit 0;
BA_ "Confidence" SG_ 786 BMS_i2tDeratingEnabled 0;
BA_ "Confidence" SG_ 786 BMS_activeCoolCellReferenceT 0;
BA_ "Confidence" SG_ 786 BMS_activeHeatCellTargetT 0;
BA_ "Confidence" SG_ 786 BMS_powerDissipation 0;
BA_ "Confidence" SG_ 1554 BMS_udsResponseData 1;
BA_ "Confidence" SG_ 1071 BMS_v2xSoe 0;
BA_ "GenSigSNA" SG_ 1071 BMS_v2xSoe "65535";
BA_ "Confidence" SG_ 1071 BMS_v2xFullEnergy 0;
BA_ "GenSigSNA" SG_ 1071 BMS_v2xFullEnergy "4095";
BA_ "Confidence" SG_ 1071 BMS_v2xPackPower 0;
BA_ "GenSigSNA" SG_ 1071 BMS_v2xPackPower "511";
BA_ "Confidence" SG_ 1071 BMS_acDischargeBlockedReason 0;
BA_ "Confidence" SG_ 1071 BMS_backupTimeRemaining 0;
BA_ "GenSigSNA" SG_ 1071 BMS_backupTimeRemaining "255";
BA_ "Confidence" SG_ 754 BMS_nmGoingToSleep 0;
BA_ "Confidence" SG_ 754 BMS_nmWakeUpBus 0;
BA_ "Confidence" SG_ 754 BMS_hvsBusAsleep 0;
BA_ "Confidence" SG_ 754 BMS_nmKeepAwakeReason 0;
BA_ "GenSigSNA" SG_ 754 BMS_nmKeepAwakeReason "0";
BA_ "Confidence" SG_ 754 BMS_nmWakeUpReason 0;
BA_ "Confidence" SG_ 810 BMS_thermalEventSuspected 0;
BA_ "Confidence" SG_ 810 BMS_vehicleNotificationsCounter 0;
BA_ "Confidence" SG_ 810 BMS_isolationResistance 0;
BA_ "GenSigSNA" SG_ 810 BMS_isolationResistance "1023";
BA_ "Confidence" SG_ 810 BMS_chgTimeToFull 0;
BA_ "GenSigSNA" SG_ 810 BMS_chgTimeToFull "4095";
BA_ "Confidence" SG_ 810 BMS_vehicleNotificationsChecksum 0;
BA_ "Confidence" SG_ 1116 CC_alertID 1;
BA_ "Confidence" SG_ 1116 CC_alertType 1;
BA_ "Confidence" SG_ 1116 CC_a001_groundResistance 1;
BA_ "GenSigSNA" SG_ 1116 CC_a001_groundResistance "4095";
BA_ "Confidence" SG_ 1116 CC_a003_gfciRmsCurrent 1;
BA_ "Confidence" SG_ 1116 CC_a003_gfciRmsCurrentAvg 1;
BA_ "Confidence" SG_ 1116 CC_a003_dcGfciCurrent 1;
BA_ "Confidence" SG_ 1116 CC_a003_gfciFaultReason 1;
BA_ "GenSigSNA" SG_ 1116 CC_a003_gfciFaultReason "0";
BA_ "Confidence" SG_ 1116 CC_a004_gfciErrorReason 1;
BA_ "GenSigSNA" SG_ 1116 CC_a004_gfciErrorReason "0";
BA_ "Confidence" SG_ 1116 CC_a004_gfciSelfTestDuty 1;
BA_ "Confidence" SG_ 1116 CC_a004_gfciSelfTestCurrent 1;
BA_ "Confidence" SG_ 1116 CC_a006_line1Current 1;
BA_ "Confidence" SG_ 1116 CC_a006_line2Current 1;
BA_ "Confidence" SG_ 1116 CC_a006_line3Current 1;
BA_ "Confidence" SG_ 1116 CC_a007_inputVoltage 1;
BA_ "Confidence" SG_ 1116 CC_a007_inputLineVoltage 1;
BA_ "Confidence" SG_ 1116 CC_a007_inputNeutralVoltage 1;
BA_ "Confidence" SG_ 1116 CC_a008_inputVoltage 1;
BA_ "Confidence" SG_ 1116 CC_a008_inputLineVoltage 1;
BA_ "Confidence" SG_ 1116 CC_a008_inputNeutralVoltage 1;
BA_ "Confidence" SG_ 1116 CC_a010_line1Voltage 1;
BA_ "Confidence" SG_ 1116 CC_a010_line2Voltage 1;
BA_ "Confidence" SG_ 1116 CC_a010_line3Voltage 1;
BA_ "Confidence" SG_ 1116 CC_a011_pcbaTemp 1;
BA_ "Confidence" SG_ 1116 CC_a012_inputThermopile 1;
BA_ "Confidence" SG_ 1116 CC_a012_inputThermopileDvdt 1;
BA_ "Confidence" SG_ 1116 CC_a013_handleTemp 1;
BA_ "Confidence" SG_ 1116 CC_a014_failureCause 1;
BA_ "Confidence" SG_ 1116 CC_a015_pilotHighVolage 1;
BA_ "Confidence" SG_ 1116 CC_a027_handleTemperature 1;
BA_ "Confidence" SG_ 1116 CC_a027_handleTempFaultReason 1;
BA_ "Confidence" SG_ 1116 CC_a033_nominalVoltage 1;
BA_ "Confidence" SG_ 1116 CC_a033_measuredVoltage 1;
BA_ "Confidence" SG_ 1116 CC_a036_line1Voltage 1;
BA_ "Confidence" SG_ 1116 CC_a036_line2Voltage 1;
BA_ "Confidence" SG_ 1116 CC_a036_line3Voltage 1;
BA_ "Confidence" SG_ 1116 CC_a039_intModuleTemperature 1;
BA_ "Confidence" SG_ 1116 CC_a040_handleTemperature 1;
BA_ "Confidence" SG_ 1116 CC_a041_inputThermopile 1;
BA_ "Confidence" SG_ 1116 CC_a041_inputThermopileDvdt 1;
BA_ "Confidence" SG_ 1116 CC_a042_pcbaTemperature 1;
BA_ "Confidence" SG_ 1116 CC_a044_relayCoilVoltage 1;
BA_ "Confidence" SG_ 1116 CC_a044_pcbaTemperature 1;
BA_ "SystemSignalLongSymbol" SG_ 1132 CC_a037_internalModuleWatchdogEx "CC_a037_internalModuleWatchdogExpired";
BA_ "SystemSignalLongSymbol" SG_ 1132 CC_a044_relayCoilVoltageRational "CC_a044_relayCoilVoltageRationality";
BA_ "Confidence" SG_ 796 CC_currentLimit 0;
BA_ "GenSigSNA" SG_ 796 CC_currentLimit "255";
BA_ "Confidence" SG_ 796 CC_pilotState 0;
BA_ "GenSigSNA" SG_ 796 CC_pilotState "3";
BA_ "Confidence" SG_ 796 CC_numPhases 0;
BA_ "GenSigSNA" SG_ 796 CC_numPhases "0";
BA_ "Confidence" SG_ 796 CC_line1Voltage 0;
BA_ "GenSigSNA" SG_ 796 CC_line1Voltage "511";
BA_ "Confidence" SG_ 796 CC_gridGrounding 0;
BA_ "GenSigSNA" SG_ 796 CC_gridGrounding "2";
BA_ "Confidence" SG_ 796 CC_deltaTransformer 0;
BA_ "Confidence" SG_ 796 CC_numVehCharging 0;
BA_ "Confidence" SG_ 796 CC_line2Voltage 0;
BA_ "GenSigSNA" SG_ 796 CC_line2Voltage "511";
BA_ "Confidence" SG_ 796 CC_line3Voltage 0;
BA_ "GenSigSNA" SG_ 796 CC_line3Voltage "511";
BA_ "Confidence" SG_ 796 CC_groundResistance 0;
BA_ "GenSigSNA" SG_ 796 CC_groundResistance "4095";
BA_ "Confidence" SG_ 797 CC_chgStatus2Index 1;
BA_ "Confidence" SG_ 797 CC_buttonState 0;
BA_ "Confidence" SG_ 797 EVSE_v2xSupport 0;
BA_ "Confidence" SG_ 797 EVSE_v2xHandshakeStart 0;
BA_ "Confidence" SG_ 797 EVSE_v2xSessionType 0;
BA_ "GenSigSNA" SG_ 797 EVSE_v2xSessionType "0";
BA_ "Confidence" SG_ 812 CC_logIndex 1;
BA_ "Confidence" SG_ 812 CC_activeConnectorID 0;
BA_ "Confidence" SG_ 812 CC_temperature1 0;
BA_ "Confidence" SG_ 812 CC_temperature2 0;
BA_ "Confidence" SG_ 812 CC_temperature3 0;
BA_ "Confidence" SG_ 812 CC_contactor1Closed 0;
BA_ "Confidence" SG_ 812 CC_contactor2Closed 0;
BA_ "Confidence" SG_ 812 CC_temperature4 0;
BA_ "Confidence" SG_ 812 CC_conn1Current 0;
BA_ "GenSigSNA" SG_ 812 CC_conn1Current "255";
BA_ "Confidence" SG_ 812 CC_conn2Current 0;
BA_ "GenSigSNA" SG_ 812 CC_conn2Current "255";
BA_ "Confidence" SG_ 812 CC_conn3Current 0;
BA_ "GenSigSNA" SG_ 812 CC_conn3Current "255";
BA_ "Confidence" SG_ 812 CC_conn4Current 0;
BA_ "GenSigSNA" SG_ 812 CC_conn4Current "255";
BA_ "Confidence" SG_ 812 CC_lifetimei2t 0;
BA_ "Confidence" SG_ 812 CC_lifetimeCtrCycles 0;
BA_ "Confidence" SG_ 812 CC_lifetimeCtrCyclesLoaded 0;
BA_ "Confidence" SG_ 812 CC_lifetimeAlertCount 0;
BA_ "Confidence" SG_ 812 CC_lifetimeThermalFoldbacks 0;
BA_ "Confidence" SG_ 812 CC_lifetimeAvgStartupTemp 0;
BA_ "Confidence" SG_ 870 CMPD_infoIndex 1;
BA_ "Confidence" SG_ 870 CMPD_infoBuildType 0;
BA_ "Confidence" SG_ 870 CMPD_infoBuildConfigId 0;
BA_ "Confidence" SG_ 870 CMPD_infoHardwareId 0;
BA_ "Confidence" SG_ 870 CMPD_infoComponentId 0;
BA_ "Confidence" SG_ 870 CMPD_infoPcbaId 0;
BA_ "Confidence" SG_ 870 CMPD_infoAssemblyId 0;
BA_ "GenSigSNA" SG_ 870 CMPD_infoAssemblyId "255";
BA_ "Confidence" SG_ 870 CMPD_infoUsageId 0;
BA_ "Confidence" SG_ 870 CMPD_infoSubUsageId 0;
BA_ "Confidence" SG_ 679 CMPD_speedRPM 0;
BA_ "Confidence" SG_ 679 CMPD_speedDuty 0;
BA_ "Confidence" SG_ 679 CMPD_inputHVPower 0;
BA_ "Confidence" SG_ 679 CMPD_inputHVCurrent 0;
BA_ "Confidence" SG_ 679 CMPD_inputHVVoltage 0;
BA_ "Confidence" SG_ 679 CMPD_2ShuntModeActive 0;
BA_ "Confidence" SG_ 679 CMPD_powerLimitActive 0;
BA_ "Confidence" SG_ 679 CMPD_state 0;
BA_ "GenSigSNA" SG_ 679 CMPD_state "15";
BA_ "Confidence" SG_ 679 CMPD_wasteHeatState 0;
BA_ "Confidence" SG_ 679 CMPD_powerLimitTooLowToStart 0;
BA_ "Confidence" SG_ 679 CMPD_ready 0;
BA_ "Confidence" SG_ 1559 CMPD_udsResponseData 1;
BA_ "Confidence" SG_ 867 CMP_infoIndex 1;
BA_ "Confidence" SG_ 867 CMP_infoBuildType 0;
BA_ "Confidence" SG_ 867 CMP_infoBuildConfigId 0;
BA_ "Confidence" SG_ 867 CMP_infoHardwareId 0;
BA_ "Confidence" SG_ 867 CMP_infoComponentId 0;
BA_ "Confidence" SG_ 867 CMP_infoPcbaId 0;
BA_ "Confidence" SG_ 867 CMP_infoAssemblyId 0;
BA_ "GenSigSNA" SG_ 867 CMP_infoAssemblyId "255";
BA_ "Confidence" SG_ 867 CMP_infoUsageId 0;
BA_ "Confidence" SG_ 867 CMP_infoSubUsageId 0;
BA_ "Confidence" SG_ 867 CMP_infoPlatformType 0;
BA_ "Confidence" SG_ 867 CMP_infoAppCrc 0;
BA_ "Confidence" SG_ 867 CMP_infoBootUdsProtoVersion 0;
BA_ "Confidence" SG_ 867 CMP_infoBootCrc 0;
BA_ "Confidence" SG_ 1555 CMP_udsResponseData 1;
BA_ "Confidence" SG_ 1294 CP_alertID 1;
BA_ "Confidence" SG_ 1294 CP_alertType 1;
BA_ "Confidence" SG_ 1294 CP_a004_proximityV 1;
BA_ "Confidence" SG_ 1294 CP_a004_cc1Voltage 1;
BA_ "Confidence" SG_ 1294 CP_a004_cc2Voltage 1;
BA_ "Confidence" SG_ 1294 CP_a005_cc1Voltage 1;
BA_ "Confidence" SG_ 1294 CP_a005_cc2Voltage 1;
BA_ "Confidence" SG_ 1294 CP_a005_gbdcState 1;
BA_ "Confidence" SG_ 1294 CP_a005_packCurrent 1;
BA_ "Confidence" SG_ 1294 CP_a005_evseCurrent 1;
BA_ "SystemSignalLongSymbol" SG_ 1294 CP_a006_BMS_cpFaultLineStatus_MI "CP_a006_BMS_cpFaultLineStatus_MIA";
BA_ "Confidence" SG_ 1294 CP_a008_stackUsed 1;
BA_ "Confidence" SG_ 1294 CP_a009_cover1OpenCounts 1;
BA_ "Confidence" SG_ 1294 CP_a009_cover2OpenCounts 1;
BA_ "Confidence" SG_ 1294 CP_a009_cover1State 1;
BA_ "GenSigSNA" SG_ 1294 CP_a009_cover1State "4";
BA_ "Confidence" SG_ 1294 CP_a009_cover2State 1;
BA_ "GenSigSNA" SG_ 1294 CP_a009_cover2State "4";
BA_ "Confidence" SG_ 1294 CP_a010_pilotHigh 1;
BA_ "Confidence" SG_ 1294 CP_a010_pilotLow 1;
BA_ "Confidence" SG_ 1294 CP_a011_eepromErrorType 1;
BA_ "Confidence" SG_ 1294 CP_a015_apsVoltageOV 1;
BA_ "Confidence" SG_ 1294 CP_a016_apsVoltageUV 1;
BA_ "Confidence" SG_ 1294 CP_a017_5V_VoltageOV 1;
BA_ "Confidence" SG_ 1294 CP_a018_5V_VoltageUV 1;
BA_ "Confidence" SG_ 1294 CP_a023_stopChargeReason 1;
BA_ "Confidence" SG_ 1294 CP_a023_failureReason 1;
BA_ "Confidence" SG_ 1294 CP_a029_CP_pilot 1;
BA_ "GenSigSNA" SG_ 1294 CP_a029_CP_pilot "7";
BA_ "Confidence" SG_ 1294 CP_a029_CP_proximity 1;
BA_ "GenSigSNA" SG_ 1294 CP_a029_CP_proximity "0";
BA_ "Confidence" SG_ 1294 CP_a031_apsVoltage 1;
BA_ "Confidence" SG_ 1294 CP_a031_doorCountsFiltered 1;
BA_ "Confidence" SG_ 1294 CP_a031_inductiveSensorFiltered 1;
BA_ "Confidence" SG_ 1294 CP_a031_hallSensorFiltered 1;
BA_ "Confidence" SG_ 1294 CP_a032_apsVoltage 1;
BA_ "Confidence" SG_ 1294 CP_a032_doorCountsFiltered 1;
BA_ "Confidence" SG_ 1294 CP_a032_inductiveSensorFiltered 1;
BA_ "Confidence" SG_ 1294 CP_a032_hallSensorFiltered 1;
BA_ "Confidence" SG_ 1294 CP_a035_latchState 1;
BA_ "GenSigSNA" SG_ 1294 CP_a035_latchState "0";
BA_ "Confidence" SG_ 1294 CP_a035_latchOffset 1;
BA_ "Confidence" SG_ 1294 CP_a035_inletID 1;
BA_ "Confidence" SG_ 1294 CP_a036_latchCountsFiltered 1;
BA_ "Confidence" SG_ 1294 CP_a036_latchState 1;
BA_ "GenSigSNA" SG_ 1294 CP_a036_latchState "0";
BA_ "Confidence" SG_ 1294 CP_a036_CP_apsVoltage 1;
BA_ "Confidence" SG_ 1294 CP_a036_inletID 1;
BA_ "Confidence" SG_ 1294 CP_a037_latchCountsFiltered 1;
BA_ "Confidence" SG_ 1294 CP_a037_latchState 1;
BA_ "GenSigSNA" SG_ 1294 CP_a037_latchState "0";
BA_ "Confidence" SG_ 1294 CP_a037_CP_apsVoltage 1;
BA_ "Confidence" SG_ 1294 CP_a037_inletID 1;
BA_ "Confidence" SG_ 1294 CP_a038_latchCountsFiltered 1;
BA_ "Confidence" SG_ 1294 CP_a038_latchState 1;
BA_ "GenSigSNA" SG_ 1294 CP_a038_latchState "0";
BA_ "Confidence" SG_ 1294 CP_a038_CP_apsVoltage 1;
BA_ "Confidence" SG_ 1294 CP_a038_inletID 1;
BA_ "Confidence" SG_ 1294 CP_a041_doorCounts 1;
BA_ "Confidence" SG_ 1294 CP_a041_inductiveSensorFiltered 1;
BA_ "Confidence" SG_ 1294 CP_a041_hallSensorFiltered 1;
BA_ "Confidence" SG_ 1294 CP_a042_doorCounts 1;
BA_ "Confidence" SG_ 1294 CP_a042_inductiveSensorFiltered 1;
BA_ "Confidence" SG_ 1294 CP_a042_hallSensorFiltered 1;
BA_ "Confidence" SG_ 1294 CP_a043_doorPotFiltered 1;
BA_ "Confidence" SG_ 1294 CP_a043_doorVelocity 1;
BA_ "Confidence" SG_ 1294 CP_a043_idleDoorPot 1;
BA_ "Confidence" SG_ 1294 CP_a049_proximity 1;
BA_ "GenSigSNA" SG_ 1294 CP_a049_proximity "0";
BA_ "Confidence" SG_ 1294 CP_a050_maxLatchCurrentSeen 1;
BA_ "Confidence" SG_ 1294 CP_a050_minLatchCurrentBelowThre 1;
BA_ "SystemSignalLongSymbol" SG_ 1294 CP_a050_minLatchCurrentBelowThre "CP_a050_minLatchCurrentBelowThreshold";
BA_ "Confidence" SG_ 1294 CP_a051_doorCountsFiltered 1;
BA_ "Confidence" SG_ 1294 CP_a054_latchCountsFiltered 1;
BA_ "Confidence" SG_ 1294 CP_a054_latchState 1;
BA_ "GenSigSNA" SG_ 1294 CP_a054_latchState "0";
BA_ "Confidence" SG_ 1294 CP_a054_CP_apsVoltage 1;
BA_ "Confidence" SG_ 1294 CP_a054_CP_proximity 1;
BA_ "GenSigSNA" SG_ 1294 CP_a054_CP_proximity "0";
BA_ "Confidence" SG_ 1294 CP_a054_inletID 1;
BA_ "Confidence" SG_ 1294 CP_a056_latchState 1;
BA_ "GenSigSNA" SG_ 1294 CP_a056_latchState "0";
BA_ "Confidence" SG_ 1294 CP_a056_CP_proximity 1;
BA_ "GenSigSNA" SG_ 1294 CP_a056_CP_proximity "0";
BA_ "Confidence" SG_ 1294 CP_a056_packCurrent 1;
BA_ "Confidence" SG_ 1294 CP_a058_CP_pilot 1;
BA_ "GenSigSNA" SG_ 1294 CP_a058_CP_pilot "7";
BA_ "Confidence" SG_ 1294 CP_a058_CC_pilot 1;
BA_ "GenSigSNA" SG_ 1294 CP_a058_CC_pilot "3";
BA_ "Confidence" SG_ 1294 CP_a058_FC_status 1;
BA_ "GenSigSNA" SG_ 1294 CP_a058_FC_status "0";
BA_ "Confidence" SG_ 1294 CP_a058_latchState 1;
BA_ "GenSigSNA" SG_ 1294 CP_a058_latchState "0";
BA_ "Confidence" SG_ 1294 CP_a058_CP_proximity 1;
BA_ "GenSigSNA" SG_ 1294 CP_a058_CP_proximity "0";
BA_ "Confidence" SG_ 1294 CP_a061_controlState 1;
BA_ "Confidence" SG_ 1294 CP_a061_lastControlState 1;
BA_ "Confidence" SG_ 1294 CP_a062_FC_status 1;
BA_ "GenSigSNA" SG_ 1294 CP_a062_FC_status "0";
BA_ "Confidence" SG_ 1294 CP_a062_FC_type 1;
BA_ "GenSigSNA" SG_ 1294 CP_a062_FC_type "7";
BA_ "Confidence" SG_ 1294 CP_a063_FC_status 1;
BA_ "GenSigSNA" SG_ 1294 CP_a063_FC_status "0";
BA_ "Confidence" SG_ 1294 CP_a063_FC_type 1;
BA_ "GenSigSNA" SG_ 1294 CP_a063_FC_type "7";
BA_ "Confidence" SG_ 1294 CP_a066_pilotHigh 1;
BA_ "Confidence" SG_ 1294 CP_a066_pilotLow 1;
BA_ "Confidence" SG_ 1294 CP_a066_proximity 1;
BA_ "GenSigSNA" SG_ 1294 CP_a066_proximity "0";
BA_ "Confidence" SG_ 1294 CP_a067_cc1Voltage 1;
BA_ "Confidence" SG_ 1294 CP_a067_cc2Voltage 1;
BA_ "Confidence" SG_ 1294 CP_a068_doorCountsFiltered 1;
BA_ "Confidence" SG_ 1294 CP_a068_inductiveSensorFiltered 1;
BA_ "Confidence" SG_ 1294 CP_a068_hallSensorFiltered 1;
BA_ "Confidence" SG_ 1294 CP_a071_expectedMessage 1;
BA_ "Confidence" SG_ 1294 CP_a072_currentMessage 1;
BA_ "Confidence" SG_ 1294 CP_a074_slacState 1;
BA_ "Confidence" SG_ 1294 CP_a074_slacErrorCode 1;
BA_ "Confidence" SG_ 1294 CP_a075_evccState 1;
BA_ "Confidence" SG_ 1294 CP_a075_currentMessage 1;
BA_ "Confidence" SG_ 1294 CP_a075_initFailureType 1;
BA_ "Confidence" SG_ 1294 CP_a075_evccSocketErrTx 1;
BA_ "Confidence" SG_ 1294 CP_a075_evccSocketErrRx 1;
BA_ "Confidence" SG_ 1294 CP_a075_commsFailReason 1;
BA_ "Confidence" SG_ 1294 CP_a078_VC_tempAmbientFiltered 1;
BA_ "GenSigSNA" SG_ 1294 CP_a078_VC_tempAmbientFiltered "0";
BA_ "Confidence" SG_ 1294 CP_a078_pinTemperature1 1;
BA_ "GenSigSNA" SG_ 1294 CP_a078_pinTemperature1 "255";
BA_ "Confidence" SG_ 1294 CP_a078_pinTemperature2 1;
BA_ "GenSigSNA" SG_ 1294 CP_a078_pinTemperature2 "255";
BA_ "Confidence" SG_ 1294 CP_a078_pinTemperature3 1;
BA_ "GenSigSNA" SG_ 1294 CP_a078_pinTemperature3 "255";
BA_ "Confidence" SG_ 1294 CP_a079_VC_tempAmbientFiltered 1;
BA_ "GenSigSNA" SG_ 1294 CP_a079_VC_tempAmbientFiltered "0";
BA_ "Confidence" SG_ 1294 CP_a079_pinTemperature1 1;
BA_ "GenSigSNA" SG_ 1294 CP_a079_pinTemperature1 "255";
BA_ "Confidence" SG_ 1294 CP_a079_pinTemperature2 1;
BA_ "GenSigSNA" SG_ 1294 CP_a079_pinTemperature2 "255";
BA_ "Confidence" SG_ 1294 CP_a079_pinTemperature3 1;
BA_ "GenSigSNA" SG_ 1294 CP_a079_pinTemperature3 "255";
BA_ "Confidence" SG_ 1294 CP_a084_proximityV 1;
BA_ "Confidence" SG_ 1294 CP_a084_cc1Voltage 1;
BA_ "Confidence" SG_ 1294 CP_a084_cc2Voltage 1;
BA_ "Confidence" SG_ 1294 CP_a085_dcPinTemp 1;
BA_ "Confidence" SG_ 1294 CP_a086_dcPinTemp 1;
BA_ "Confidence" SG_ 1294 CP_a089_gtwPlcSupportType 1;
BA_ "Confidence" SG_ 1294 CP_a090_evseIsoStatus 1;
BA_ "Confidence" SG_ 1294 CP_a090_ccsDcState 1;
BA_ "Confidence" SG_ 1294 CP_a091_fcType 1;
BA_ "GenSigSNA" SG_ 1294 CP_a091_fcType "7";
BA_ "Confidence" SG_ 1294 CP_a095_packCurrent 1;
BA_ "Confidence" SG_ 1294 CP_a095_dcOutputCurrent 1;
BA_ "Confidence" SG_ 1294 CP_a095_ambientTemp 1;
BA_ "Confidence" SG_ 1294 CP_a095_fcType 1;
BA_ "GenSigSNA" SG_ 1294 CP_a095_fcType "7";
BA_ "Confidence" SG_ 1294 CP_a095_fcBrand 1;
BA_ "GenSigSNA" SG_ 1294 CP_a095_fcBrand "0";
BA_ "Confidence" SG_ 1294 CP_a099_proximity 1;
BA_ "GenSigSNA" SG_ 1294 CP_a099_proximity "0";
BA_ "Confidence" SG_ 1294 CP_a099_pilot 1;
BA_ "GenSigSNA" SG_ 1294 CP_a099_pilot "7";
BA_ "Confidence" SG_ 1294 CP_a103_proximityV 1;
BA_ "Confidence" SG_ 1294 CP_a109_thermistorTemp 1;
BA_ "Confidence" SG_ 1294 CP_a110_thermistorTemp 1;
BA_ "Confidence" SG_ 1294 CP_a110_thermalVelocity 1;
BA_ "GenSigSNA" SG_ 1294 CP_a110_thermalVelocity "511";
BA_ "Confidence" SG_ 1294 CP_a111_heaterTemperature 1;
BA_ "GenSigSNA" SG_ 1294 CP_a111_heaterTemperature "255";
BA_ "Confidence" SG_ 1294 CP_a111_VC_tempAmbientFiltered 1;
BA_ "GenSigSNA" SG_ 1294 CP_a111_VC_tempAmbientFiltered "0";
BA_ "Confidence" SG_ 1294 CP_a112_heaterTemperature 1;
BA_ "GenSigSNA" SG_ 1294 CP_a112_heaterTemperature "255";
BA_ "Confidence" SG_ 1294 CP_a113_heaterTemperature 1;
BA_ "GenSigSNA" SG_ 1294 CP_a113_heaterTemperature "255";
BA_ "Confidence" SG_ 1294 CP_a113_heaterCurrent 1;
BA_ "SystemSignalLongSymbol" SG_ 1294 CP_a116_temperatureSensorMismatc "CP_a116_temperatureSensorMismatch";
BA_ "Confidence" SG_ 1294 CP_a117_heaterTemperature 1;
BA_ "GenSigSNA" SG_ 1294 CP_a117_heaterTemperature "255";
BA_ "Confidence" SG_ 1294 CP_a117_averageError 1;
BA_ "GenSigSNA" SG_ 1294 CP_a117_averageError "255";
BA_ "Confidence" SG_ 1294 CP_a120_oldProximtyV 1;
BA_ "Confidence" SG_ 1294 CP_a120_newProximtyV 1;
BA_ "Confidence" SG_ 1294 CP_a120_chargeVoltage 1;
BA_ "Confidence" SG_ 1294 CP_a120_chargeCurrent 1;
BA_ "Confidence" SG_ 1294 CP_a120_dcPinTemp 1;
BA_ "GenSigSNA" SG_ 1294 CP_a120_dcPinTemp "255";
BA_ "Confidence" SG_ 1294 CP_a120_cableType 1;
BA_ "GenSigSNA" SG_ 1294 CP_a120_cableType "5";
BA_ "Confidence" SG_ 1294 CP_a124_ivledState 1;
BA_ "Confidence" SG_ 1294 CP_a124_ivledVoltage 1;
BA_ "Confidence" SG_ 1294 CP_a129_bldcDriverState 1;
BA_ "Confidence" SG_ 1294 CP_a131_powerTransferProtocol 1;
BA_ "Confidence" SG_ 1294 CP_a135_sdpErr 1;
BA_ "Confidence" SG_ 1294 CP_a135_pilotState 1;
BA_ "GenSigSNA" SG_ 1294 CP_a135_pilotState "7";
BA_ "Confidence" SG_ 1294 CP_a138_FC_type 1;
BA_ "GenSigSNA" SG_ 1294 CP_a138_FC_type "7";
BA_ "Confidence" SG_ 1294 CP_a138_latchState 1;
BA_ "GenSigSNA" SG_ 1294 CP_a138_latchState "0";
BA_ "Confidence" SG_ 1294 CP_a138_CP_proximity 1;
BA_ "GenSigSNA" SG_ 1294 CP_a138_CP_proximity "0";
BA_ "Confidence" SG_ 1294 CP_a139_latchState 1;
BA_ "GenSigSNA" SG_ 1294 CP_a139_latchState "0";
BA_ "Confidence" SG_ 1294 CP_a139_CP_proximity 1;
BA_ "GenSigSNA" SG_ 1294 CP_a139_CP_proximity "0";
BA_ "Confidence" SG_ 1294 CP_a140_latchState 1;
BA_ "GenSigSNA" SG_ 1294 CP_a140_latchState "0";
BA_ "Confidence" SG_ 1294 CP_a140_CP_proximity 1;
BA_ "GenSigSNA" SG_ 1294 CP_a140_CP_proximity "0";
BA_ "Confidence" SG_ 1294 CP_a141_latchState 1;
BA_ "GenSigSNA" SG_ 1294 CP_a141_latchState "0";
BA_ "Confidence" SG_ 1294 CP_a141_CP_proximity 1;
BA_ "GenSigSNA" SG_ 1294 CP_a141_CP_proximity "0";
BA_ "Confidence" SG_ 1294 CP_a142_cc1Voltage 1;
BA_ "Confidence" SG_ 1294 CP_a142_cc2Voltage 1;
BA_ "Confidence" SG_ 1294 CP_a146_v2gMessage 1;
BA_ "Confidence" SG_ 1294 CP_a151_pilotHighMin 1;
BA_ "Confidence" SG_ 1294 CP_a151_pilotHighMax 1;
BA_ "Confidence" SG_ 1294 CP_a151_pilotLowMin 1;
BA_ "Confidence" SG_ 1294 CP_a151_pilotLowMax 1;
BA_ "Confidence" SG_ 1294 CP_a152_maxPilotSwcanHigh 1;
BA_ "Confidence" SG_ 1294 CP_a152_minPilotSwcanHigh 1;
BA_ "Confidence" SG_ 1294 CP_a152_maxPilotSwcanLow 1;
BA_ "Confidence" SG_ 1294 CP_a152_minPilotSwcanLow 1;
BA_ "Confidence" SG_ 1294 CP_a153_acPinTempVelocity 1;
BA_ "GenSigSNA" SG_ 1294 CP_a153_acPinTempVelocity "511";
BA_ "Confidence" SG_ 1294 CP_a153_acPinTemp1 1;
BA_ "GenSigSNA" SG_ 1294 CP_a153_acPinTemp1 "255";
BA_ "Confidence" SG_ 1294 CP_a153_acPinTemp2 1;
BA_ "GenSigSNA" SG_ 1294 CP_a153_acPinTemp2 "255";
BA_ "Confidence" SG_ 1294 CP_a153_ambientTemp 1;
BA_ "Confidence" SG_ 1294 CP_a153_pcsLineChargeCurrent 1;
BA_ "Confidence" SG_ 1294 CP_a154_acPinTempVelocity 1;
BA_ "GenSigSNA" SG_ 1294 CP_a154_acPinTempVelocity "511";
BA_ "Confidence" SG_ 1294 CP_a154_acPinTemp1 1;
BA_ "GenSigSNA" SG_ 1294 CP_a154_acPinTemp1 "255";
BA_ "Confidence" SG_ 1294 CP_a154_acPinTemp2 1;
BA_ "GenSigSNA" SG_ 1294 CP_a154_acPinTemp2 "255";
BA_ "Confidence" SG_ 1294 CP_a154_ambientTemp 1;
BA_ "Confidence" SG_ 1294 CP_a154_pcsLineChargeCurrent 1;
BA_ "Confidence" SG_ 1294 CP_a155_hallSensorVoltage 1;
BA_ "Confidence" SG_ 1294 CP_a161_pilotHighMin 1;
BA_ "Confidence" SG_ 1294 CP_a161_pilotHighMax 1;
BA_ "Confidence" SG_ 1294 CP_a161_pilotLowMin 1;
BA_ "Confidence" SG_ 1294 CP_a161_pilotLowMax 1;
BA_ "Confidence" SG_ 1294 CP_a162_maxPilotSwcanHigh 1;
BA_ "Confidence" SG_ 1294 CP_a162_minPilotSwcanHigh 1;
BA_ "Confidence" SG_ 1294 CP_a162_maxPilotSwcanLow 1;
BA_ "Confidence" SG_ 1294 CP_a162_minPilotSwcanLow 1;
BA_ "Confidence" SG_ 1294 CP_a163_cover1OpenCounts 1;
BA_ "Confidence" SG_ 1294 CP_a163_cover2OpenCounts 1;
BA_ "Confidence" SG_ 1294 CP_a163_cover1State 1;
BA_ "GenSigSNA" SG_ 1294 CP_a163_cover1State "4";
BA_ "Confidence" SG_ 1294 CP_a163_cover2State 1;
BA_ "GenSigSNA" SG_ 1294 CP_a163_cover2State "4";
BA_ "Confidence" SG_ 1294 CP_a164_VC_tempAmbientFiltered 1;
BA_ "GenSigSNA" SG_ 1294 CP_a164_VC_tempAmbientFiltered "0";
BA_ "Confidence" SG_ 1294 CP_a164_minInternalPinTemp 1;
BA_ "GenSigSNA" SG_ 1294 CP_a164_minInternalPinTemp "255";
BA_ "Confidence" SG_ 1294 CP_a173_cover1OpenCounts 1;
BA_ "Confidence" SG_ 1294 CP_a173_cover2OpenCounts 1;
BA_ "Confidence" SG_ 1294 CP_a173_cover1State 1;
BA_ "GenSigSNA" SG_ 1294 CP_a173_cover1State "4";
BA_ "Confidence" SG_ 1294 CP_a173_cover2State 1;
BA_ "GenSigSNA" SG_ 1294 CP_a173_cover2State "4";
BA_ "Confidence" SG_ 1294 CP_a189_resistiveDividerVoltage 1;
BA_ "Confidence" SG_ 1294 CP_a205_doorPotFiltered 1;
BA_ "SystemSignalLongSymbol" SG_ 1294 CP_a205_doorPositionEstimationSu "CP_a205_doorPositionEstimationSupported";
BA_ "Confidence" SG_ 1294 CP_a205_bldcMotorState 1;
BA_ "Confidence" SG_ 1294 CP_a205_presenceVoltage 1;
BA_ "Confidence" SG_ 1294 CP_a206_peToChassisVoltage 1;
VAL_ 914 BMS_packConfigMultiplexer 1 "Mux1" 0 "Mux0" ;
VAL_ 914 BMS_reservedConfig_0 36 "BMS_CONFIG_36" 35 "BMS_CONFIG_35" 34 "BMS_CONFIG_34" 33 "BMS_CONFIG_33" 32 "BMS_CONFIG_32" 31 "BMS_CONFIG_31" 30 "BMS_CONFIG_30" 29 "BMS_CONFIG_29" 28 "BMS_CONFIG_28" 27 "BMS_CONFIG_27" 26 "BMS_CONFIG_26" 25 "BMS_CONFIG_25" 24 "BMS_CONFIG_24" 23 "BMS_CONFIG_23" 22 "BMS_CONFIG_22" 21 "BMS_CONFIG_21" 20 "BMS_CONFIG_20" 19 "BMS_CONFIG_19" 18 "BMS_CONFIG_18" 17 "BMS_CONFIG_17" 16 "BMS_CONFIG_16" 15 "BMS_CONFIG_15" 14 "BMS_CONFIG_14" 13 "BMS_CONFIG_13" 12 "BMS_CONFIG_12" 11 "BMS_CONFIG_11" 10 "BMS_CONFIG_10" 9 "BMS_CONFIG_9" 8 "BMS_CONFIG_8" 7 "BMS_CONFIG_7" 6 "BMS_CONFIG_6" 5 "BMS_CONFIG_5" 4 "BMS_CONFIG_4" 3 "BMS_CONFIG_3" 2 "BMS_CONFIG_2" 1 "BMS_CONFIG_1" 0 "BMS_CONFIG_0" ;
VAL_ 914 BMS_moduleType 5 "BMS_MOD_TYPE_5" 4 "BMS_MOD_TYPE_4" 3 "BMS_MOD_TYPE_3" 2 "BMS_MOD_TYPE_2" 1 "BMS_MOD_TYPE_1" 0 "BMS_MOD_TYPE_UNKNOWN" ;
VAL_ 914 BMS_thermalPackType 9 "E3D_40P" 8 "E3D" 7 "BLADERUNNER_E1" 6 "BFF00S" 5 "P2" 4 "BFF00_E1" 3 "CATL_E1" 2 "E3" 1 "E1" 0 "UNKNOWN" ;
VAL_ 914 BMS_standbySupplyContinuousPower 3 "17W" 2 "16W" 1 "4W" 0 "0W" ;
VAL_ 914 BMS_beginningOfLifePackEnergy 1023 "SNA" ;
VAL_ 1810 BMS_packTemperatureMultiplexer 5 "Mux5" 4 "Mux4" 3 "Mux3" 2 "Mux2" 1 "Mux1" 0 "Mux0" ;
VAL_ 1810 BMS_packTemperatureStatus1 3 "SENSOR_BYPASSED" 2 "SENSOR_NOMINAL" 1 "SENSOR_BAD" 0 "SENSOR_MISSING" ;
VAL_ 1810 BMS_packTemperatureStatus2 3 "SENSOR_BYPASSED" 2 "SENSOR_NOMINAL" 1 "SENSOR_BAD" 0 "SENSOR_MISSING" ;
VAL_ 1810 BMS_packTemperatureStatus3 3 "SENSOR_BYPASSED" 2 "SENSOR_NOMINAL" 1 "SENSOR_BAD" 0 "SENSOR_MISSING" ;
VAL_ 1810 BMS_packTemperatureStatus4 3 "SENSOR_BYPASSED" 2 "SENSOR_NOMINAL" 1 "SENSOR_BAD" 0 "SENSOR_MISSING" ;
VAL_ 1810 BMS_packTemperatureStatus5 3 "SENSOR_BYPASSED" 2 "SENSOR_NOMINAL" 1 "SENSOR_BAD" 0 "SENSOR_MISSING" ;
VAL_ 1810 BMS_packTemperatureStatus6 3 "SENSOR_BYPASSED" 2 "SENSOR_NOMINAL" 1 "SENSOR_BAD" 0 "SENSOR_MISSING" ;
VAL_ 1810 BMS_packTemperatureStatus7 3 "SENSOR_BYPASSED" 2 "SENSOR_NOMINAL" 1 "SENSOR_BAD" 0 "SENSOR_MISSING" ;
VAL_ 1810 BMS_packTemperatureStatus8 3 "SENSOR_BYPASSED" 2 "SENSOR_NOMINAL" 1 "SENSOR_BAD" 0 "SENSOR_MISSING" ;
VAL_ 1810 BMS_packTemperatureStatus9 3 "SENSOR_BYPASSED" 2 "SENSOR_NOMINAL" 1 "SENSOR_BAD" 0 "SENSOR_MISSING" ;
VAL_ 1810 BMS_packTemperatureStatus10 3 "SENSOR_BYPASSED" 2 "SENSOR_NOMINAL" 1 "SENSOR_BAD" 0 "SENSOR_MISSING" ;
VAL_ 1810 BMS_packTemperatureStatus11 3 "SENSOR_BYPASSED" 2 "SENSOR_NOMINAL" 1 "SENSOR_BAD" 0 "SENSOR_MISSING" ;
VAL_ 1810 BMS_packTemperatureStatus12 3 "SENSOR_BYPASSED" 2 "SENSOR_NOMINAL" 1 "SENSOR_BAD" 0 "SENSOR_MISSING" ;
VAL_ 1810 BMS_packTemperatureStatus13 3 "SENSOR_BYPASSED" 2 "SENSOR_NOMINAL" 1 "SENSOR_BAD" 0 "SENSOR_MISSING" ;
VAL_ 1810 BMS_packTemperatureStatus14 3 "SENSOR_BYPASSED" 2 "SENSOR_NOMINAL" 1 "SENSOR_BAD" 0 "SENSOR_MISSING" ;
VAL_ 1810 BMS_packTemperatureStatus15 3 "SENSOR_BYPASSED" 2 "SENSOR_NOMINAL" 1 "SENSOR_BAD" 0 "SENSOR_MISSING" ;
VAL_ 1810 BMS_packTemperatureStatus16 3 "SENSOR_BYPASSED" 2 "SENSOR_NOMINAL" 1 "SENSOR_BAD" 0 "SENSOR_MISSING" ;
VAL_ 1810 BMS_packTemperatureStatus17 3 "SENSOR_BYPASSED" 2 "SENSOR_NOMINAL" 1 "SENSOR_BAD" 0 "SENSOR_MISSING" ;
VAL_ 1810 BMS_packTemperatureStatus18 3 "SENSOR_BYPASSED" 2 "SENSOR_NOMINAL" 1 "SENSOR_BAD" 0 "SENSOR_MISSING" ;
VAL_ 594 BMS_powerLimitsState 1 "POWER_CALCULATED_FOR_DRIVE" 0 "POWER_NOT_CALCULATED_FOR_DRIVE" ;
VAL_ 674 BMS_acRippleFrequencyRequest 1023 "SNA" ;
VAL_ 674 BMS_acRippleRequest 4 "RIPPLE_FAULTED" 3 "RIPPLE_ON" 2 "RIPPLE_STANDBY" 1 "RIPPLE_OFF" 0 "RIPPLE_NOT_SUPPORTED" ;
VAL_ 1834 BMS_serialNumberMultiplexer 2 "BMS_SERIAL_MUX2" 1 "BMS_SERIAL_MUX1" 0 "BMS_SERIAL_MUX0" ;
VAL_ 658 BMS_instantChargePowerCapability 65535 "SNA" ;
VAL_ 1170 BMS_sohEnergyPercent 1023 "SNA" ;
VAL_ 1170 BMS_userFacingSohTestState 5 "CHARGE_REST" 4 "CHARGE" 3 "DISCHARGE_REST" 2 "DISCHARGE" 1 "HEAT_PACK" 0 "NOT_RUNNING" ;
VAL_ 1170 BMS_userFacingSohTestEndMode 5 "TEST_COMPLETE_WITH_SOC_IMBALANCE" 4 "TEST_COMPLETE" 3 "FAILED" 2 "REQUEST_DROPPED" 1 "RUNNING" 0 "NONE" ;
VAL_ 1170 BMS_timeSinceSohUpdate 4095 "SNA" ;
VAL_ 1170 BMS_requiredEvsePowerForSoh 255 "SNA" ;
VAL_ 1170 BMS_distanceSinceSohUpdate 65535 "SNA" ;
VAL_ 530 BMS_contactorState 6 "BMS_CTRSET_BLOCKED" 5 "BMS_CTRSET_WELDED" 4 "BMS_CTRSET_CLOSED" 3 "BMS_CTRSET_CLOSING" 2 "BMS_CTRSET_OPENING" 1 "BMS_CTRSET_OPEN" 0 "BMS_CTRSET_SNA" ;
VAL_ 530 BMS_userChargeStatus 6 "BMS_CALIBRATING" 5 "BMS_CHARGE_STOPPED" 4 "BMS_CHARGE_COMPLETE" 3 "BMS_CHARGING" 2 "BMS_ABOUT_TO_CHARGE" 1 "BMS_NO_POWER" 0 "BMS_DISCONNECTED" ;
VAL_ 530 BMS_batteryInputPower 65535 "SNA" ;
VAL_ 530 BMS_state 10 "BMS_DIAG" 9 "BMS_SNA" 8 "BMS_TEST" 7 "BMS_WELD" 6 "BMS_FAULT" 5 "BMS_CLEAR_FAULT" 4 "BMS_FEIM" 3 "BMS_CHARGE" 2 "BMS_SUPPORT" 1 "BMS_DRIVE" 0 "BMS_STANDBY" ;
VAL_ 530 BMS_diLimpRequest 1 "LIMP_REQUEST_WELDED" 0 "LIMP_REQUEST_NONE" ;
VAL_ 530 BMS_chgPowerAvailable 4095 "SNA" ;
VAL_ 530 BMS_acManagerState 11 "FAULTED" 10 "OPEN_AC_RELAYS" 9 "DISABLE_PCS" 8 "GRID_FORM_ACTIVE" 7 "GRID_FOLLOW_ACTIVE" 6 "TETHERING_ACTIVE" 5 "CHARGING_ACTIVE" 4 "ENABLE_PCS" 3 "ENABLE_FC_LINK_FOR_AC" 2 "REQUEST_POWER_TRANSFER" 1 "STANDBY" 0 "INACTIVE" ;
VAL_ 530 BMS_smStateRequest 10 "BMS_DIAG" 9 "BMS_SNA" 8 "BMS_TEST" 7 "BMS_WELD" 6 "BMS_FAULT" 5 "BMS_CLEAR_FAULT" 4 "BMS_FEIM" 3 "BMS_CHARGE" 2 "BMS_SUPPORT" 1 "BMS_DRIVE" 0 "BMS_STANDBY" ;
VAL_ 530 BMS_hvState 6 "HV_UP" 5 "HV_UP_FOR_DC_CHARGE" 4 "HV_UP_FOR_CHARGE" 3 "HV_UP_FOR_DRIVE" 2 "HV_GOING_DOWN" 1 "HV_COMING_UP" 0 "HV_DOWN" ;
VAL_ 786 BMS_thermalStatusMultiplexer 1 "Mux1" 0 "Mux0" ;
VAL_ 1071 BMS_v2xSoe 65535 "SNA" ;
VAL_ 1071 BMS_v2xFullEnergy 4095 "SNA" ;
VAL_ 1071 BMS_v2xPackPower 511 "SNA" ;
VAL_ 1071 BMS_acDischargeBlockedReason 41 "PRECHARGE_NOT_COMPLETE" 40 "EVSE_OUTPUT_CURRENT_NOT_LOW" 39 "ALL_RETRIES_EXHAUSTED" 38 "TEMP_TOO_LOW" 37 "FEATURE_DISABLED" 36 "SOE_TOO_LOW" 35 "AC_RELAYS_NOT_OPEN" 34 "PCS_NOT_DISABLED" 33 "CP_INLET_STILL_ENERGIZED" 32 "PCS_NOT_ENABLED" 31 "CP_NOT_ENABLED" 30 "CP_NOT_READY" 29 "SYSTEM_NOT_ENABLED" 28 "PCS_DISALLOWS" 27 "CP_DISALLOWS" 26 "SYSTEM_NOT_ALLOWED" 25 "SYSTEM_NOT_POSSIBLE" 24 "PCS_GRACEFUL_SHUTDOWN_REQUESTED" 23 "CP_GRACEFUL_SHUTDOWN_REQUESTED" 22 "NOT_NEEDED_OR_WANTED" 21 "EVSE_NOT_READY" 20 "EVSE_NOT_PRESENT" 19 "STATE_TIMEOUT_EXPIRED" 18 "FC_LINK_NOT_READY" 17 "FC_CONTACTORS_NOT_CLOSED" 16 "FC_CONTACTORS_NOT_OPEN" 15 "EVSE_NOT_COMPATIBLE" 14 "FC_LINK_NOT_ALLOWED_TO_ENERGIZE" 13 "ABORT_SUPERDISCHARGE_ALERT_SET" 12 "ABORT_CHARGE_ALERT_SET" 11 "PCS_ESCALATED_SHUTDOWN_REQUESTED" 10 "CP_ESCALATED_SHUTDOWN_REQUESTED" 7 "POWERSHARE_PROTECTION_TRIPPED" 6 "SYSTEM_DIRECTOR_FAULT_REQUESTED" 5 "CP_FAULT_LINE_ASSERTED" 4 "PCS_EMERGENCY_SHUTDOWN_REQUESTED" 3 "CP_EMERGENCY_SHUTDOWN_REQUESTED" 2 "PCS_MIA" 1 "CP_MIA" 0 "COND_NONE" ;
VAL_ 1071 BMS_backupTimeRemaining 255 "SNA" ;
VAL_ 754 BMS_nmKeepAwakeReason 8 "BMS_KEEPAWAKE_REASON_OTA" 7 "BMS_KEEPAWAKE_REASON_PRECONDITIONING" 6 "BMS_KEEPAWAKE_REASON_CP_ACTIVE" 5 "BMS_KEEPAWAKE_REASON_BMS_ACTIVE" 4 "BMS_KEEPAWAKE_REASON_HVP_ACTIVE" 3 "BMS_KEEPAWAKE_REASON_FC_CTR_CLEANING" 2 "BMS_KEEPAWAKE_REASON_CRITICAL_ALERT" 1 "BMS_KEEPAWAKE_REASON_CTRS_CLOSED" 0 "BMS_KEEPAWAKE_REASON_NONE_SNA" ;
VAL_ 754 BMS_nmWakeUpReason 4 "BMS_WAKEUP_REASON_CRITICALALERT" 3 "BMS_WAKEUP_REASON_WANTTOCHARGE" 2 "BMS_WAKEUP_REASON_CAN_HVS" 1 "BMS_WAKEUP_REASON_CAN_VEH" 0 "BMS_WAKEUP_REASON_NONE" ;
VAL_ 810 BMS_isolationResistance 1023 "SNA" ;
VAL_ 810 BMS_chgTimeToFull 4095 "SNA" ;
VAL_ 1116 CC_alertID 61 "a061_unfinishedCommissioning" 60 "a060_persistenceFault" 57 "a057_chcVitalsRequestFailure" 52 "a052_vRefOutOfRangePWM" 51 "a051_chcCriticalFault" 50 "a050_eFuseFault" 49 "a049_rs485Fault" 48 "a048_ACMDAdapterFault" 47 "a047_MDMotorContFault" 46 "a046_GFCIConfigInvalid" 45 "a045_ACPowerLoss" 44 "a044_relayCoilVoltageRationality" 43 "a043_configurationRequired" 42 "a042_pcbaTempFoldback" 41 "a041_inputWiringFoldback" 40 "a040_handleTempFoldback" 39 "a039_internalModuleOverTemp" 38 "a038_internalModuleMia" 37 "a037_internalModuleWatchdogExpired" 36 "a036_contactorStuckOpen" 35 "a035_CCIDCalibration" 34 "a034_bootAlert" 33 "a033_vRefOutOfRange" 32 "a032_meteringFailure" 31 "a031_pllLockLost" 30 "a030_masterSlaveMismatch" 29 "a029_PilotFFault" 28 "a028_CB_rotarySelect" 27 "a027_vehicleHandleTemp" 26 "a026_wallPlugTemp" 25 "a025_evseTemp" 24 "a024_CB_masterISetTooLow" 23 "a023_CB_tooManySlaves" 22 "a022_CB_tooManyMasters" 21 "a021_CB_noMaster" 20 "a020_3vRailIncorrect" 19 "a019_proxDisconnected" 18 "a018_PilotDFault" 17 "a017_PilotCFault" 16 "a016_PilotBFault" 15 "a015_PilotAFault" 14 "a014_mcuSelfTestFault" 13 "a013_vehConnOT" 12 "a012_wallPlugOT" 11 "a011_ambientOT" 10 "a010_contactorWelded" 9 "a009_inputMiswired" 8 "a008_inputUnderVoltage" 7 "a007_inputOverVoltage" 6 "a006_inputOverCurrent" 5 "a005_groundedNeutral" 4 "a004_CCIDSelfTestFault" 3 "a003_CCIDTripped" 2 "a002_gndMonIntrptLoadSide" 1 "a001_gndMonIntrptLineSide" 0 "ALERT_DO_NOT_USE_ZERO" ;
VAL_ 1116 CC_alertType 1 "SET" 0 "CLEARED" ;
VAL_ 1116 CC_a001_groundResistance 4095 "SNA" 4094 "NO_GROUND" ;
VAL_ 1116 CC_a003_gfciFaultReason 4 "DC_PEAK" 3 "DC_LPF" 2 "AC_PEAK" 1 "AC_LPF" 0 "SNA" ;
VAL_ 1116 CC_a004_gfciErrorReason 5 "TEST_SIGNAL_ERROR" 4 "AC_OFFSET_ERROR" 3 "DC_OFFSET_ERROR" 2 "ASIC_REASON" 1 "IO_ERROR" 0 "SNA" ;
VAL_ 1116 CC_a014_failureCause 4 "DCGFCI_INIT_FAILED" 3 "METER_INIT_FAILED" 2 "CONFIG_NOT_RECEIVED" 1 "OTHER" ;
VAL_ 1116 CC_a027_handleTempFaultReason 5 "CHC_OPEN_CIRCUIT" 4 "CHC_SHORT_CIRCUIT" 3 "CHC_INVALID_VITAL" 2 "NTC_BUTTON_PRESSED" 1 "NTC_OPEN_CIRCUIT" 0 "TEMP_GOOD" ;
VAL_ 796 CC_currentLimit 255 "SNA" ;
VAL_ 796 CC_pilotState 3 "CC_PILOT_STATE_SNA" 2 "CC_PILOT_STATE_FAULTED" 1 "CC_PILOT_STATE_IDLE" 0 "CC_PILOT_STATE_READY" ;
VAL_ 796 CC_numPhases 0 "SNA" ;
VAL_ 796 CC_line1Voltage 511 "SNA" ;
VAL_ 796 CC_gridGrounding 2 "CC_GRID_GROUNDING_SNA" 1 "CC_GRID_GROUNDING_IT_SplitPhase" 0 "CC_GRID_GROUNDING_TN_TT" ;
VAL_ 796 CC_line2Voltage 511 "SNA" ;
VAL_ 796 CC_line3Voltage 511 "SNA" ;
VAL_ 796 CC_groundResistance 4095 "SNA" 4094 "NO_GROUND" ;
VAL_ 797 CC_chgStatus2Index 0 "Mux0" ;
VAL_ 797 CC_buttonState 1 "CC_BUTTON_PRESSED" 0 "CC_BUTTON_RELEASED" ;
VAL_ 797 EVSE_v2xSupport 2 "V2X_OVER_SWCAN" 1 "V2X_OVER_PLC" 0 "V2X_NOT_SUPPORTED" ;
VAL_ 797 EVSE_v2xSessionType 0 "SESSION_TYPE_SNA" ;
VAL_ 812 CC_logIndex 13 "Mux13" 12 "Mux12" 11 "Mux11" 10 "Mux10" 4 "Mux4" 3 "Mux3" 2 "Mux2" 1 "Mux1" 0 "Mux0" ;
VAL_ 812 CC_activeConnectorID 255 "SNA" ;
VAL_ 812 CC_temperature1 127 "SNA" ;
VAL_ 812 CC_temperature2 127 "SNA" ;
VAL_ 812 CC_temperature3 127 "SNA" ;
VAL_ 812 CC_contactor1Closed 3 "CC_CONTACTOR_SNA" 1 "CC_CONTACTOR_CLOSED" 0 "CC_CONTACTOR_OPEN" ;
VAL_ 812 CC_contactor2Closed 3 "CC_CONTACTOR_SNA" 1 "CC_CONTACTOR_CLOSED" 0 "CC_CONTACTOR_OPEN" ;
VAL_ 812 CC_temperature4 127 "SNA" ;
VAL_ 812 CC_conn1Current 255 "SNA" ;
VAL_ 812 CC_conn2Current 255 "SNA" ;
VAL_ 812 CC_conn3Current 255 "SNA" ;
VAL_ 812 CC_conn4Current 255 "SNA" ;
VAL_ 870 CMPD_infoIndex 255 "END" 31 "SUBCOMPONENT_GITHASH" 30 "PACKAGE_SN_8_14" 29 "PACKAGE_SN_1_7" 27 "PACKAGE_PN_15_20" 26 "PACKAGE_PN_8_14" 25 "PACKAGE_PN_1_7" 23 "SUBCOMPONENT2" 22 "VARIANTCRC" 20 "UDS_PROTOCOL_BOOTCRC" 19 "VERSION_DEPRECATED" 18 "BOOTLOADER_GITHASH" 17 "APP_GITHASH" 16 "SUBCOMPONENT" 15 "BOOTLOADER_CRC" 14 "BOOTLOADER_SVN" 13 "APP_CRC" 11 "PCBAID_ASSYID_USAGEID" 10 "BUILD_HWID_COMPONENTID" 9 "DEPRECATED_9" 8 "DEPRECATED_8" 7 "DEPRECATED_7" 6 "DEPRECATED_6" 5 "DEPRECATED_5" 4 "DEPRECATED_4" 3 "DEPRECATED_3" 2 "DEPRECATED_2" 1 "DEPRECATED_1" 0 "DEPRECATED_0" ;
VAL_ 870 CMPD_infoBuildType 4 "INFO_MFG_BUILD" 3 "INFO_TRACEABLE_CI_BUILD" 2 "INFO_LOCAL_BUILD" 1 "INFO_PLATFORM_BUILD" 0 "INFO_UNKNOWN_BUILD" ;
VAL_ 870 CMPD_infoAssemblyId 255 "ASSEMBLY_SNA" 1 "ASSEMBLY1" ;
VAL_ 679 CMPD_state 15 "CMPD_STATE_SNA" 4 "CMPD_STATE_IDLE" 3 "CMPD_STATE_FAULT" 2 "CMPD_STATE_STANDBY" 1 "CMPD_STATE_RUNNING" 0 "CMPD_STATE_INIT" ;
VAL_ 679 CMPD_wasteHeatState 3 "CMPD_WASTE_HEAT_STATE_UNUSED" 2 "CMPD_WASTE_HEAT_STATE_NOT_AVAILABLE" 1 "CMPD_WASTE_HEAT_STATE_ACTIVE" 0 "CMPD_WASTE_HEAT_STATE_OFF" ;
VAL_ 867 CMP_infoIndex 255 "END" 31 "SUBCOMPONENT_GITHASH" 30 "PACKAGE_SN_8_14" 29 "PACKAGE_SN_1_7" 27 "PACKAGE_PN_15_20" 26 "PACKAGE_PN_8_14" 25 "PACKAGE_PN_1_7" 23 "SUBCOMPONENT2" 22 "VARIANTCRC" 20 "UDS_PROTOCOL_BOOTCRC" 19 "VERSION_DEPRECATED" 18 "BOOTLOADER_GITHASH" 17 "APP_GITHASH" 16 "SUBCOMPONENT" 15 "BOOTLOADER_CRC" 14 "BOOTLOADER_SVN" 13 "APP_CRC" 11 "PCBAID_ASSYID_USAGEID" 10 "BUILD_HWID_COMPONENTID" 9 "DEPRECATED_9" 8 "DEPRECATED_8" 7 "DEPRECATED_7" 6 "DEPRECATED_6" 5 "DEPRECATED_5" 4 "DEPRECATED_4" 3 "DEPRECATED_3" 2 "DEPRECATED_2" 1 "DEPRECATED_1" 0 "DEPRECATED_0" ;
VAL_ 867 CMP_infoBuildType 4 "INFO_MFG_BUILD" 3 "INFO_TRACEABLE_CI_BUILD" 2 "INFO_LOCAL_BUILD" 1 "INFO_PLATFORM_BUILD" 0 "INFO_UNKNOWN_BUILD" ;
VAL_ 867 CMP_infoAssemblyId 255 "ASSEMBLY_SNA" 1 "ASSEMBLY1" ;
VAL_ 1294 CP_alertID 221 "a221_evseStartupTimeout" 220 "a220_mcsChargingInterrupted" 219 "a219_doorOpenInDrive" 218 "a218_v2gCommsFailure2" 217 "a217_teslaV2gCommsFailure" 216 "a216_mcsLinkLoss" 215 "a215_mcsMacPhyErrors" 214 "a214_mcsEthDriverRetransmitFail" 213 "a213_mcsTcpRetransmitStorm" 212 "a212_mcsPacketDrops" 211 "a211_lostCommsPCSL" 210 "a210_lostCommsPCSR" 209 "a209_macphyFault" 208 "a208_eipmCommsError" 207 "a207_v2xAuthenticationFailed" 206 "a206_peToChassisDisconnected" 205 "a205_doorPositionUndetectable" 204 "a204_sdpAttemptsFailed2" 203 "a203_evseCommTimeout2" 202 "a202_failedToEstablishV2gComm2" 201 "a201_uhfDoorOpenRepeatedlyOverLimit" 200 "d200_pilotCircuitIssue" 199 "d199_hardwareConfigMismatch" 198 "d198_couplerTempSensorCircuitErratic" 197 "d197_doorSensorCircuitErratic" 196 "d196_doorActuatorPerformanceIssue" 195 "d195_couplerLockActuatorIssue" 194 "d194_proximityCircuitRangeIssue" 193 "d193_proximityCircuitErratic" 192 "d192_couplerTempHigh" 191 "d191_latchConnectionIssue" 190 "d190_backCoverCircuitIssue" 189 "a189_resistivePresenceRationality" 188 "a188_v2lEvseRequiresUpdate" 187 "a187_highStackUsage" 186 "a186_spiDmaFailure" 185 "a185_pncAuthRejection" 184 "a184_certChangeEvent" 183 "a183_certManagerError" 182 "a182_pncdCommsError" 179 "a179_evseCommsTlsError" 178 "a178_v2xPlcCommsFault" 177 "a177_incompatibleV2lDeviceDetected" 176 "a176_lostCommsV2l" 175 "a175_fwdedMsgDropped" 174 "a174_fwdedMsgLoadWarning" 173 "a173_coverOpenAcChgBlocked" 172 "a172_triggerOdin" 170 "a170_selfTestFailed2" 168 "a168_pilotHSDFaulted" 167 "a167_doorIdIrrational" 166 "a166_faultLineMismatchDetected" 165 "a165_proxWiggleDetected" 164 "a164_latchRedisengageRequested" 163 "a163_coverOpenDcChgBlocked" 162 "a162_pilotEdgeDetectionFailedCN" 161 "a161_badPilotDiodeDetectedCN" 160 "a160_latchDisengageInDcCharge" 159 "a159_swcanHealthCheckFailed" 158 "a158_doorCloseRateLimiter" 157 "a157_doorOpenRateLimiter" 156 "a156_gbdcPrechargingConcern" 155 "a155_hallPresenceRationality" 154 "a154_acChargingStoppedOT" 153 "a153_thermalAcLimitActive" 152 "a152_pilotEdgeDetectionFailed" 151 "a151_badPilotDiodeDetected" 150 "a150_railToggleTimeout" 149 "a149_pilotPeriodInvalid" 148 "a148_bldcTachFeedbackMia" 147 "a147_inductiveRecoveredMia" 146 "a146_ccsEvseMalfunction" 145 "a145_modemAppLoadFailedNA" 144 "a144_nvmInitFailed" 143 "a143_unsupportedChargeAdapter" 142 "a142_gbdcScConnFault" 141 "a141_chademoAdapterFault" 140 "a140_superchargerFaulted" 139 "a139_pilotFaulted" 138 "a138_swcanCommsAcEvseFaulted" 137 "a137_plcForwardError" 136 "a136_sdpSideReqFailed" 135 "a135_sdpAttemptsFailed" 134 "a134_plcModemNotExpected" 133 "a133_proxNeverLatched" 132 "a132_contractAuthTimeout" 131 "a131_evseCommTimeout" 130 "a130_bldcDriverCommsRecovered" 129 "a129_bldcDriverCommsFailed" 128 "a128_lostCommsVC" 127 "a127_lostCommsHVLINK" 126 "a126_wakeOnUhfFault" 125 "a125_unexpectedLVJuiceState" 124 "a124_ivledFault" 123 "a123_latchPotIrrational" 122 "a122_plcModemFailure" 121 "a121_PLCRLY_lostCommsCP" 120 "a120_comboAdapterFoldback" 119 "a119_plcTransmitFailure" 118 "a118_iecComboLockUp" 117 "a117_inletHeaterUnableToRegulate" 116 "a116_misconfigurationDetected" 115 "a115_unexpectedTcan1145State" 114 "a114_ccsEvseFailed" 113 "a113_inletHeaterShortCircuit" 112 "a112_inletHeaterIrrationalTemperature" 111 "a111_inletHeaterUnableToHeat" 110 "a110_thermalVelocityHigh" 109 "a109_thermistorIrrational" 108 "a108_chademoOvertempFault" 107 "a107_chademoFoldbackActive" 106 "a106_uhfReceiverReset" 105 "a105_hwUnableToSleep" 104 "a104_uhfResetSuccessful" 103 "a103_proximityPeDisconnected" 102 "a102_wcOvertempFault" 101 "a101_wcFoldbackActive" 100 "a100_inletHarnessIdIrrational" 99 "a099_cableStateUnknown" 98 "a098_proximityWake" 97 "a097_modeTransitionFailure" 96 "a096_pilotWake" 95 "a095_thermalDcLimitActive" 94 "a094_inductiveResetSuccessful" 93 "a093_modemLoadedWithReset" 92 "a092_modemAppLoadFailed" 91 "a091_wrongSuperchargerHandle" 90 "a090_ccsEvseLowIso" 89 "a089_plcConfigMismatch" 88 "a088_dcTempModelDeviation" 87 "a087_dcTempModelFault" 86 "a086_dcPinTempIrrational" 85 "a085_dcPinTempFaulted" 84 "a084_proxPeDisconnected_gb" 83 "a083_watchdogTraceData" 82 "a082_powerOnReset" 81 "a081_swException" 80 "a080_taskStackOverflow" 79 "a079_cableNotSecuredCold" 78 "a078_latchNotDisengagedCold" 77 "a077_invalidMacAddress" 76 "a076_LDC1612errorWatchdog" 75 "a075_v2gCommsFailure" 74 "a074_failedToEstablishV2gComm" 73 "a073_iecComboShutdown" 72 "a072_v2gEvccTimeout" 71 "a071_exiDecodeFailure" 70 "a070_doorInductiveSensorReset" 69 "a069_doorInductiveSensorError" 68 "a068_doorSensorMismatch" 67 "a067_gbdcConnFault" 66 "a066_proxLatchedIdlePilot" 65 "a065_selfTestFailed" 64 "a064_superchargingBlocked" 63 "a063_scUpdateInProgress" 62 "a062_scOutOfService" 61 "a061_uhfReceiverMIA" 60 "a060_lostCommsPCS" 59 "a059_swcanError" 58 "a058_acChargeRetryPending" 57 "a057_ccs1AdapterBtnPress" 56 "a056_proxDisconnected" 55 "a055_chargeStoppedNoPilot" 54 "a054_cableNotSecured" 53 "a053_proxLatchedNoPilot" 52 "a052_chademoNotSupported" 51 "a051_doorInductiveSensorMIA" 50 "a050_latchNotConnected" 49 "a049_multipleCablesDetected" 48 "a048_lostCommsUI" 47 "a047_lostCommsVCFRONT" 46 "a046_lostCommsEVSE" 45 "a045_lostCommsVCSEC" 44 "a044_lostCommsHVP" 43 "a043_doorPotIrrational" 42 "a042_doorAssemblyBroken" 41 "a041_doorSensorUnplugged" 40 "a040_doNotUse" 39 "a039_latchMovement_2" 38 "a038_latchNotBlocking" 37 "a037_latchNotEngaged" 36 "a036_latchNotDisengaged" 35 "a035_latchMovement_1" 34 "a034_calibrationIncomplete" 33 "a033_spiOpen" 32 "a032_doorOpenExpectedClosed" 31 "a031_doorClosedCommandedOpen" 30 "a030_busOff" 29 "a029_doorClosedProxPilot" 28 "a028_insertEnableMismatch" 27 "a027_doorSensorOutOfSpec" 26 "a026_networkManagement" 25 "a025_ledsOC" 24 "a024_ledsUC" 23 "a023_gbdcSessionFailed" 22 "a022_zeroVuv" 21 "a021_zeroVov" 20 "a020_threeVuv" 19 "a019_threeVov" 18 "a018_fiveVuv" 17 "a017_fiveVov" 16 "a016_apsVuv" 15 "a015_apsVov" 14 "a014_lostCommsCHG" 13 "a013_lostCommsGTW" 12 "a012_ledDriver" 11 "a011_eeprom" 10 "a010_pilotRationality" 9 "a009_coverOpenAllChgBlocked" 8 "a008_memoryError" 7 "a007_watchdog" 6 "a006_lostCommsBMS" 5 "a005_gbdcLiveDisconnect" 4 "a004_proximityRationality" 3 "a003_canError" 2 "a002_canTx" 1 "a001_canRx" 0 "ALERT_DO_NOT_USE_ZERO" ;
VAL_ 1294 CP_alertType 1 "SET" 0 "CLEARED" ;
VAL_ 1294 CP_a005_gbdcState 15 "TESTER_PRESENT" 14 "FAULTED" 13 "RETRY_CHARGE" 12 "ERROR_HANDLING" 11 "END_OF_CHARGE" 10 "CHARGE_DISABLING" 9 "STOP_CHARGE_REQUESTED" 8 "CHARGING" 7 "READY_TO_CHARGE" 6 "VEH_PACK_PRECHARGE" 5 "CHARGE_PARAM_CONFIG" 4 "RECOGNITION" 3 "HANDSHAKING_EXT_ISO" 2 "COMMS_RECEIVED" 1 "WAIT_FOR_COMMS" 0 "INACTIVE" ;
VAL_ 1294 CP_a009_cover1State 4 "SNA" 3 "SHORT_TO_VBAT" 2 "SHORT_TO_GND" 1 "OPEN" 0 "CLOSED" ;
VAL_ 1294 CP_a009_cover2State 4 "SNA" 3 "SHORT_TO_VBAT" 2 "SHORT_TO_GND" 1 "OPEN" 0 "CLOSED" ;
VAL_ 1294 CP_a011_eepromErrorType 5 "VERSION" 4 "LOST" 3 "CRC" 2 "WRITE" 1 "READ" 0 "OPEN" ;
VAL_ 1294 CP_a023_stopChargeReason 8 "PARAM_MISMATCH" 7 "SUPERCHARGER_COMMS_TIMEOUT" 6 "LIVE_DISCONNECT" 5 "EVSE_CRITICAL_FAULT" 4 "EVSE_FAULT" 3 "COMMS_TIMEOUT" 2 "EVSE_REQUESTED" 1 "VEH_REQUESTED" 0 "STOP_REASON_NONE" ;
VAL_ 1294 CP_a023_failureReason 3 "CRITICAL_FAILURE" 2 "SHUTDOWN_FAILURE" 1 "ATTEMPTS_EXPIRED" 0 "FAILURE_NONE" ;
VAL_ 1294 CP_a029_CP_pilot 7 "SNA" 6 "UNUSED_6" 5 "INVALID" 4 "IDLE" 3 "FAST_CHARGE" 2 "LINE_CHARGE" 1 "FAULTED" 0 "NONE" ;
VAL_ 1294 CP_a029_CP_proximity 3 "LATCHED" 2 "UNLATCHED" 1 "DISCONNECTED" 0 "SNA" ;
VAL_ 1294 CP_a035_latchState 3 "BLOCKING" 2 "ENGAGED" 1 "DISENGAGED" 0 "SNA" ;
VAL_ 1294 CP_a035_inletID 4 "MCS" 3 "GBDC" 2 "GBAC" 1 "IEC" 0 "SAE" ;
VAL_ 1294 CP_a036_latchState 3 "BLOCKING" 2 "ENGAGED" 1 "DISENGAGED" 0 "SNA" ;
VAL_ 1294 CP_a036_inletID 4 "MCS" 3 "GBDC" 2 "GBAC" 1 "IEC" 0 "SAE" ;
VAL_ 1294 CP_a037_latchState 3 "BLOCKING" 2 "ENGAGED" 1 "DISENGAGED" 0 "SNA" ;
VAL_ 1294 CP_a037_inletID 4 "MCS" 3 "GBDC" 2 "GBAC" 1 "IEC" 0 "SAE" ;
VAL_ 1294 CP_a038_latchState 3 "BLOCKING" 2 "ENGAGED" 1 "DISENGAGED" 0 "SNA" ;
VAL_ 1294 CP_a038_inletID 4 "MCS" 3 "GBDC" 2 "GBAC" 1 "IEC" 0 "SAE" ;
VAL_ 1294 CP_a049_proximity 3 "LATCHED" 2 "UNLATCHED" 1 "DISCONNECTED" 0 "SNA" ;
VAL_ 1294 CP_a054_latchState 3 "BLOCKING" 2 "ENGAGED" 1 "DISENGAGED" 0 "SNA" ;
VAL_ 1294 CP_a054_CP_proximity 3 "LATCHED" 2 "UNLATCHED" 1 "DISCONNECTED" 0 "SNA" ;
VAL_ 1294 CP_a054_inletID 4 "MCS" 3 "GBDC" 2 "GBAC" 1 "IEC" 0 "SAE" ;
VAL_ 1294 CP_a056_latchState 3 "BLOCKING" 2 "ENGAGED" 1 "DISENGAGED" 0 "SNA" ;
VAL_ 1294 CP_a056_CP_proximity 3 "LATCHED" 2 "UNLATCHED" 1 "DISCONNECTED" 0 "SNA" ;
VAL_ 1294 CP_a058_CP_pilot 7 "SNA" 6 "UNUSED_6" 5 "INVALID" 4 "IDLE" 3 "FAST_CHARGE" 2 "LINE_CHARGE" 1 "FAULTED" 0 "NONE" ;
VAL_ 1294 CP_a058_CC_pilot 3 "SNA" 2 "FAULTED" 1 "IDLE" 0 "READY" ;
VAL_ 1294 CP_a058_FC_status 15 "NODATA" 14 "MALFUNCTION" 13 "NOTCOMPATIBLE" 7 "POST_OUT_OF_SERVICE" 6 "EXT_ISOACTIVE" 5 "INT_ISOACTIVE" 4 "DEPRECATED_4" 3 "DEPRECATED_3" 2 "UPDATE_IN_PROGRESS" 1 "READY" 0 "NOTREADY_SNA" ;
VAL_ 1294 CP_a058_latchState 3 "BLOCKING" 2 "ENGAGED" 1 "DISENGAGED" 0 "SNA" ;
VAL_ 1294 CP_a058_CP_proximity 3 "LATCHED" 2 "UNLATCHED" 1 "DISCONNECTED" 0 "SNA" ;
VAL_ 1294 CP_a061_controlState 10 "FAULT" 9 "SLEEP" 8 "HANDLE_FOUND" 7 "READ_RXFIFO" 6 "CHECK_RX" 5 "RX" 4 "PREPARE_RX" 3 "CALIBRATE" 2 "IDLE" 1 "CONFIG" 0 "INIT" ;
VAL_ 1294 CP_a061_lastControlState 10 "FAULT" 9 "SLEEP" 8 "HANDLE_FOUND" 7 "READ_RXFIFO" 6 "CHECK_RX" 5 "RX" 4 "PREPARE_RX" 3 "CALIBRATE" 2 "IDLE" 1 "CONFIG" 0 "INIT" ;
VAL_ 1294 CP_a062_FC_status 15 "NODATA" 14 "MALFUNCTION" 13 "NOTCOMPATIBLE" 7 "POST_OUT_OF_SERVICE" 6 "EXT_ISOACTIVE" 5 "INT_ISOACTIVE" 4 "DEPRECATED_4" 3 "DEPRECATED_3" 2 "UPDATE_IN_PROGRESS" 1 "READY" 0 "NOTREADY_SNA" ;
VAL_ 1294 CP_a062_FC_type 7 "SNA" 6 "OTHER" 5 "MC_EVSE" 4 "COMBO" 3 "CC_EVSE" 2 "GB" 1 "CHADEMO" 0 "SUPERCHARGER" ;
VAL_ 1294 CP_a063_FC_status 15 "NODATA" 14 "MALFUNCTION" 13 "NOTCOMPATIBLE" 7 "POST_OUT_OF_SERVICE" 6 "EXT_ISOACTIVE" 5 "INT_ISOACTIVE" 4 "DEPRECATED_4" 3 "DEPRECATED_3" 2 "UPDATE_IN_PROGRESS" 1 "READY" 0 "NOTREADY_SNA" ;
VAL_ 1294 CP_a063_FC_type 7 "SNA" 6 "OTHER" 5 "MC_EVSE" 4 "COMBO" 3 "CC_EVSE" 2 "GB" 1 "CHADEMO" 0 "SUPERCHARGER" ;
VAL_ 1294 CP_a066_proximity 3 "LATCHED" 2 "UNLATCHED" 1 "DISCONNECTED" 0 "SNA" ;
VAL_ 1294 CP_a071_expectedMessage 17 "NUM_MSG" 16 "MSG_NONE" 15 "SESSION_STOP" 14 "WELDING_DETECTION" 13 "POWER_DELIVERY_END" 12 "CHARGING_STATUS" 11 "CURRENT_DEMAND" 10 "POWER_DELIVERY_START" 9 "PRECHARGE" 8 "CABLE_CHECK" 7 "CHARGE_PARAMETER_DISCOVERY" 6 "CONTRACT_AUTHENTICATION" 5 "PAYMENT_DETAILS" 4 "SERVICE_PAYMENT_SELECTION" 3 "SERVICE_DETAIL" 2 "SERVICE_DISCOVERY" 1 "SESSION_SETUP" 0 "SUPPORTED_APP_PROTOCOL" ;
VAL_ 1294 CP_a072_currentMessage 17 "NUM_MSG" 16 "MSG_NONE" 15 "SESSION_STOP" 14 "WELDING_DETECTION" 13 "POWER_DELIVERY_END" 12 "CHARGING_STATUS" 11 "CURRENT_DEMAND" 10 "POWER_DELIVERY_START" 9 "PRECHARGE" 8 "CABLE_CHECK" 7 "CHARGE_PARAMETER_DISCOVERY" 6 "CONTRACT_AUTHENTICATION" 5 "PAYMENT_DETAILS" 4 "SERVICE_PAYMENT_SELECTION" 3 "SERVICE_DETAIL" 2 "SERVICE_DISCOVERY" 1 "SESSION_SETUP" 0 "SUPPORTED_APP_PROTOCOL" ;
VAL_ 1294 CP_a074_slacState 14 "NUM_STATES" 13 "WAIT_FOR_RETRY" 12 "FAILED" 11 "JOINED" 10 "MATCHED" 9 "WAIT_FOR_SET_KEY_CNF" 8 "WAIT_FOR_MATCH_CNF" 7 "FIND_MATCH" 6 "WAIT_FOR_ATTEN_CHAR" 5 "SEND_MSOUNDS" 4 "SEND_START_ATTEN" 3 "WAIT_FOR_PARM_CNF" 2 "IDLE" 1 "DISCONNECTED" 0 "INIT" ;
VAL_ 1294 CP_a074_slacErrorCode 8 "NO_CABLE" 7 "NO_PILOT" 6 "NO_SET_KEY_CNF" 5 "NO_MATCH_CNF" 4 "NO_EVSE_FOUND" 3 "NO_ATTEN_CHAR" 2 "NO_PARM_CNF" 1 "FAST_CHARGE_PILOT_NO_PROX" 0 "NO_ERROR" ;
VAL_ 1294 CP_a075_evccState 7 "STATE_COUNT" 6 "COMMS_FAULT" 5 "COMMS_PAUSED" 4 "COMMS_SHUTDOWN" 3 "COMMS_TIMEOUT" 2 "COMMS_ESTABLISHED" 1 "WAIT_FOR_HANDSHAKE" 0 "INIT" ;
VAL_ 1294 CP_a075_currentMessage 17 "NUM_MSG" 16 "MSG_NONE" 15 "SESSION_STOP" 14 "WELDING_DETECTION" 13 "POWER_DELIVERY_END" 12 "CHARGING_STATUS" 11 "CURRENT_DEMAND" 10 "POWER_DELIVERY_START" 9 "PRECHARGE" 8 "CABLE_CHECK" 7 "CHARGE_PARAMETER_DISCOVERY" 6 "CONTRACT_AUTHENTICATION" 5 "PAYMENT_DETAILS" 4 "SERVICE_PAYMENT_SELECTION" 3 "SERVICE_DETAIL" 2 "SERVICE_DISCOVERY" 1 "SESSION_SETUP" 0 "SUPPORTED_APP_PROTOCOL" ;
VAL_ 1294 CP_a075_initFailureType 3 "TLS_HANDSHAKE" 2 "SOCKET_OPTIONS" 1 "TCP_CONNECT" 0 "EVCC_NO_FAILURE" ;
VAL_ 1294 CP_a075_evccSocketErrTx 21 "NUM" 20 "ARG" 19 "CLSD" 18 "RST" 17 "ABRT" 16 "IF" 15 "CONN" 14 "ISCONN" 13 "ALREADY" 12 "USE" 11 "WOULDBLOCK" 10 "VAL" 9 "INPROGRESS" 8 "RTE" 7 "TIMEOUT" 6 "BUF" 5 "MEM" 4 "SEND_FAILED" 3 "RECV_FAILED" 2 "CONNECT_FAILED" 1 "INVALID_ARGS" 0 "NONE" ;
VAL_ 1294 CP_a075_evccSocketErrRx 21 "NUM" 20 "ARG" 19 "CLSD" 18 "RST" 17 "ABRT" 16 "IF" 15 "CONN" 14 "ISCONN" 13 "ALREADY" 12 "USE" 11 "WOULDBLOCK" 10 "VAL" 9 "INPROGRESS" 8 "RTE" 7 "TIMEOUT" 6 "BUF" 5 "MEM" 4 "SEND_FAILED" 3 "RECV_FAILED" 2 "CONNECT_FAILED" 1 "INVALID_ARGS" 0 "NONE" ;
VAL_ 1294 CP_a075_commsFailReason 10 "SIZE_MISMATCH" 9 "RECV_FIN" 8 "RECV_ERROR" 7 "SEND_ERROR" 6 "RECV_TIMEOUT" 5 "PROTOCOL_FAULT" 4 "HANDSHAKE_TIMEOUT2" 3 "HANDSHAKE_TIMEOUT1" 2 "HANDSHAKE_INVALID" 1 "INIT" 0 "NONE" ;
VAL_ 1294 CP_a078_VC_tempAmbientFiltered 0 "SNA" ;
VAL_ 1294 CP_a078_pinTemperature1 255 "SNA" ;
VAL_ 1294 CP_a078_pinTemperature2 255 "SNA" ;
VAL_ 1294 CP_a078_pinTemperature3 255 "SNA" ;
VAL_ 1294 CP_a079_VC_tempAmbientFiltered 0 "SNA" ;
VAL_ 1294 CP_a079_pinTemperature1 255 "SNA" ;
VAL_ 1294 CP_a079_pinTemperature2 255 "SNA" ;
VAL_ 1294 CP_a079_pinTemperature3 255 "SNA" ;
VAL_ 1294 CP_a089_gtwPlcSupportType 2 "NATIVE_CHARGE_PORT" 1 "GEN3_EU_CP" 0 "NONE" ;
VAL_ 1294 CP_a090_evseIsoStatus 4 "NO_IMD" 3 "FAULT" 2 "WARNING" 1 "VALID" 0 "INVALID" ;
VAL_ 1294 CP_a090_ccsDcState 8 "FAULTED" 7 "WAIT_RESTART" 6 "END_OF_CHARGE" 5 "SHUTDOWN" 4 "ENABLED" 3 "PRECHARGE" 2 "CABLE_CHECK" 1 "CHARGE_PARAM_DISCOVERY" 0 "IDLE" ;
VAL_ 1294 CP_a091_fcType 7 "SNA" 6 "OTHER" 5 "MC_EVSE" 4 "COMBO" 3 "CC_EVSE" 2 "GB" 1 "CHADEMO" 0 "SUPERCHARGER" ;
VAL_ 1294 CP_a095_fcType 7 "SNA" 6 "OTHER" 5 "MC_EVSE" 4 "COMBO" 3 "CC_EVSE" 2 "GB" 1 "CHADEMO" 0 "SUPERCHARGER" ;
VAL_ 1294 CP_a095_fcBrand 1 "TESLA" 0 "SNA" ;
VAL_ 1294 CP_a099_proximity 3 "LATCHED" 2 "UNLATCHED" 1 "DISCONNECTED" 0 "SNA" ;
VAL_ 1294 CP_a099_pilot 7 "SNA" 6 "UNUSED_6" 5 "INVALID" 4 "IDLE" 3 "FAST_CHARGE" 2 "LINE_CHARGE" 1 "FAULTED" 0 "NONE" ;
VAL_ 1294 CP_a110_thermalVelocity 511 "SNA" ;
VAL_ 1294 CP_a111_heaterTemperature 255 "SNA" ;
VAL_ 1294 CP_a111_VC_tempAmbientFiltered 0 "SNA" ;
VAL_ 1294 CP_a112_heaterTemperature 255 "SNA" ;
VAL_ 1294 CP_a113_heaterTemperature 255 "SNA" ;
VAL_ 1294 CP_a117_heaterTemperature 255 "SNA" ;
VAL_ 1294 CP_a117_averageError 255 "SNA" ;
VAL_ 1294 CP_a120_dcPinTemp 255 "SNA" ;
VAL_ 1294 CP_a120_cableType 5 "SNA" 4 "MCS" 3 "GB_DC" 2 "GB_AC" 1 "SAE" 0 "IEC" ;
VAL_ 1294 CP_a124_ivledState 3 "FADING_OUT" 2 "ON" 1 "FADING_IN" 0 "OFF" ;
VAL_ 1294 CP_a129_bldcDriverState 3 "READY" 2 "I2C_ERROR" 1 "INIT" 0 "UNPOWERED" ;
VAL_ 1294 CP_a131_powerTransferProtocol 7 "V2X" 6 "CHADEMO" 5 "GBDC" 4 "CCS_AC" 3 "CCS_DC" 2 "SUPERCHARGER" 1 "AC_CHARGE" 0 "NO_CHARGE" ;
VAL_ 1294 CP_a135_sdpErr 4 "NUM_OF_ERRS" 3 "ERR_INVALID_DATA" 2 "ERR_NO_RX_DATA" 1 "ERR_INVALID_ARG" 0 "ERR_NONE" ;
VAL_ 1294 CP_a135_pilotState 7 "SNA" 6 "UNUSED_6" 5 "INVALID" 4 "IDLE" 3 "FAST_CHARGE" 2 "LINE_CHARGE" 1 "FAULTED" 0 "NONE" ;
VAL_ 1294 CP_a138_FC_type 7 "SNA" 6 "OTHER" 5 "MC_EVSE" 4 "COMBO" 3 "CC_EVSE" 2 "GB" 1 "CHADEMO" 0 "SUPERCHARGER" ;
VAL_ 1294 CP_a138_latchState 3 "BLOCKING" 2 "ENGAGED" 1 "DISENGAGED" 0 "SNA" ;
VAL_ 1294 CP_a138_CP_proximity 3 "LATCHED" 2 "UNLATCHED" 1 "DISCONNECTED" 0 "SNA" ;
VAL_ 1294 CP_a139_latchState 3 "BLOCKING" 2 "ENGAGED" 1 "DISENGAGED" 0 "SNA" ;
VAL_ 1294 CP_a139_CP_proximity 3 "LATCHED" 2 "UNLATCHED" 1 "DISCONNECTED" 0 "SNA" ;
VAL_ 1294 CP_a140_latchState 3 "BLOCKING" 2 "ENGAGED" 1 "DISENGAGED" 0 "SNA" ;
VAL_ 1294 CP_a140_CP_proximity 3 "LATCHED" 2 "UNLATCHED" 1 "DISCONNECTED" 0 "SNA" ;
VAL_ 1294 CP_a141_latchState 3 "BLOCKING" 2 "ENGAGED" 1 "DISENGAGED" 0 "SNA" ;
VAL_ 1294 CP_a141_CP_proximity 3 "LATCHED" 2 "UNLATCHED" 1 "DISCONNECTED" 0 "SNA" ;
VAL_ 1294 CP_a146_v2gMessage 17 "NUM_MSG" 16 "MSG_NONE" 15 "SESSION_STOP" 14 "WELDING_DETECTION" 13 "POWER_DELIVERY_END" 12 "CHARGING_STATUS" 11 "CURRENT_DEMAND" 10 "POWER_DELIVERY_START" 9 "PRECHARGE" 8 "CABLE_CHECK" 7 "CHARGE_PARAMETER_DISCOVERY" 6 "CONTRACT_AUTHENTICATION" 5 "PAYMENT_DETAILS" 4 "SERVICE_PAYMENT_SELECTION" 3 "SERVICE_DETAIL" 2 "SERVICE_DISCOVERY" 1 "SESSION_SETUP" 0 "SUPPORTED_APP_PROTOCOL" ;
VAL_ 1294 CP_a153_acPinTempVelocity 511 "SNA" ;
VAL_ 1294 CP_a153_acPinTemp1 255 "SNA" ;
VAL_ 1294 CP_a153_acPinTemp2 255 "SNA" ;
VAL_ 1294 CP_a154_acPinTempVelocity 511 "SNA" ;
VAL_ 1294 CP_a154_acPinTemp1 255 "SNA" ;
VAL_ 1294 CP_a154_acPinTemp2 255 "SNA" ;
VAL_ 1294 CP_a163_cover1State 4 "SNA" 3 "SHORT_TO_VBAT" 2 "SHORT_TO_GND" 1 "OPEN" 0 "CLOSED" ;
VAL_ 1294 CP_a163_cover2State 4 "SNA" 3 "SHORT_TO_VBAT" 2 "SHORT_TO_GND" 1 "OPEN" 0 "CLOSED" ;
VAL_ 1294 CP_a164_VC_tempAmbientFiltered 0 "SNA" ;
VAL_ 1294 CP_a164_minInternalPinTemp 255 "SNA" ;
VAL_ 1294 CP_a173_cover1State 4 "SNA" 3 "SHORT_TO_VBAT" 2 "SHORT_TO_GND" 1 "OPEN" 0 "CLOSED" ;
VAL_ 1294 CP_a173_cover2State 4 "SNA" 3 "SHORT_TO_VBAT" 2 "SHORT_TO_GND" 1 "OPEN" 0 "CLOSED" ;
VAL_ 1294 CP_a205_bldcMotorState 3 "READY" 2 "I2C_ERROR" 1 "INIT" 0 "UNPOWERED" ;
